VERSION ""

NS_ :

BS_:

BU_: FR_CMR FD_E CLU DATC RR_C_RDR CGW

BO_ 549 CLU_02_100ms: 16 CLU
 SG_ CLU_Crc2Val : 0|16@1+ (1,0) [0|0] ""  FR_CMR,CGW
 SG_ CLU_RefuelWrnSta : 100|2@1+ (1,0) [0|0] ""  CGW
 SG_ CLU_DrvngModSwSta : 104|4@1+ (1,0) [0|0] ""  DATC,FR_CMR,CGW
 SG_ CLU_FuelLvlSta : 108|7@1+ (1,0) [0|0] "%"  CGW
 SG_ CLU_OutTempFSta : 115|8@1+ (1,-40) [0|0] ""  CGW
 SG_ CLU_TerrainModSwSta : 123|3@1+ (1,0) [0|0] ""  CGW
 SG_ CLU_AlvCnt2Val : 16|8@1+ (1,0) [0|0] ""  FR_CMR,CGW
 SG_ CLU_OutTempCSta : 24|8@1+ (1,-40) [0|0] ""  FR_CMR,CGW
 SG_ CLU_DTEVal : 32|10@1+ (1,0) [0|0] ""  CGW
 SG_ CLU_TripUnitSta : 44|2@1+ (1,0) [0|0] ""  CGW
 SG_ CLU_AvgFuelCnsmptnVal : 46|10@1+ (0.1,0) [0|0] ""  CGW
 SG_ CLU_AvgFuelCnsmptnUnitSta : 56|2@1+ (1,0) [0|0] ""  CGW
 SG_ CLU_LoFuelWrngSta : 58|2@1+ (1,0) [0|0] ""  CGW
 SG_ CLU_RefuelDetSta : 60|2@1+ (1,0) [0|0] ""  CGW
 SG_ CLU_TerrainMainSwSta : 62|2@1+ (1,0) [0|0] ""  CGW
 SG_ CLU_LngSta : 64|5@1+ (1,0) [0|0] ""  CGW
 SG_ CLU_SRSWrngLmpSta : 69|3@1+ (1,0) [0|0] ""  CGW
 SG_ CLU_OdoVal : 72|24@1+ (0.1,0) [0|0] "km"  RR_C_RDR,CGW
 SG_ CLU_DawLastBrkTimeVal : 96|4@1+ (1,0) [0|0] ""  FR_CMR,CGW

BO_ 1099 WPC_01_200ms: 8 CGW
 SG_ USM_CmdWPCSta : 0|2@1+ (1,0) [0|0] ""  CLU
 SG_ WPC_PhnLftWrngSta : 2|3@1+ (1,0) [0|0] ""  CLU

BO_ 1092 SMK_02_200ms: 8 CGW
 SG_ SMK_AuthSta : 29|3@1+ (1,0) [0|0] ""  CLU
 SG_ SMK_CLUAccIndOnReq : 48|2@1+ (1,0) [0|0] ""  CLU

BO_ 282 FR_CMR_01_10ms: 16 FR_CMR
 SG_ HBA_SysOptSta : 24|2@1+ (1,0) [0|0] ""  CLU,CGW
 SG_ HBA_SysSta : 26|3@1+ (1,0) [0|0] ""  CLU,CGW
 SG_ HBA_IndLmpReq : 29|2@1+ (1,0) [0|0] ""  CLU,CGW
 SG_ DAW_LVDA_PUDis : 48|2@1+ (1,0) [0|0] ""  CLU,CGW
 SG_ DAW_LVDA_OptUsmSta : 50|2@1+ (1,0) [0|0] ""  CLU,CGW
 SG_ DAW_OptUsmSta : 52|3@1+ (1,0) [0|0] ""  CLU,CGW
 SG_ DAW_SysSta : 55|4@1+ (1,0) [0|0] ""  CLU,CGW
 SG_ DAW_WrnMsgSta : 59|3@1+ (1,0) [0|0] ""  CLU,CGW
 SG_ DAW_TimeRstReq : 62|2@1+ (1,0) [0|0] ""  CLU,CGW
 SG_ DAW_SnstvtyModRetVal : 64|3@1+ (1,0) [0|0] ""  CLU,CGW

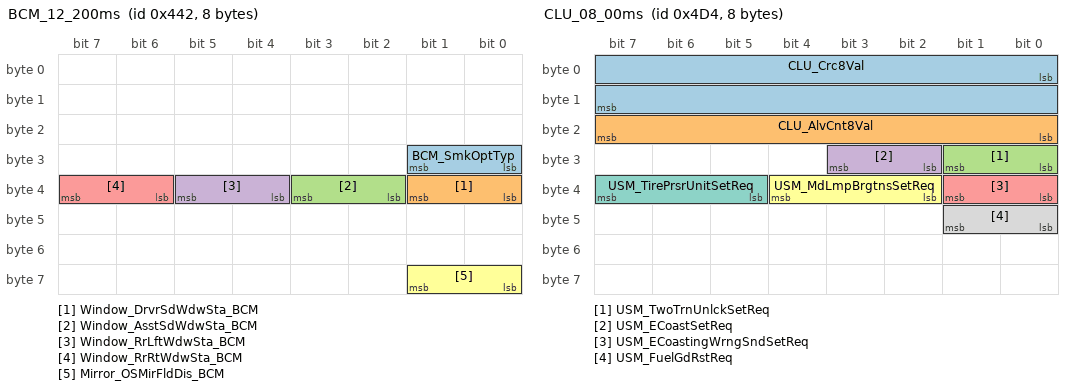
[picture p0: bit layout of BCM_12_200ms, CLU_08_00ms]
BO_ 1090 BCM_12_200ms: 8 CGW
 SG_ BCM_SmkOptTyp : 24|2@1+ (1,0) [0|0] ""  CLU
 SG_ Window_DrvrSdWdwSta_BCM : 32|2@1+ (1,0) [0|0] ""  CLU
 SG_ Window_AsstSdWdwSta_BCM : 34|2@1+ (1,0) [0|0] ""  CLU
 SG_ Window_RrLftWdwSta_BCM : 36|2@1+ (1,0) [0|0] ""  CLU
 SG_ Window_RrRtWdwSta_BCM : 38|2@1+ (1,0) [0|0] ""  CLU
 SG_ Mirror_OSMirFldDis_BCM : 56|2@1+ (1,0) [0|0] ""  CLU

BO_ 1236 CLU_08_00ms: 8 CLU
 SG_ CLU_Crc8Val : 0|16@1+ (1,0) [0|0] ""  CGW
 SG_ CLU_AlvCnt8Val : 16|8@1+ (1,0) [0|0] ""  CGW
 SG_ USM_TwoTrnUnlckSetReq : 24|2@1+ (1,0) [0|0] ""  CGW
 SG_ USM_ECoastSetReq : 26|2@1+ (1,0) [0|0] ""  CGW
 SG_ USM_ECoastingWrngSndSetReq : 32|2@1+ (1,0) [0|0] ""  CGW
 SG_ USM_MdLmpBrgtnsSetReq : 34|3@1+ (1,0) [0|0] ""  CGW
 SG_ USM_TirePrsrUnitSetReq : 37|3@1+ (1,0) [0|0] ""  CGW
 SG_ USM_FuelGdRstReq : 40|2@1+ (1,0) [0|0] ""  CGW

BO_ 256 EMS_02_10ms: 32 CGW
 SG_ ACC_CrsMainSwLmpSta : 104|2@1+ (1,0) [0|0] ""  CLU
 SG_ ACC_CrsSetSwLmpSta : 106|2@1+ (1,0) [0|0] ""  CLU
 SG_ ENG_DpfWrngSta : 232|2@1+ (1,0) [0|0] ""  CLU
 SG_ ENG_BattWrngLmpSta : 234|2@1+ (1,0) [0|0] ""  CLU
 SG_ ENG_OilPrsrWrngLmpSta : 236|2@1+ (1,0) [0|0] ""  CLU
 SG_ ENG_EngClntTempVal : 40|8@1+ (0.75,-48) [0|0] "℃"  CLU,DATC
 SG_ ENG_EngSta : 61|3@1+ (1,0) [0|0] ""  CLU,FR_CMR,RR_C_RDR

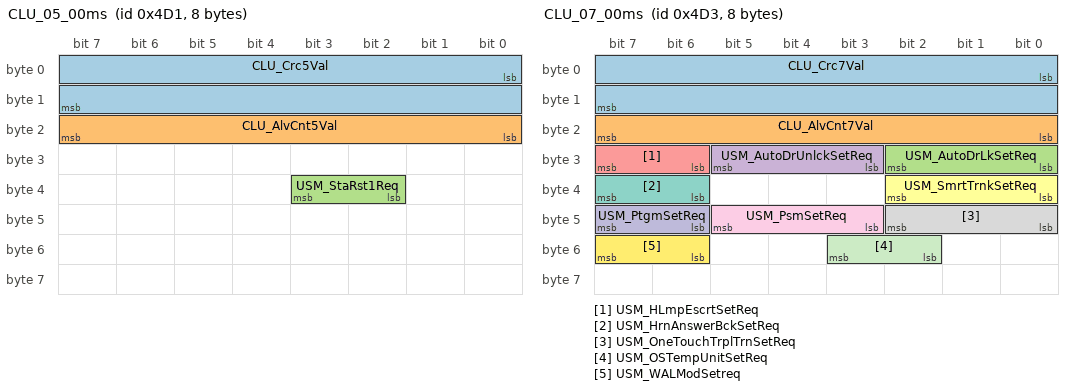
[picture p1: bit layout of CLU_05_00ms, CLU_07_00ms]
BO_ 1233 CLU_05_00ms: 8 CLU
 SG_ CLU_Crc5Val : 0|16@1+ (1,0) [0|0] ""  CGW
 SG_ CLU_AlvCnt5Val : 16|8@1+ (1,0) [0|0] ""  CGW
 SG_ USM_StaRst1Req : 34|2@1+ (1,0) [0|0] ""  DATC,FR_CMR,CGW

BO_ 1235 CLU_07_00ms: 8 CLU
 SG_ CLU_Crc7Val : 0|16@1+ (1,0) [0|0] ""  CGW
 SG_ CLU_AlvCnt7Val : 16|8@1+ (1,0) [0|0] ""  CGW
 SG_ USM_AutoDrLkSetReq : 24|3@1+ (1,0) [0|0] ""  CGW
 SG_ USM_AutoDrUnlckSetReq : 27|3@1+ (1,0) [0|0] ""  CGW
 SG_ USM_HLmpEscrtSetReq : 30|2@1+ (1,0) [0|0] ""  CGW
 SG_ USM_SmrtTrnkSetReq : 32|3@1+ (1,0) [0|0] ""  CGW
 SG_ USM_HrnAnswerBckSetReq : 38|2@1+ (1,0) [0|0] ""  CGW
 SG_ USM_OneTouchTrplTrnSetReq : 40|3@1+ (1,0) [0|0] ""  CGW
 SG_ USM_PsmSetReq : 43|3@1+ (1,0) [0|0] ""  CGW
 SG_ USM_PtgmSetReq : 46|2@1+ (1,0) [0|0] ""  CGW
 SG_ USM_OSTempUnitSetReq : 50|2@1+ (1,0) [0|0] ""  CGW
 SG_ USM_WALModSetreq : 54|2@1+ (1,0) [0|0] ""  CGW

BO_ 933 SCU_FF_02_100ms: 8 CGW
 SG_ SCU_FF_WrnMsgClu : 24|5@1+ (1,0) [0|0] ""  CLU
 SG_ SCU_FF_NPosWshModSta : 43|2@1+ (1,-40) [0|0] "℃"  CLU

BO_ 934 PTGM_01_200ms: 8 CGW
 SG_ PTGM_UsmSetSta : 28|2@1+ (1,0) [0|0] ""  CLU
 SG_ PTGM_HeightSetWarn : 47|1@1+ (1,0) [0|0] ""  CLU

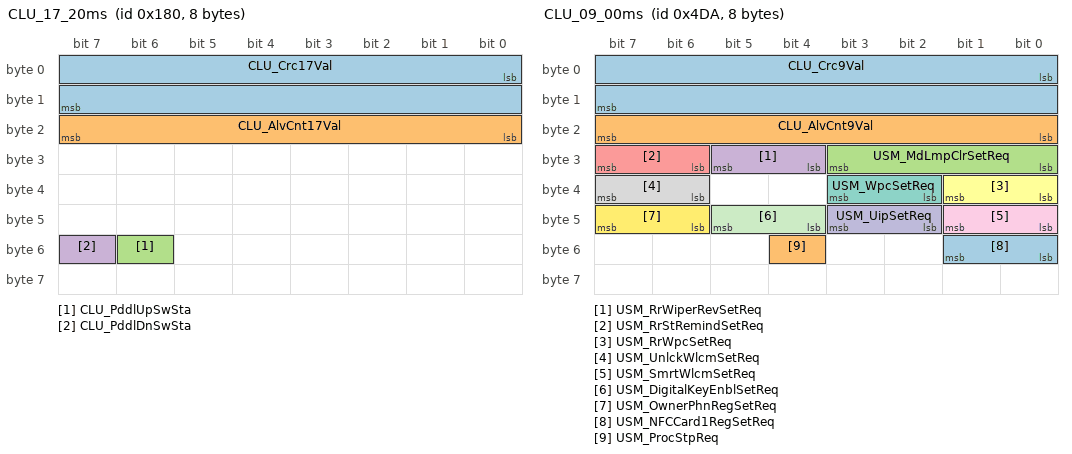
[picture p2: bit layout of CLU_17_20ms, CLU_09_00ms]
BO_ 384 CLU_17_20ms: 8 CLU
 SG_ CLU_Crc17Val : 0|16@1+ (1,0) [0|0] ""  Vector__XXX
 SG_ CLU_AlvCnt17Val : 16|8@1+ (1,0) [0|0] ""  Vector__XXX
 SG_ CLU_PddlUpSwSta : 54|1@1+ (1,0) [0|0] ""  CGW
 SG_ CLU_PddlDnSwSta : 55|1@1+ (1,0) [0|0] ""  CGW

BO_ 928 TPMS_01_200ms: 16 CGW
 SG_ TPMS_FLPosWrngLmpSta : 24|2@1+ (1,0) [0|0] ""  CLU
 SG_ TPMS_FRPosWrngLmpSta : 26|2@1+ (1,0) [0|0] ""  CLU
 SG_ TPMS_RLPosWrngLmpSta : 28|2@1+ (1,0) [0|0] ""  CLU
 SG_ TPMS_RRPosWrngLmpSta : 30|2@1+ (1,0) [0|0] ""  CLU
 SG_ TPMS_FLTirePrsrVal : 32|8@1+ (1,0) [0|0] "PSI"  CLU
 SG_ TPMS_FRTirePrsrVal : 40|8@1+ (1,0) [0|0] "PSI"  CLU
 SG_ TPMS_RLTirePrsrVal : 48|8@1+ (1,0) [0|0] "PSI"  CLU
 SG_ TPMS_RRTirePrsrVal : 56|8@1+ (1,0) [0|0] "PSI"  CLU
 SG_ TPMS_SnsrSta : 64|3@1+ (1,0) [0|0] ""  CLU
 SG_ TPMS_WrngLmpSta : 67|2@1+ (1,0) [0|0] ""  CLU
 SG_ TPMS_TreadWrngLmpSta : 69|2@1+ (1,0) [0|0] ""  CLU
 SG_ TPMS_PrsrUnitSta : 72|2@1+ (1,0) [0|0] ""  CLU

BO_ 1242 CLU_09_00ms: 8 CLU
 SG_ CLU_Crc9Val : 0|16@1+ (1,0) [0|0] ""  CGW
 SG_ CLU_AlvCnt9Val : 16|8@1+ (1,0) [0|0] ""  Vector__XXX
 SG_ USM_MdLmpClrSetReq : 24|4@1+ (1,0) [0|0] ""  CGW
 SG_ USM_RrWiperRevSetReq : 28|2@1+ (1,0) [0|0] ""  CGW
 SG_ USM_RrStRemindSetReq : 30|2@1+ (1,0) [0|0] ""  CGW
 SG_ USM_RrWpcSetReq : 32|2@1+ (1,0) [0|0] ""  CGW
 SG_ USM_WpcSetReq : 34|2@1+ (1,0) [0|0] ""  CGW
 SG_ USM_UnlckWlcmSetReq : 38|2@1+ (1,0) [0|0] ""  CGW
 SG_ USM_SmrtWlcmSetReq : 40|2@1+ (1,0) [0|0] ""  CGW
 SG_ USM_UipSetReq : 42|2@1+ (1,0) [0|0] ""  Vector__XXX
 SG_ USM_DigitalKeyEnblSetReq : 44|2@1+ (1,0) [0|0] ""  Vector__XXX
 SG_ USM_OwnerPhnRegSetReq : 46|2@1+ (1,0) [0|0] ""  Vector__XXX
 SG_ USM_NFCCard1RegSetReq : 48|2@1+ (1,0) [0|0] ""  Vector__XXX
 SG_ USM_ProcStpReq : 52|1@1+ (1,0) [0|0] ""  Vector__XXX

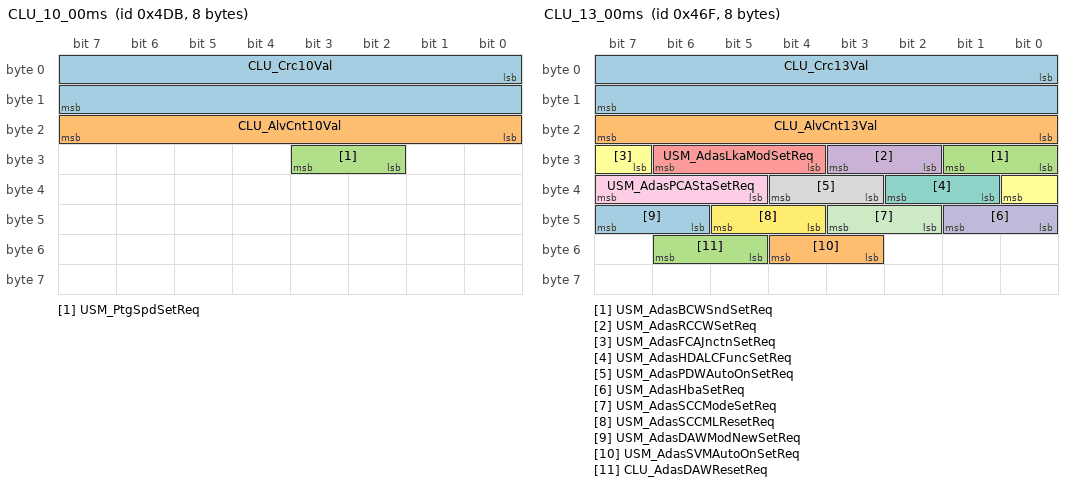
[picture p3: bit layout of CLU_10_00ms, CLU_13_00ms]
BO_ 1243 CLU_10_00ms: 8 CLU
 SG_ CLU_Crc10Val : 0|16@1+ (1,0) [0|0] ""  Vector__XXX
 SG_ CLU_AlvCnt10Val : 16|8@1+ (1,0) [0|0] ""  Vector__XXX
 SG_ USM_PtgSpdSetReq : 26|2@1+ (1,0) [0|0] ""  Vector__XXX

BO_ 304 SBW_SHFTR_FF_01_10ms: 16 CGW
 SG_ SBW_SHFTR_FF_LvrWrngMsg : 56|5@1+ (1,0) [0|0] ""  CLU

BO_ 1135 CLU_13_00ms: 8 CLU
 SG_ CLU_Crc13Val : 0|16@1+ (1,0) [0|0] ""  FR_CMR
 SG_ CLU_AlvCnt13Val : 16|8@1+ (1,0) [0|0] ""  FR_CMR
 SG_ USM_AdasBCWSndSetReq : 24|2@1+ (1,0) [0|0] ""  Vector__XXX
 SG_ USM_AdasRCCWSetReq : 26|2@1+ (1,0) [0|0] ""  RR_C_RDR
 SG_ USM_AdasLkaModSetReq : 28|3@1+ (1,0) [0|0] ""  FR_CMR
 SG_ USM_AdasFCAJnctnSetReq : 31|2@1+ (1,0) [0|0] ""  Vector__XXX
 SG_ USM_AdasHDALCFuncSetReq : 33|2@1+ (1,0) [0|0] ""  Vector__XXX
 SG_ USM_AdasPDWAutoOnSetReq : 35|2@1+ (1,0) [0|0] ""  CGW
 SG_ USM_AdasPCAStaSetReq : 37|3@1+ (1,0) [0|0] ""  Vector__XXX
 SG_ USM_AdasHbaSetReq : 40|2@1+ (1,0) [0|0] ""  FR_CMR
 SG_ USM_AdasSCCModeSetReq : 42|2@1+ (1,0) [0|0] ""  Vector__XXX
 SG_ USM_AdasSCCMLResetReq : 44|2@1+ (1,0) [0|0] ""  Vector__XXX
 SG_ USM_AdasDAWModNewSetReq : 46|2@1+ (1,0) [0|0] ""  FR_CMR
 SG_ USM_AdasSVMAutoOnSetReq : 51|2@1+ (1,0) [0|0] ""  Vector__XXX
 SG_ CLU_AdasDAWResetReq : 53|2@1+ (1,0) [0|0] ""  FR_CMR

BO_ 1253 SMK_01_00ms: 8 CGW
 SG_ DoorLock_PsvDrLkReq : 16|3@1+ (1,0) [0|0] ""  CLU
 SG_ DoorLock_PsvDrUnLkReq : 19|3@1+ (1,0) [0|0] ""  CLU

BO_ 442 RR_C_RDR_02_50ms: 24 RR_C_RDR
 SG_ BCW_Sta : 24|4@1+ (1,0) [0|0] ""  CLU,CGW
 SG_ BCW_LftIndSta : 30|2@1+ (1,0) [0|0] ""  CLU,CGW
 SG_ BCW_RtIndSta : 32|2@1+ (1,0) [0|0] ""  CLU,CGW
 SG_ BCW_LftSndWrngSta : 34|2@1+ (1,0) [0|0] ""  CLU,CGW
 SG_ BCW_RtSndWrngSta : 36|2@1+ (1,0) [0|0] ""  CLU,CGW
 SG_ BCW_LftIndBriLvlVal : 40|8@1+ (1,0) [0|0] ""  CLU,CGW
 SG_ BCW_RtIndBriLvlVal : 48|8@1+ (1,0) [0|0] ""  CLU,CGW
 SG_ BCW_SnstvtyModRetVal : 56|3@1+ (1,0) [0|0] ""  CLU,CGW
 SG_ BCW_IndSta : 59|2@1+ (1,0) [0|0] ""  CLU,CGW
 SG_ BCA_Sta : 64|4@1+ (1,0) [0|0] ""  CLU,CGW
 SG_ BCA_OnOffEquipSta : 68|3@1+ (1,0) [0|0] ""  CLU,CGW
 SG_ BCA_LftWrngSta : 72|2@1+ (1,0) [0|0] ""  CLU,CGW
 SG_ BCA_RtWrngSta : 74|2@1+ (1,0) [0|0] ""  CLU,CGW
 SG_ BCA_R_Brake_Warning : 76|3@1+ (1,0) [0|0] ""  CLU,CGW
 SG_ BCA_Plus_LftWrngSta : 86|2@1+ (1,0) [0|0] ""  CLU,CGW
 SG_ BCA_Plus_RtWrngSta : 88|2@1+ (1,0) [0|0] ""  CLU,CGW
 SG_ BCA_Plus_Sta : 96|4@1+ (1,0) [0|0] ""  CLU,CGW

BO_ 1252 RKE_01_00ms: 8 CGW
 SG_ RKE_BtnReq : 16|4@1+ (1,0) [0|0] ""  CLU

BO_ 160 WHL_01_10ms: 24 CGW
 SG_ WHL_SpdRRVal : 112|14@1+ (0.03125,0) [0|0] "km^h"  CLU,FR_CMR,RR_C_RDR
 SG_ WHL_SpdFLVal : 64|14@1+ (0.03125,0) [0|0] "km^h"  CLU,FR_CMR,RR_C_RDR
 SG_ WHL_SpdFRVal : 80|14@1+ (0.03125,0) [0|0] "km^h"  CLU,FR_CMR,RR_C_RDR
 SG_ WHL_SpdRLVal : 96|14@1+ (0.03125,0) [0|0] "km^h"  CLU,FR_CMR,RR_C_RDR

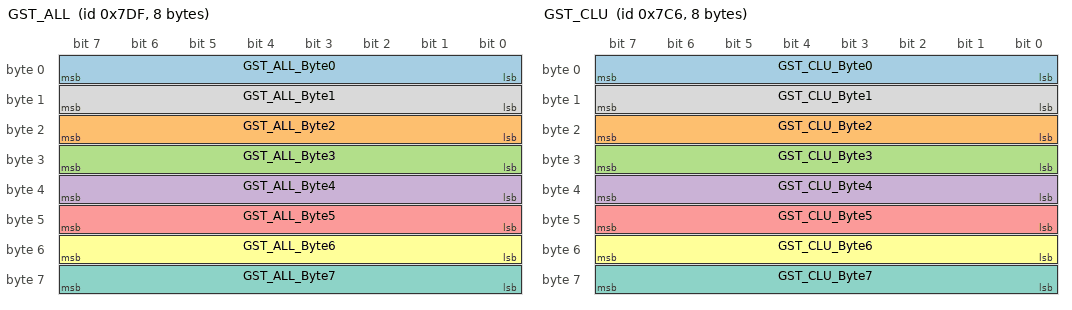
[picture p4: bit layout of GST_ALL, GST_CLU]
BO_ 2015 GST_ALL: 8 CGW
 SG_ GST_ALL_Byte0 : 0|8@1+ (1,0) [0|0] ""  CLU,RR_C_RDR,DATC,FD_E
 SG_ GST_ALL_Byte2 : 16|8@1+ (1,0) [0|0] ""  CLU,RR_C_RDR,DATC,FD_E
 SG_ GST_ALL_Byte3 : 24|8@1+ (1,0) [0|0] ""  CLU,RR_C_RDR,DATC,FD_E
 SG_ GST_ALL_Byte4 : 32|8@1+ (1,0) [0|0] ""  CLU,RR_C_RDR,DATC,FD_E
 SG_ GST_ALL_Byte5 : 40|8@1+ (1,0) [0|0] ""  CLU,RR_C_RDR,DATC,FD_E
 SG_ GST_ALL_Byte6 : 48|8@1+ (1,0) [0|0] ""  CLU,RR_C_RDR,DATC,FD_E
 SG_ GST_ALL_Byte7 : 56|8@1+ (1,0) [0|0] ""  CLU,RR_C_RDR,DATC,FD_E
 SG_ GST_ALL_Byte1 : 8|8@1+ (1,0) [0|0] ""  CLU,RR_C_RDR,DATC,FD_E

BO_ 522 ACU_01_100ms: 16 CGW
 SG_ ACU_SysWrngLmpDis : 24|3@1+ (1,0) [0|0] ""  CLU

BO_ 426 CLU_01_20ms: 16 CLU
 SG_ CLU_Crc1Val : 0|16@1+ (1,0) [0|0] ""  FR_CMR,CGW
 SG_ CLU_AlvCnt1Val : 16|8@1+ (1,0) [0|0] ""  FR_CMR,CGW
 SG_ CLU_PrtyBitSta : 24|2@1+ (1,0) [0|0] "pulse count"  CGW
 SG_ CLU_SpdUnitTyp : 30|2@1+ (1,0) [0|0] ""  FR_CMR,RR_C_RDR,CGW
 SG_ CLU_DisSpdDcmlVal : 32|2@1+ (0.125,0) [0|0] ""  CGW
 SG_ CLU_SWRCCrsMainSwSta : 34|2@1+ (1,0) [0|0] ""  FR_CMR,CGW
 SG_ CLU_SWRCCrsSwSta : 36|3@1+ (1,0) [0|0] ""  FR_CMR,CGW
 SG_ CLU_SWRCLFASwSta : 39|2@1+ (1,0) [0|0] ""  FR_CMR,CGW
 SG_ CLU_SWRCSldMainSwSta : 41|2@1+ (1,0) [0|0] ""  FR_CMR,CGW
 SG_ CLU_RhstaLvlSta : 43|5@1+ (1,0) [0|0] ""  CGW
 SG_ CLU_DisSpdVal : 48|10@1+ (0.5,0) [0|0] "km/h or MPH"  FR_CMR,RR_C_RDR,CGW
 SG_ CLU_OKSwSta : 62|2@1+ (1,0) [0|0] ""  CGW
 SG_ CLU_DisSpdVal_KPH : 64|9@1+ (1,0) [0|0] "km/h"  CGW

BO_ 1990 GST_CLU: 8 CGW
 SG_ GST_CLU_Byte0 : 0|8@1+ (1,0) [0|0] ""  CLU,FD_E
 SG_ GST_CLU_Byte2 : 16|8@1+ (1,0) [0|0] ""  CLU,FD_E
 SG_ GST_CLU_Byte3 : 24|8@1+ (1,0) [0|0] ""  CLU,FD_E
 SG_ GST_CLU_Byte4 : 32|8@1+ (1,0) [0|0] ""  CLU,FD_E
 SG_ GST_CLU_Byte5 : 40|8@1+ (1,0) [0|0] ""  CLU,FD_E
 SG_ GST_CLU_Byte6 : 48|8@1+ (1,0) [0|0] ""  CLU,FD_E
 SG_ GST_CLU_Byte7 : 56|8@1+ (1,0) [0|0] ""  CLU,FD_E
 SG_ GST_CLU_Byte1 : 8|8@1+ (1,0) [0|0] ""  CLU,FD_E

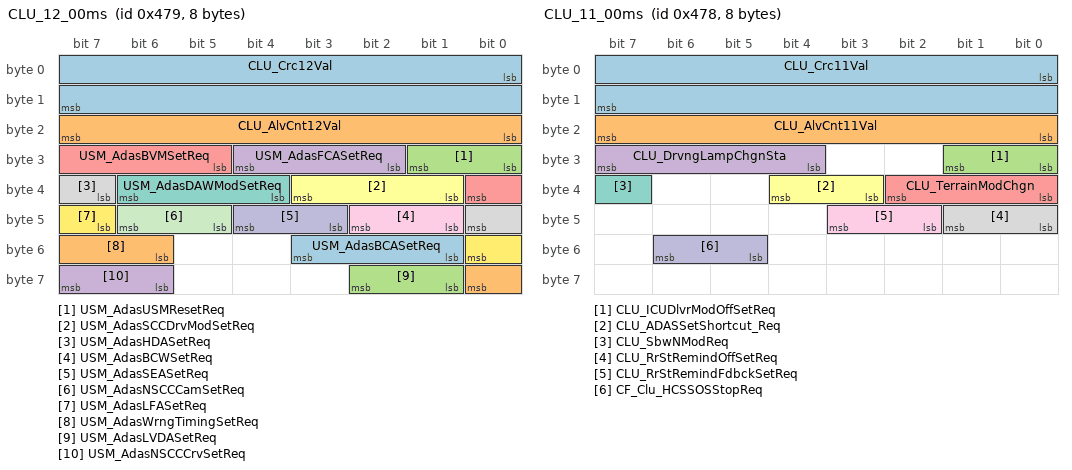
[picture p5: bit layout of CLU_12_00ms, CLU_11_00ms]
BO_ 1145 CLU_12_00ms: 8 CLU
 SG_ CLU_Crc12Val : 0|16@1+ (1,0) [0|0] ""  FR_CMR
 SG_ CLU_AlvCnt12Val : 16|8@1+ (1,0) [0|0] ""  FR_CMR
 SG_ USM_AdasUSMResetReq : 24|2@1+ (1,0) [0|0] ""  FR_CMR,RR_C_RDR
 SG_ USM_AdasFCASetReq : 26|3@1+ (1,0) [0|0] ""  FR_CMR
 SG_ USM_AdasBVMSetReq : 29|4@1+ (1,0) [0|0] ""  Vector__XXX
 SG_ USM_AdasSCCDrvModSetReq : 33|3@1+ (1,0) [0|0] ""  FR_CMR
 SG_ USM_AdasDAWModSetReq : 36|3@1+ (1,0) [0|0] ""  Vector__XXX
 SG_ USM_AdasHDASetReq : 39|2@1+ (1,0) [0|0] ""  FR_CMR
 SG_ USM_AdasBCWSetReq : 41|2@1+ (1,0) [0|0] ""  RR_C_RDR
 SG_ USM_AdasSEASetReq : 43|2@1+ (1,0) [0|0] ""  RR_C_RDR
 SG_ USM_AdasNSCCCamSetReq : 45|2@1+ (1,0) [0|0] ""  FR_CMR
 SG_ USM_AdasLFASetReq : 47|2@1+ (1,0) [0|0] ""  Vector__XXX
 SG_ USM_AdasBCASetReq : 49|3@1+ (1,0) [0|0] ""  RR_C_RDR
 SG_ USM_AdasWrngTimingSetReq : 54|3@1+ (1,0) [0|0] ""  FR_CMR,RR_C_RDR
 SG_ USM_AdasLVDASetReq : 57|2@1+ (1,0) [0|0] ""  FR_CMR
 SG_ USM_AdasNSCCCrvSetReq : 62|2@1+ (1,0) [0|0] ""  CGW

BO_ 1144 CLU_11_00ms: 8 CLU
 SG_ CLU_Crc11Val : 0|16@1+ (1,0) [0|0] ""  Vector__XXX
 SG_ CLU_AlvCnt11Val : 16|8@1+ (1,0) [0|0] ""  Vector__XXX
 SG_ CLU_ICUDlvrModOffSetReq : 24|2@1+ (1,0) [0|0] ""  CGW
 SG_ CLU_DrvngLampChgnSta : 28|4@1+ (1,0) [0|0] ""  CGW
 SG_ CLU_TerrainModChgn : 32|3@1+ (1,0) [0|0] ""  CGW
 SG_ CLU_ADASSetShortcut_Req : 35|2@1+ (1,0) [0|0] ""  Vector__XXX
 SG_ CLU_SbwNModReq : 39|1@1+ (1,0) [0|0] ""  CGW
 SG_ CLU_RrStRemindOffSetReq : 40|2@1+ (1,0) [0|0] ""  CGW
 SG_ CLU_RrStRemindFdbckSetReq : 42|2@1+ (1,0) [0|0] ""  CGW
 SG_ CF_Clu_HCSSOSStopReq : 53|2@1+ (1,0) [0|0] ""  Vector__XXX

BO_ 416 ADAS_CMD_20_20ms: 32 FR_CMR
 SG_ SCC_NSCCOpSta : 104|2@1+ (1,0) [0|0] ""  CLU,CGW
 SG_ SCC_NSCCOnOffSta : 106|2@1+ (1,0) [0|0] ""  CLU,CGW
 SG_ SCC_ObjSta : 108|3@1+ (1,0) [0|0] ""  CLU,CGW
 SG_ SCC_SnstvtyModRetVal : 112|3@1+ (1,0) [0|0] ""  CLU,CGW
 SG_ SCC_NSCCAutoSetSpdUpdtSta : 115|2@1+ (1,0) [0|0] ""  CLU,CGW
 SG_ SCC_NSCCInfoPUDis : 117|3@1+ (1,0) [0|0] ""  CLU,CGW
 SG_ SCC_TrgtDstVal : 192|11@1+ (0.1,0) [0|0] "m"  CLU,CGW
 SG_ SCC_ObjDstVal : 24|11@1+ (0.1,0) [0|0] "m"  CLU,CGW
 SG_ SCC_ObjLatPosVal : 47|9@1+ (0.1,-20) [0|0] "m"  CLU,CGW
 SG_ SCC_SysFlrSta : 64|2@1+ (1,0) [0|0] ""  CLU,CGW
 SG_ SCC_MainOnOffSta : 66|2@1+ (1,0) [0|0] ""  CLU,CGW
 SG_ SCC_OpSta : 68|3@1+ (1,0) [0|0] ""  CLU,CGW
 SG_ SCC_TakeoverReq : 72|2@1+ (1,0) [0|0] ""  CLU,CGW
 SG_ SCC_InfoDis : 74|3@1+ (1,0) [0|0] ""  CLU,CGW
 SG_ SCC_DrvAlrtDis : 77|2@1+ (1,0) [0|0] ""  CLU,CGW
 SG_ SCC_ObjDstLvlVal : 80|8@1+ (1,0) [0|0] ""  CLU,CGW
 SG_ SCC_HeadwayDstSetVal : 88|4@1+ (1,0) [0|0] ""  CLU,CGW
 SG_ SCC_NSCCAutoSetSpdSta : 94|2@1+ (1,0) [0|0] ""  CLU,CGW
 SG_ SCC_TrgtSpdSetVal : 96|8@1+ (1,0) [0|0] "km/h or MPH"  CLU,CGW

CM_ BO_ 522 "[P] Periodic";
CM_ SG_ 522 ACU_SysWrngLmpDis "ACU_SystemWarningLampDisplay ##2G##ACU - ACU14 - CF_SWL_Ind";
CM_ BO_ 416 "[P] Periodic";
CM_ SG_ 416 SCC_NSCCOpSta "SCC_NSCCOperatingStatus ##2G##SCC - SCC11 - NSCC_Camera_Act";
CM_ SG_ 416 SCC_NSCCOnOffSta "SCC_NSCCOnOffStatus ##2G##SCC - SCC13 - NSCC_Zone_USM";
CM_ SG_ 416 SCC_ObjSta "SCC_ObjectState";
CM_ SG_ 416 SCC_SnstvtyModRetVal "SCC_SensitivityModeReturnValue ##2G##SCC - SCC13 - SCCDrvModeRValue";
CM_ SG_ 416 SCC_NSCCAutoSetSpdUpdtSta "SCC_NSCCAutoSetSpeedUpdateStatus ##2G##LDW_LKA - HDA11 - CF_HDA_AutoSetSpdUpdate";
CM_ SG_ 416 SCC_NSCCInfoPUDis "SCC_NSCCInformationPopUpDisplay";
CM_ SG_ 416 SCC_TrgtDstVal "SCC_TargetDistanceValue";
CM_ SG_ 416 SCC_ObjDstVal "SCC_ObjectDistanceValue ##2G##SCC - SCC11 - SCC_ObjDist";
CM_ SG_ 416 SCC_ObjLatPosVal "SCC_ObjectLateralPositionValue ##2G##SCC - SCC11 - SCC_ObjLatPos";
CM_ SG_ 416 SCC_SysFlrSta "SCC_SystemFailureStatus ##2G##SCC - SCC12 - SCCFailInfo";
CM_ SG_ 416 SCC_MainOnOffSta "SCC_MainOnOffStatus ##2G##SCC - SCC11 - MainMode_SCC";
CM_ SG_ 416 SCC_OpSta "SCC_OperatingStatus ##2G##SCC - SCC14 - SCCMode2";
CM_ SG_ 416 SCC_TakeoverReq "SCC_TakeoverRequest ##2G##SCC - SCC12 - TakeOverReq";
CM_ SG_ 416 SCC_InfoDis "SCC_InformationDisplay ##2G##SCC - SCC11 - SCCInfoDisplay";
CM_ SG_ 416 SCC_DrvAlrtDis "SCC_DriverAlertDisplay ##2G##SCC - SCC11 - DriverAlertDisplay";
CM_ SG_ 416 SCC_ObjDstLvlVal "SCC_ObjectDistanceLevelValue ##2G##SCC - SCC14 - ObjGap";
CM_ SG_ 416 SCC_HeadwayDstSetVal "SCC_HeadwayDistanceSettingValue ##2G##SCC - SCC11 - TauGapSet";
CM_ SG_ 416 SCC_NSCCAutoSetSpdSta "SCC_NSCCAutoSetSpeedStatus ##2G##LDW_LKA - HDA11 - CF_HDA_AutoSetSpdEnable";
CM_ SG_ 416 SCC_TrgtSpdSetVal "SCC_TargetSpeedSettingValue ##2G##SCC - SCC11 - VSetDis";
CM_ BO_ 1090 "[PE] Periodic and On Event";
CM_ SG_ 1090 BCM_SmkOptTyp "BCM_SmkOptionType ##2G##BCM - BCMmsg17 - C_SMKOption";
CM_ SG_ 1090 Window_DrvrSdWdwSta_BCM "Window_DriverSideWindowStatus ##2G##BCM - BCMmsg22 - C_DrvWindowOpenState";
CM_ SG_ 1090 Window_AsstSdWdwSta_BCM "Window_AssistantSideWindowStatus ##2G##BCM - BCMmsg22 - C_AstWindowOpenState";
CM_ SG_ 1090 Window_RrLftWdwSta_BCM "Window_RearLeftWindowStatus ##2G##BCM - BCMmsg22 - C_RLWindowOpenState";
CM_ SG_ 1090 Window_RrRtWdwSta_BCM "Window_RearRightPowerWindowStatus ##2G##BCM - BCMmsg22 - C_RRWindowOpenState";
CM_ SG_ 1090 Mirror_OSMirFldDis_BCM "Mirror_OutSideMirrorFoldDisplay ##2G##BCM - BCMmsg17 - C_OSMirrorFoldState";
CM_ BO_ 426 "[P] Periodic";
CM_ SG_ 426 CLU_Crc1Val "CLU_CyclicRedundancyCheck1Value";
CM_ SG_ 426 CLU_AlvCnt1Val "CLU_AliveCounter1Value";
CM_ SG_ 426 CLU_PrtyBitSta "CLU_ParityBitValue(2nd general: CLU11/CF_Clu_ParityBit1)";
CM_ SG_ 426 CLU_SpdUnitTyp "CLU_SpeedUnitType";
CM_ SG_ 426 CLU_DisSpdDcmlVal "CLU_DisplaySpeedDecimalValue";
CM_ SG_ 426 CLU_SWRCCrsMainSwSta "CLU_SWRCCrsMainSwSta";
CM_ SG_ 426 CLU_SWRCCrsSwSta "CLU_SWRCCrsSwSta";
CM_ SG_ 426 CLU_SWRCLFASwSta "SWRC_LFASwitchStatus";
CM_ SG_ 426 CLU_SWRCSldMainSwSta "SWRC_SpeedLimiterMainSwitchStatus";
CM_ SG_ 426 CLU_RhstaLvlSta "CLU_RheostatLevelStatus";
CM_ SG_ 426 CLU_DisSpdVal "CLU_DisplaySpeedValue";
CM_ SG_ 426 CLU_OKSwSta "OK Switch On/Off State";
CM_ SG_ 426 CLU_DisSpdVal_KPH "CLU_DisplaySpeedValue_KPH";
CM_ BO_ 549 "[P] Periodic";
CM_ SG_ 549 CLU_Crc2Val "CLU_CyclicRedundancyCheck2Value";
CM_ SG_ 549 CLU_RefuelWrnSta "CLU_RefuelWarningStatus";
CM_ SG_ 549 CLU_DrvngModSwSta "CLU_DrivingModeSwitchStatus";
CM_ SG_ 549 CLU_FuelLvlSta "CLU_FuelLevelStatus";
CM_ SG_ 549 CLU_OutTempFSta "CLU_DisplayOutsideTemperatureFStatus";
CM_ SG_ 549 CLU_TerrainModSwSta "CLU_TerrainModeSwitchStatus";
CM_ SG_ 549 CLU_AlvCnt2Val "CLU_AliveCounter2Value";
CM_ SG_ 549 CLU_OutTempCSta "CLU_DisplayOutsideTemperatureCStatus";
CM_ SG_ 549 CLU_DTEVal "CLU_DTEValue";
CM_ SG_ 549 CLU_TripUnitSta "CLU_TripUnitStatus";
CM_ SG_ 549 CLU_AvgFuelCnsmptnVal "CLU_AverageFuelConsumptionValue";
CM_ SG_ 549 CLU_AvgFuelCnsmptnUnitSta "CLU_AverageFuelConsumptionUnitStatus";
CM_ SG_ 549 CLU_LoFuelWrngSta "CLU_LowFuelWarningStatus";
CM_ SG_ 549 CLU_RefuelDetSta "CLU_RefuelDetectedStatus";
CM_ SG_ 549 CLU_TerrainMainSwSta "CLU_TerrainMainSwitchStatus";
CM_ SG_ 549 CLU_LngSta "CLU_LanguageStatus";
CM_ SG_ 549 CLU_SRSWrngLmpSta "CLU_SRSWarningLampStatus";
CM_ SG_ 549 CLU_OdoVal "CLU_OdometerValue";
CM_ SG_ 549 CLU_DawLastBrkTimeVal "CLU_DawLastBreakTimeValue";
CM_ BO_ 1233 "[EC] On Event and On Change";
CM_ SG_ 1233 CLU_Crc5Val "CLU_CyclicRedundancyCheck5Value";
CM_ SG_ 1233 CLU_AlvCnt5Val "CLU_AliveCounter5Value";
CM_ SG_ 1233 USM_StaRst1Req "USM_StatusReset1Request";
CM_ BO_ 1235 "[EC] On Event and On Change";
CM_ SG_ 1235 CLU_Crc7Val "CLU_CyclicRedundancyCheck7Value";
CM_ SG_ 1235 CLU_AlvCnt7Val "CLU_AliveCounter7Value";
CM_ SG_ 1235 USM_AutoDrLkSetReq "USM_AutoDoorLockSetRequest";
CM_ SG_ 1235 USM_AutoDrUnlckSetReq "USM_AutoDoorUnlockSetRequest";
CM_ SG_ 1235 USM_HLmpEscrtSetReq "USM_HeadLampEscortSetRequest";
CM_ SG_ 1235 USM_SmrtTrnkSetReq "USM_SmartTrunkSetRequest";
CM_ SG_ 1235 USM_HrnAnswerBckSetReq "USM_HornAnswerBackSetRequest";
CM_ SG_ 1235 USM_OneTouchTrplTrnSetReq "USM_OneTouchTripleTurnSetRequest";
CM_ SG_ 1235 USM_PsmSetReq "USM_PsmSetRequest";
CM_ SG_ 1235 USM_PtgmSetReq "USM_PtgmSetRequest";
CM_ SG_ 1235 USM_OSTempUnitSetReq "USM_OutsideTemperatureUnitSetValue";
CM_ SG_ 1235 USM_WALModSetreq "USM_WalkAwayLockModeSetRequest(2nd General : CF_Clu_WALNValueset))";
CM_ BO_ 1236 "[EC] On Event and On Change";
CM_ SG_ 1236 CLU_Crc8Val "CLU_CyclicRedundancyCheck8Value";
CM_ SG_ 1236 CLU_AlvCnt8Val "CLU_AliveCounter8Value";
CM_ SG_ 1236 USM_TwoTrnUnlckSetReq "USM_TwoTurnUnlockSetRequest";
CM_ SG_ 1236 USM_ECoastSetReq "USM_ECoastingSetRequset";
CM_ SG_ 1236 USM_ECoastingWrngSndSetReq "USM_ECoastingWarningSoundSetRequset";
CM_ SG_ 1236 USM_MdLmpBrgtnsSetReq "USM_MoodLampBrightnessSetRequest";
CM_ SG_ 1236 USM_TirePrsrUnitSetReq "USM_TirePressureUnitSetRequest";
CM_ SG_ 1236 USM_FuelGdRstReq "USM_FuelGuideResetRequest";
CM_ BO_ 1242 "[EC] On Event and On Change";
CM_ SG_ 1242 CLU_Crc9Val "CLU_CyclicRedundancyCheck9Value";
CM_ SG_ 1242 CLU_AlvCnt9Val "CLU_AliveCounter9Value";
CM_ SG_ 1242 USM_MdLmpClrSetReq "USM_MoodLampColorSetRequest";
CM_ SG_ 1242 USM_RrWiperRevSetReq "USM_RearWiperReverseSetRequest";
CM_ SG_ 1242 USM_RrStRemindSetReq "USM_RrseatReminderSetRequest(2nd :General: CLU20/CF_Clu_RrSeatRemindNValueSet)";
CM_ SG_ 1242 USM_RrWpcSetReq "USM_RearWpcSetRequest";
CM_ SG_ 1242 USM_WpcSetReq "USM_WpcSetRequest";
CM_ SG_ 1242 USM_UnlckWlcmSetReq "USM_UnlockWelcomeSetRequest";
CM_ SG_ 1242 USM_SmrtWlcmSetReq "USM_SmartWelcomeSetRequest";
CM_ SG_ 1242 USM_UipSetReq "2nd General: CF_Clu_UIPNValueSet";
CM_ SG_ 1242 USM_DigitalKeyEnblSetReq "Request to set the Digital Key ON or OFF(2nd General DB: CF_Clu_DigitalKeyNValueSet)";
CM_ SG_ 1242 USM_OwnerPhnRegSetReq "2nd general DB: CF_Clu_OwnerPhoneNValueSet";
CM_ SG_ 1242 USM_NFCCard1RegSetReq "2nd General DB:CF_Clu_NFCCard1NValueSet";
CM_ SG_ 1242 USM_ProcStpReq "2nd General DB:CF_Clu_ProcessStopReq";
CM_ BO_ 1243 "[EC] On Event and On Change";
CM_ SG_ 1243 CLU_Crc10Val "CLU_CyclicRedundancyCheck10Value";
CM_ SG_ 1243 CLU_AlvCnt10Val "CLU_AliveCounter10Value";
CM_ SG_ 1243 USM_PtgSpdSetReq "USM_PtgSpeedSetRequest";
CM_ BO_ 1144 "[EC] On Event and On Change";
CM_ SG_ 1144 CLU_Crc11Val "CLU_CyclicRedundancyCheck11Value";
CM_ SG_ 1144 CLU_AlvCnt11Val "CLU_AliveCounter11Value";
CM_ SG_ 1144 CLU_ICUDlvrModOffSetReq "CLU_ICUDeliveryModeOffSetRequest";
CM_ SG_ 1144 CLU_DrvngLampChgnSta "CLU_DrivingModeLampChangingStatus";
CM_ SG_ 1144 CLU_TerrainModChgn "2nd generation signal : CF_Clu_TerrainModeChange";
CM_ SG_ 1144 CLU_ADASSetShortcut_Req "Shortcut signal for ADAS menu quick launch";
CM_ SG_ 1144 CLU_SbwNModReq "CLU_SbwNModeRequest(2nd general: CLU22/CF_Clu_SbwNModeReq)";
CM_ SG_ 1144 CLU_RrStRemindOffSetReq "CLU_RrseatReminderOffSetRequest(2nd general:CLU20/CF_Clu_RrSeatRemindOff)";
CM_ SG_ 1144 CLU_RrStRemindFdbckSetReq "CLU_RrseatReminderFeedbackRequest (2nd general : CLU20/CF_Clu_RrSeatRemindFeedback)";
CM_ SG_ 1144 CF_Clu_HCSSOSStopReq "Request to stop the SOS call";
CM_ BO_ 1145 "[EC] On Event and On Change";
CM_ SG_ 1145 CLU_Crc12Val "CLU_CyclicRedundancyCheck12Value";
CM_ SG_ 1145 CLU_AlvCnt12Val "CLU_AliveCounter12Value";
CM_ SG_ 1145 USM_AdasUSMResetReq "USM_AdasUSMResetRequest";
CM_ SG_ 1145 USM_AdasFCASetReq "USM_AdasFCASetRequest";
CM_ SG_ 1145 USM_AdasBVMSetReq "USM_AdasBVMSetRequest";
CM_ SG_ 1145 USM_AdasSCCDrvModSetReq "USM_AdasSCCDrivingModeSetRequest";
CM_ SG_ 1145 USM_AdasDAWModSetReq "USM_AdasDAWModeSetRequest";
CM_ SG_ 1145 USM_AdasHDASetReq "USM_AdasHDASetRequest";
CM_ SG_ 1145 USM_AdasBCWSetReq "USM_AdasBCWSetRequest";
CM_ SG_ 1145 USM_AdasSEASetReq "USM_AdasSEASetRequest";
CM_ SG_ 1145 USM_AdasNSCCCamSetReq "USM_AdasNSCCCamSetRequest";
CM_ SG_ 1145 USM_AdasLFASetReq "USM_AdasLFASetRequest";
CM_ SG_ 1145 USM_AdasBCASetReq "USM_AdasBCASetRequest";
CM_ SG_ 1145 USM_AdasWrngTimingSetReq "USM_AdasWarningTimingSetRequest";
CM_ SG_ 1145 USM_AdasLVDASetReq "USM_AdasLVDASetRequest";
CM_ SG_ 1145 USM_AdasNSCCCrvSetReq "USM_AdasNSCCCrvSetRequest";
CM_ BO_ 1135 "[EC] On Event and On Change";
CM_ SG_ 1135 CLU_Crc13Val "CLU_CyclicRedundancyCheck13Value";
CM_ SG_ 1135 CLU_AlvCnt13Val "CLU_AliveCounter13Value";
CM_ SG_ 1135 USM_AdasBCWSndSetReq "USM_AdasBCWSndSetRequest";
CM_ SG_ 1135 USM_AdasRCCWSetReq "USM_AdasRCCWSetRequest";
CM_ SG_ 1135 USM_AdasLkaModSetReq "USM_AdasLkaModSetRequest";
CM_ SG_ 1135 USM_AdasFCAJnctnSetReq "USM_AdasFCAJnctnSetReq";
CM_ SG_ 1135 USM_AdasHDALCFuncSetReq "USM_AdasHDALaneChangeFunctionSetRequest";
CM_ SG_ 1135 USM_AdasPDWAutoOnSetReq "USM_AdasPDWAutoOnSetReq";
CM_ SG_ 1135 USM_AdasPCAStaSetReq "USM_AdasPCAStaSetReq";
CM_ SG_ 1135 USM_AdasHbaSetReq "USM_AdasHbaSetReq";
CM_ SG_ 1135 USM_AdasSCCModeSetReq "USM_AdasSCCModeSetReq";
CM_ SG_ 1135 USM_AdasSCCMLResetReq "USM_AdasSCCMLResetReq";
CM_ SG_ 1135 USM_AdasDAWModNewSetReq "USM_AdasDAWModeNewSetRequest (2nd general : CLU19/CF_AVN_DAWModeNValueSet_New)";
CM_ SG_ 1135 USM_AdasSVMAutoOnSetReq "USM_AdasSVMAutoOnSetRequest(2nd General signal : CF_AVN_SVMAutoOnNvalueSet)";
CM_ SG_ 1135 CLU_AdasDAWResetReq "Request to DAWReset";
CM_ BO_ 384 "[P] Periodic";
CM_ SG_ 384 CLU_Crc17Val "CLU_CyclicRedundancyCheck17Value";
CM_ SG_ 384 CLU_AlvCnt17Val "CLU_AliveCounter17Value";
CM_ SG_ 384 CLU_PddlUpSwSta "CLU_PaddUpSwState(2nd Generation Signal : CF_Clu_PaddUpSwState)";
CM_ SG_ 384 CLU_PddlDnSwSta "CLU_PaddleDonwSwState(2nd Generation Signal : CF_Clu_PaddDownSwState)";
CM_ BO_ 256 "[P] Periodic";
CM_ SG_ 256 ACC_CrsMainSwLmpSta "ACC_CruiseMainSwLampStatus ##2G##EMS - EMS16 - CRUISE_LAMP_M";
CM_ SG_ 256 ACC_CrsSetSwLmpSta "ACC_CruiseSetSwLampStatus ##2G##EMS - EMS16 - CRUISE_LAMP_S";
CM_ SG_ 256 ENG_DpfWrngSta "ENG_DpfWarningStatus ##2G##EMS - EMS19 - DPF_LAMP_STAT";
CM_ SG_ 256 ENG_BattWrngLmpSta "ENG_BatteryWarningLampStatus ##2G##EMS - EMS19 - BAT_LAMP_STAT";
CM_ SG_ 256 ENG_OilPrsrWrngLmpSta "ENG_OilPressureWarningLampStatus ##2G##EMS - EMS19 - CF_Ems_OPSFail";
CM_ SG_ 256 ENG_EngClntTempVal "ENG_EngineCoolantTemperatureValue ##2G##EMS - EMS12 - TEMP_ENG";
CM_ SG_ 256 ENG_EngSta "ENG_EngineStatus ##2G##EMS - EMS16 - ENG_STAT";
CM_ BO_ 282 "[P] Periodic";
CM_ SG_ 282 HBA_SysOptSta "HBA_SystemOptionStatus ##2G##LDW_LKA - LKA11 - CF_HBA_Opt_USM";
CM_ SG_ 282 HBA_SysSta "HBA_SystemStatus ##2G##LDW_LKA - LKA11 - CF_HBA_SysState";
CM_ SG_ 282 HBA_IndLmpReq "HBA_IndicatorLampRequest ##2G##LDW_LKA - LKA11 - CF_HBA_Lamp";
CM_ SG_ 282 DAW_LVDA_PUDis "LVDA_PopUpDisplay ##2G##LDW_LKA - LKA12 - CF_LeadVehDptAlert_Display";
CM_ SG_ 282 DAW_LVDA_OptUsmSta "LVDA_OptionUsmStatus ##2G##LDW_LKA - LKA12 - CF_LeadVehDptAlert_USM";
CM_ SG_ 282 DAW_OptUsmSta "DAW_OptionUsmStatus ##2G##LDW_LKA - LKA12 - CF_DAW_Opt_USM_NEW";
CM_ SG_ 282 DAW_SysSta "DAW_SystemStatus ##2G##LDW_LKA - LKA12 - CF_DAW_Status";
CM_ SG_ 282 DAW_WrnMsgSta "DAW_WarningMessageStatus ##2G##LDW_LKA - LKA12 - CF_DAW_Warn";
CM_ SG_ 282 DAW_TimeRstReq "DAW_TimeResetRequest ##2G##LDW_LKA - LKA12 - CF_DAW_TimeReset";
CM_ SG_ 282 DAW_SnstvtyModRetVal "DAW_SensitivityModeReturnValue##2G##LDW_LKA - LKA12 - CF_DAW_Opt_USM";
CM_ BO_ 2015 "[EW] On Event and On Write";
CM_ BO_ 1990 "[EW] On Event and On Write";
CM_ BO_ 934 "[PE] Periodic and On Event";
CM_ SG_ 934 PTGM_UsmSetSta "PTGM_UsmSettingStatus";
CM_ BO_ 1252 "[EC] On Event and On Change";
CM_ SG_ 1252 RKE_BtnReq "RemoteKey_ButtonRequest ##2G##BCM - BCMmsg01 - C_RKECmd";
CM_ BO_ 442 "[P] Periodic";
CM_ SG_ 442 BCW_Sta "BCW_Status ##2G##BCW - BCW11 - CF_BCW_Stat";
CM_ SG_ 442 BCW_LftIndSta "BCW_LeftIndicatorStatus ##2G##BCW - BCW11 - CF_BCW_IndLeft";
CM_ SG_ 442 BCW_RtIndSta "BCW_RightIndicatorStatus ##2G##BCW - BCW11 - CF_BCW_IndRight";
CM_ SG_ 442 BCW_LftSndWrngSta "BCW_LeftSoundWarningStatus ##2G##BCW - BCW11 - CF_FL_SndWan";
CM_ SG_ 442 BCW_RtSndWrngSta "BCW_RightSoundWarningStatus ##2G##BCW - BCW11 - CF_FR_SndWan";
CM_ SG_ 442 BCW_LftIndBriLvlVal "BCW_LeftIndicatorBrightnessLevelValue ##2G##BCW - BCW11 - CF_BCW_IndBriLeft";
CM_ SG_ 442 BCW_RtIndBriLvlVal "BCW_RightIndicatorBrightnessLevelValue ##2G##BCW - BCW11 - CF_BCW_IndBriRight";
CM_ SG_ 442 BCW_SnstvtyModRetVal "BCW_SensitivityModeReturnValue ##2G##BCW - BCW12 - CF_BCW_DrvSetState";
CM_ SG_ 442 BCA_Sta "BCA_Status ##2G##BCW - BCA11 - CF_BCA_State";
CM_ SG_ 442 BCA_OnOffEquipSta "BCA_OnOffEquipmentStatus ##2G##BCW - BCW12 - CF_BCA_USM";
CM_ SG_ 442 BCA_LftWrngSta "BCA_LeftWarningStatus ##2G##BCW - BCA11 - CF_BCA_Warning";
CM_ SG_ 442 BCA_RtWrngSta "BCA_RightWarningStatus ##2G##BCW - BCA11 - CF_BCA_Warning";
CM_ SG_ 442 BCA_R_Brake_Warning "BCA-R Warning Off/Left/Right";
CM_ SG_ 442 BCA_Plus_LftWrngSta "BCA_Plus_LeftWarningStatus";
CM_ SG_ 442 BCA_Plus_RtWrngSta "BCA_Plus_RightWarningStatus";
CM_ SG_ 442 BCA_Plus_Sta "BCA_Plus_Status";
CM_ BO_ 304 "[P] Periodic";
CM_ SG_ 304 SBW_SHFTR_FF_LvrWrngMsg "SBW_SHFTR_FF_Warning Message
 ##2G##LVR_FF - LVR12 - CF_Lvr_Wrn";
CM_ BO_ 933 "[P] Periodic";
CM_ SG_ 933 SCU_FF_WrnMsgClu "SCU_FF_WarningMessageCluster";
CM_ SG_ 933 SCU_FF_NPosWshModSta "SCU_FF_NPositionWashModeState";
CM_ BO_ 1253 "[EC] On Event and On Change";
CM_ SG_ 1253 DoorLock_PsvDrLkReq "DoorLock_PassiveDoorLockRequest ##2G##SMK - SMKmsg01 - C_PassiveAccessLock";
CM_ SG_ 1253 DoorLock_PsvDrUnLkReq "DoorLock_PassiveDoorUnLockRequest ##2G##SMK - SMKmsg01 - C_PassiveAccessUnlock";
CM_ BO_ 1092 "[PE] Periodic and On Event";
CM_ SG_ 1092 SMK_AuthSta "SMK_AuthentificationStatus ##2G##SMK - SMKmsg18 - C_AuthState";
CM_ SG_ 1092 SMK_CLUAccIndOnReq "SMK_ClusterACCIndicatorOnRequest ##2G##SMK - SMKmsg19 - C_AccINDforCLU";
CM_ BO_ 928 "[P] Periodic";
CM_ SG_ 928 TPMS_FLPosWrngLmpSta "TPMS_FrontLeftPositionWarningLampStatus ##2G##IBU - TPMS11 - POS_FL_W_LAMP";
CM_ SG_ 928 TPMS_FRPosWrngLmpSta "TPMS_FrontRightPositionWarningLampStatus ##2G##IBU - TPMS11 - POS_FR_W_LAMP";
CM_ SG_ 928 TPMS_RLPosWrngLmpSta "TPMS_RearLeftPositionWarningLampStatus ##2G##IBU - TPMS11 - POS_RL_W_LAMP";
CM_ SG_ 928 TPMS_RRPosWrngLmpSta "TPMS_RearRightPositionWarningLampStatus ##2G##IBU - TPMS11 - POS_RR_W_LAMP";
CM_ SG_ 928 TPMS_FLTirePrsrVal "TPMS_FrontLeftTirePressureValue ##2G##IBU - TPMS11 - PRESSURE_FL";
CM_ SG_ 928 TPMS_FRTirePrsrVal "TPMS_FrontRightTirePressureValue ##2G##IBU - TPMS11 - PRESSURE_FR";
CM_ SG_ 928 TPMS_RLTirePrsrVal "TPMS_RearLeftTirePressureValue ##2G##IBU - TPMS11 - PRESSURE_RL";
CM_ SG_ 928 TPMS_RRTirePrsrVal "TPMS_RearRightTirePressureValue ##2G##IBU - TPMS11 - PRESSURE_RR";
CM_ SG_ 928 TPMS_SnsrSta "TPMS_SensorStatus ##2G##IBU - TPMS11 - STATUS_TPMS";
CM_ SG_ 928 TPMS_WrngLmpSta "TPMS_WarninglampStatus ##2G##IBU - TPMS11 - TPMS_W_LAMP";
CM_ SG_ 928 TPMS_TreadWrngLmpSta "TPMS_TreadWarningLampStatus ##2G##IBU - TPMS11 - TREAD_W_LAMP";
CM_ SG_ 928 TPMS_PrsrUnitSta "TPMS_PressureUnit ##2G##IBU - TPMS11 - UNIT";
CM_ BO_ 160 "[P] Periodic";
CM_ SG_ 160 WHL_SpdRRVal "WHL_SpeedRearRightValue ##2G##ESC - WHL_SPD11 - WHL_SPD_RR";
CM_ SG_ 160 WHL_SpdFLVal "WHL_SpeedFrontLeftValue ##2G##ESC - WHL_SPD11 - WHL_SPD_FL";
CM_ SG_ 160 WHL_SpdFRVal "WHL_SpeedFrontRightValue ##2G##ESC - WHL_SPD11 - WHL_SPD_FR";
CM_ SG_ 160 WHL_SpdRLVal "WHL_SpeedRearLeftValue ##2G##ESC - WHL_SPD11 - WHL_SPD_RL";
CM_ BO_ 1099 "[PE] Periodic and On Event";
CM_ SG_ 1099 USM_CmdWPCSta "USM_CommandWPCStatus";
CM_ SG_ 1099 WPC_PhnLftWrngSta "WPC_PhoneLeftWarningStatus";
BA_DEF_ BO_ "TpMessage" ENUM "No","Yes" ;
BA_DEF_ BO_ "UsrMsgIDSforwardDeviation" INT 0 100 ;
BA_DEF_ BO_ "UsrMsgIDSbackwardDeviation" INT 50 1000 ;
BA_DEF_ "BusType" STRING ;
BA_DEF_ "DBName" STRING ;
BA_DEF_ "Baudrate" INT 50000 1000000 ;
BA_DEF_ "BRS" INT 0 1 ;
BA_DEF_ "GenEnvVarEndingDsp" STRING ;
BA_DEF_ "GenEnvVarEndingSnd" STRING ;
BA_DEF_ "GenEnvVarPrefix" STRING ;
BA_DEF_ "GenNWMApBusSleep" STRING ;
BA_DEF_ "GenNWMApCanNormal" STRING ;
BA_DEF_ "GenNWMApCanOff" STRING ;
BA_DEF_ "GenNWMApCanOn" STRING ;
BA_DEF_ "GenNWMApCanSleep" STRING ;
BA_DEF_ "GenNWMApCanWakeUp" STRING ;
BA_DEF_ "GenNWMGotoMode_Awake" STRING ;
BA_DEF_ "GenNWMGotoMode_BusSleep" STRING ;
BA_DEF_ "GenNWMSleepTime" INT 1375 1650 ;
BA_DEF_ "GenNWMTalkNM" STRING ;
BA_DEF_ "Manufacturer" STRING ;
BA_DEF_ "NmBaseAddress" HEX 0 2047 ;
BA_DEF_ "NmMessageCount" INT 0 128 ;
BA_DEF_ "NmType" STRING ;
BA_DEF_ "SamplePointMax" INT 50 85 ;
BA_DEF_ "SamplePointMin" INT 55 85 ;
BA_DEF_ "SyncJumpWidthMax" INT 1 8 ;
BA_DEF_ "SyncJumpWidthMin" INT 1 4 ;
BA_DEF_ "VersionDay" INT 1 31 ;
BA_DEF_ "VersionMonth" INT 1 12 ;
BA_DEF_ "VersionWeek" INT 1 53 ;
BA_DEF_ "VersionYear" INT 0 9999 ;
BA_DEF_ BU_ "NmStationAddress" HEX 0 127 ;
BA_DEF_ BU_ "NmNode" ENUM "No","Yes" ;
BA_DEF_ BU_ "GenNodSleepTime" INT 1375 1650 ;
BA_DEF_ BU_ "ILUsed" ENUM "No","Yes" ;
BA_DEF_ BU_ "NmCAN" INT 1 2 ;
BA_DEF_ BU_ "NodeLayerModules" STRING ;
BA_DEF_ BU_ "NWM_Knoten" ENUM "No","Yes" ;
BA_DEF_ BO_ "GenMsgCycleTime" INT 0 2000 ;
BA_DEF_ BO_ "GenMsgStartDelayTime" INT 0 2000 ;
BA_DEF_ BO_ "GenMsgSendType" ENUM "Cyclic","NoMsgSendType" ;
BA_DEF_ BO_ "GenMsgCycleTimeFast" INT 0 500 ;
BA_DEF_ BO_ "GenMsgDelayTime" INT 0 20 ;
BA_DEF_ BO_ "GenMsgILSupport" ENUM "No","Yes" ;
BA_DEF_ BO_ "GenMsgNrOfRepetition" INT 0 3 ;
BA_DEF_ BO_ "VFrameFormat" ENUM "StandardCAN","ExtendedCAN","reserved","reserved","reserved","reserved","reserved","reserved","reserved","reserved","reserved","reserved","reserved","reserved","StandardCAN_FD","ExtendedCAN_FD" ;
BA_DEF_ SG_ "UserSigValidity" ENUM "B+","ACC","IG","IG1","IG2","IG3","IG1 or IG2","IG1 or IG3","Undef" ;
BA_DEF_ SG_ "GenSigTimeoutTime" INT 0 7000 ;
BA_DEF_ SG_ "UsrSigTimeoutValue" STRING ;
BA_DEF_ SG_ "UsrSigPurpose" ENUM "Undef","FN","DIAG","DEV","NM" ;
BA_DEF_ SG_ "GenSigStartValue" INT 0 0 ;
BA_DEF_ SG_ "NetworkRequest" ENUM "Yes","No" ;
BA_DEF_ SG_ "NetworkRequestHoldingTime" INT 0 65535 ;
BA_DEF_ SG_ "Description" STRING ;
BA_DEF_ SG_ "Version" STRING ;
BA_DEF_ SG_ "GenSigEnvVarType" ENUM "Int","Float","Undef" ;
BA_DEF_ SG_ "GenSigSendType" ENUM "Cyclic","OnWrite","OnWriteWithRepetition","OnChange","OnChangeWithRepetition","IfActive","IfActiveWithRepetition","NoSigSendType","OnChangeAndIfActive","OnChangeAndIfActiveWithRepetition" ;
BA_DEF_ SG_ "GwSigLatencyTime" INT 0 65536 ;
BA_DEF_ SG_ "GwSigMissingSourceType" ENUM "Undef","OldValue","DefaultValue","InitialValue" ;
BA_DEF_ SG_ "NWM-WakeupAllowed" ENUM "<n.a.>" ;
BA_DEF_ SG_ "RoutingFactor" INT 1 1215752192 ;
BA_DEF_ "Datarate" INT 2000000 8000000 ;
BA_DEF_DEF_ "TpMessage" "No" ;
BA_DEF_DEF_ "UsrMsgIDSforwardDeviation" 10 ;
BA_DEF_DEF_ "UsrMsgIDSbackwardDeviation" 100 ;
BA_DEF_DEF_ "BusType" "CAN FD" ;
BA_DEF_DEF_ "DBName" "" ;
BA_DEF_DEF_ "Baudrate" 500000 ;
BA_DEF_DEF_ "BRS" 1 ;
BA_DEF_DEF_ "GenEnvVarEndingDsp" "Dsp_" ;
BA_DEF_DEF_ "GenEnvVarEndingSnd" "_" ;
BA_DEF_DEF_ "GenEnvVarPrefix" "Env" ;
BA_DEF_DEF_ "GenNWMApBusSleep" "AppNmCanBusSleep()" ;
BA_DEF_DEF_ "GenNWMApCanNormal" "AppNmCanNormal()" ;
BA_DEF_DEF_ "GenNWMApCanOff" "ApplCanOffline()" ;
BA_DEF_DEF_ "GenNWMApCanOn" "ApplCanOnline()" ;
BA_DEF_DEF_ "GenNWMApCanSleep" "ApplNmCanSleep()" ;
BA_DEF_DEF_ "GenNWMApCanWakeUp" "ApplCanWakeUp()" ;
BA_DEF_DEF_ "GenNWMGotoMode_Awake" "GotoMode_Awake()" ;
BA_DEF_DEF_ "GenNWMGotoMode_BusSleep" "GotoMode_BusSleep()" ;
BA_DEF_DEF_ "GenNWMSleepTime" 1500 ;
BA_DEF_DEF_ "GenNWMTalkNM" "TalkNM()" ;
BA_DEF_DEF_ "Manufacturer" "HMC" ;
BA_DEF_DEF_ "NmBaseAddress" 1280 ;
BA_DEF_DEF_ "NmMessageCount" 128 ;
BA_DEF_DEF_ "NmType" "Vector" ;
BA_DEF_DEF_ "SamplePointMax" 80 ;
BA_DEF_DEF_ "SamplePointMin" 80 ;
BA_DEF_DEF_ "SyncJumpWidthMax" 3 ;
BA_DEF_DEF_ "SyncJumpWidthMin" 2 ;
BA_DEF_DEF_ "VersionDay" 1 ;
BA_DEF_DEF_ "VersionMonth" 1 ;
BA_DEF_DEF_ "VersionWeek" 1 ;
BA_DEF_DEF_ "VersionYear" 0 ;
BA_DEF_DEF_ "NmStationAddress" 0 ;
BA_DEF_DEF_ "NmNode" "Yes" ;
BA_DEF_DEF_ "GenNodSleepTime" 1500 ;
BA_DEF_DEF_ "ILUsed" "Yes" ;
BA_DEF_DEF_ "NmCAN" 1 ;
BA_DEF_DEF_ "NodeLayerModules" "oseknm01.dll,CANoeILNLVector.dll" ;
BA_DEF_DEF_ "NWM_Knoten" "Yes" ;
BA_DEF_DEF_ "GenMsgCycleTime" 200 ;
BA_DEF_DEF_ "GenMsgStartDelayTime" 0 ;
BA_DEF_DEF_ "GenMsgSendType" "NoMsgSendType" ;
BA_DEF_DEF_ "GenMsgCycleTimeFast" 40 ;
BA_DEF_DEF_ "GenMsgDelayTime" 20 ;
BA_DEF_DEF_ "GenMsgILSupport" "Yes" ;
BA_DEF_DEF_ "GenMsgNrOfRepetition" 3 ;
BA_DEF_DEF_ "VFrameFormat" "StandardCAN" ;
BA_DEF_DEF_ "UserSigValidity" "IG" ;
BA_DEF_DEF_ "GenSigTimeoutTime" 500 ;
BA_DEF_DEF_ "UsrSigTimeoutValue" "Undef" ;
BA_DEF_DEF_ "UsrSigPurpose" "FN" ;
BA_DEF_DEF_ "GenSigStartValue" 0 ;
BA_DEF_DEF_ "NetworkRequest" "No" ;
BA_DEF_DEF_ "NetworkRequestHoldingTime" 0 ;
BA_DEF_DEF_ "Description" "" ;
BA_DEF_DEF_ "Version" "" ;
BA_DEF_DEF_ "GenSigEnvVarType" "Undef" ;
BA_DEF_DEF_ "GenSigSendType" "NoSigSendType" ;
BA_DEF_DEF_ "GwSigLatencyTime" 40 ;
BA_DEF_DEF_ "GwSigMissingSourceType" "Undef" ;
BA_DEF_DEF_ "NWM-WakeupAllowed" "<n.a.>" ;
BA_DEF_DEF_ "RoutingFactor" 1 ;
BA_DEF_DEF_ "Datarate" 2000000 ;
BA_ "DBName" "CANFD";
BA_ "VersionDay" 17;
BA_ "VersionMonth" 6;
BA_ "VersionYear" 2019;
BA_ "VersionWeek" 24;
BA_ "NmStationAddress" BU_ CGW 22;
BA_ "NmNode" BU_ CLU 0;
BA_ "GenMsgSendType" BO_ 522 0;
BA_ "GenMsgCycleTime" BO_ 522 100;
BA_ "GenMsgCycleTimeFast" BO_ 522 0;
BA_ "GenMsgNrOfRepetition" BO_ 522 0;
BA_ "VFrameFormat" BO_ 522 14;
BA_ "Description" SG_ 522 ACU_SysWrngLmpDis "This signal means information regarding ACU diagnostic information result & discrimination.

1) Default value : 0x1
2) Default value Transmit condition
    - When the input condition is not determined.
    - When the input condition is not supported.";
BA_ "GenSigStartValue" SG_ 522 ACU_SysWrngLmpDis 1;
BA_ "UserSigValidity" SG_ 522 ACU_SysWrngLmpDis 3;
BA_ "GenSigTimeoutTime" SG_ 522 ACU_SysWrngLmpDis 1500;
BA_ "RoutingFactor" SG_ 522 ACU_SysWrngLmpDis 2;
BA_ "Version" SG_ 522 ACU_SysWrngLmpDis "18.11.05";
BA_ "NmNode" BU_ FR_CMR 0;
BA_ "GenMsgSendType" BO_ 416 0;
BA_ "GenMsgCycleTime" BO_ 416 20;
BA_ "GenMsgCycleTimeFast" BO_ 416 0;
BA_ "GenMsgNrOfRepetition" BO_ 416 0;
BA_ "GenMsgDelayTime" BO_ 416 0;
BA_ "VFrameFormat" BO_ 416 14;
BA_ "Description" SG_ 416 SCC_NSCCOpSta "This signal describes the operational status of NSCC-Z/C/R function. 

NSCC-Z/C/R  작동 상태 정보(off/ready/active)";
BA_ "UserSigValidity" SG_ 416 SCC_NSCCOpSta 3;
BA_ "RoutingFactor" SG_ 416 SCC_NSCCOpSta 5;
BA_ "Version" SG_ 416 SCC_NSCCOpSta "17.12.00";
BA_ "Description" SG_ 416 SCC_NSCCOnOffSta "This signal describes the on/off status of NSCC-Z/C/R and HDA Auto-set function. 

NSCC-Z/C/R  and HDA auto-set on/off 상태 정보";
BA_ "UserSigValidity" SG_ 416 SCC_NSCCOnOffSta 3;
BA_ "RoutingFactor" SG_ 416 SCC_NSCCOnOffSta 5;
BA_ "Version" SG_ 416 SCC_NSCCOnOffSta "17.12.00";
BA_ "Description" SG_ 416 SCC_ObjSta "This signal represents the state of in-path object and information of controllable state.
- 자차선상의 전방 차량 인식 여부 및 제어 가능 상태 정보";
BA_ "UserSigValidity" SG_ 416 SCC_ObjSta 3;
BA_ "RoutingFactor" SG_ 416 SCC_ObjSta 5;
BA_ "Version" SG_ 416 SCC_ObjSta "18.10.09";
BA_ "Description" SG_ 416 SCC_SnstvtyModRetVal "This signal is SCC sensitive set mode switch info return value to cluster
- SCC 민감도 설정 관련 USM 설정 스위치 정보의 리턴 값";
BA_ "GenSigStartValue" SG_ 416 SCC_SnstvtyModRetVal 2;
BA_ "UserSigValidity" SG_ 416 SCC_SnstvtyModRetVal 3;
BA_ "RoutingFactor" SG_ 416 SCC_SnstvtyModRetVal 5;
BA_ "Version" SG_ 416 SCC_SnstvtyModRetVal "17.12.00";
BA_ "Description" SG_ 416 SCC_NSCCAutoSetSpdUpdtSta "This is information if Auto Set Speed Control is updated or not.";
BA_ "UserSigValidity" SG_ 416 SCC_NSCCAutoSetSpdUpdtSta 3;
BA_ "RoutingFactor" SG_ 416 SCC_NSCCAutoSetSpdUpdtSta 5;
BA_ "Version" SG_ 416 SCC_NSCCAutoSetSpdUpdtSta "18.10.02";
BA_ "Description" SG_ 416 SCC_NSCCInfoPUDis "This signal shows the cluster pop-up for NSCC Information.";
BA_ "UserSigValidity" SG_ 416 SCC_NSCCInfoPUDis 3;
BA_ "RoutingFactor" SG_ 416 SCC_NSCCInfoPUDis 5;
BA_ "Version" SG_ 416 SCC_NSCCInfoPUDis "18.10.02";
BA_ "Description" SG_ 416 SCC_TrgtDstVal "This signal provides the target distance for SCC fallowing control.
- SCC 거리 제어를 위한 목표 차간 거리 정보";
BA_ "GenSigStartValue" SG_ 416 SCC_TrgtDstVal 2046;
BA_ "UserSigValidity" SG_ 416 SCC_TrgtDstVal 3;
BA_ "RoutingFactor" SG_ 416 SCC_TrgtDstVal 5;
BA_ "Version" SG_ 416 SCC_TrgtDstVal "18.10.09";
BA_ "Description" SG_ 416 SCC_ObjDstVal "This signal provides the distance to the in lane detected SCC object regarding to the own vehicle.
- 자차선상의 전방 인식된 물체와의 거리";
BA_ "GenSigStartValue" SG_ 416 SCC_ObjDstVal 2046;
BA_ "UserSigValidity" SG_ 416 SCC_ObjDstVal 3;
BA_ "RoutingFactor" SG_ 416 SCC_ObjDstVal 5;
BA_ "Version" SG_ 416 SCC_ObjDstVal "18.10.09";
BA_ "Description" SG_ 416 SCC_ObjLatPosVal "This signal provides the lateral position of the detected SCC object regarding to the own vehicle. 
The position of the SCC object on the left side in driving direction of the vehicle longitudinal axis correlates with a negative signal value. 
Thus an SCC object on the right side in driving direction of the vehicle longitudinal axis correlates with a positive signal value.
- 자차선상의 전방 인식된 ?레의 횡방향 위치 값
- 자차기준 왼편 물체는 '-' 값, 오른편 물체는 '+' 값";
BA_ "GenSigStartValue" SG_ 416 SCC_ObjLatPosVal 510;
BA_ "UserSigValidity" SG_ 416 SCC_ObjLatPosVal 3;
BA_ "RoutingFactor" SG_ 416 SCC_ObjLatPosVal 5;
BA_ "Version" SG_ 416 SCC_ObjLatPosVal "18.10.09";
BA_ "Description" SG_ 416 SCC_SysFlrSta "This signal is evaluated by the driver information device to release the failure information to the driver.
If this signal is set to anything other than 0, the TCS/ESC shall ignore any requests from SCC
- 시스템 고장 발생 정보용
- 해당 값이 0 이외의 모든 값 송출시 TCS/ESC 는 SCC 신호를 무시 할것.";
BA_ "UserSigValidity" SG_ 416 SCC_SysFlrSta 3;
BA_ "RoutingFactor" SG_ 416 SCC_SysFlrSta 5;
BA_ "Version" SG_ 416 SCC_SysFlrSta "17.12.00";
BA_ "Description" SG_ 416 SCC_MainOnOffSta "This signal specifies the status of a Main switch of SCC system
- Main swith 에 의한 SCC ON/OFF 상태 정보";
BA_ "UserSigValidity" SG_ 416 SCC_MainOnOffSta 3;
BA_ "RoutingFactor" SG_ 416 SCC_MainOnOffSta 5;
BA_ "Version" SG_ 416 SCC_MainOnOffSta "17.12.00";
BA_ "Description" SG_ 416 SCC_OpSta "The signal ACCmode specifies the operational mode of SCC
- ACC 작동 상태 정보(off&ready / active / override / shut off)";
BA_ "UserSigValidity" SG_ 416 SCC_OpSta 3;
BA_ "RoutingFactor" SG_ 416 SCC_OpSta 5;
BA_ "Version" SG_ 416 SCC_OpSta "18.10.09";
BA_ "Description" SG_ 416 SCC_TakeoverReq "The Take-over Request supports the driver to identify the limits of the SCC control. Reasons for such a request may be:
- Deceleration capability insufficient for the current situation.
Clutch actuation by the driver is necessary to avoid stopping of the engine. This signal shall activate an audible and visual alert
- 감속상황에서 SCC 시스템만으로 감속이 어려운 한계상황 발생시 운전자에게 개입(제동)을 요청하는 경고 신호
- 청각 / 시각적으로 경고 필요";
BA_ "UserSigValidity" SG_ 416 SCC_TakeoverReq 3;
BA_ "RoutingFactor" SG_ 416 SCC_TakeoverReq 5;
BA_ "Version" SG_ 416 SCC_TakeoverReq "17.12.00";
BA_ "Description" SG_ 416 SCC_InfoDis "This signal carries information that indicates below 4 signals.
(1) SCC Mode display
(2) CC Mode display
(3) Object disapearing display
(4) Go notifying display
- SCC 제어 상세 상태를 보여주는 정보 신호
(SCC 모드 / CC 모드 / 전방차량 주의 / 정차 출발 주의)";
BA_ "UserSigValidity" SG_ 416 SCC_InfoDis 3;
BA_ "RoutingFactor" SG_ 416 SCC_InfoDis 5;
BA_ "Version" SG_ 416 SCC_InfoDis "18.10.09";
BA_ "Description" SG_ 416 SCC_DrvAlrtDis "This signal carries the information which message shall be displayed to the driver 
when the SCC must be disengaged by the system or cann’t be engaged.
A signal value unequal 00H is repeated for 5 messages cycles in order to ensure it appears for at least 100ms on the bus 
(Output period of SCC1 is 20ms).
- SCC 제어 진입이 어려운 상황 또는 차량 정차 상태등 운전자 경보 필요시 송출 하는 신호";
BA_ "UserSigValidity" SG_ 416 SCC_DrvAlrtDis 3;
BA_ "RoutingFactor" SG_ 416 SCC_DrvAlrtDis 5;
BA_ "Version" SG_ 416 SCC_DrvAlrtDis "17.12.00";
BA_ "Description" SG_ 416 SCC_ObjDstLvlVal "If a in-path object is recognized by SCC, the driver should be informed.
- 자차선상의 전방 물체 인식 여부 정보";
BA_ "UserSigValidity" SG_ 416 SCC_ObjDstLvlVal 3;
BA_ "RoutingFactor" SG_ 416 SCC_ObjDstLvlVal 5;
BA_ "Version" SG_ 416 SCC_ObjDstLvlVal "18.11.02";
BA_ "Description" SG_ 416 SCC_HeadwayDstSetVal "The desired time gap from which a following distance is extracted has to be presented to the driver at least if the value changes. 
The representation of the information depends on the display concept.
- 전방 차량과의 거리 setting 정보
※ SCC-ML: SCC Machine Learning";
BA_ "UserSigValidity" SG_ 416 SCC_HeadwayDstSetVal 3;
BA_ "RoutingFactor" SG_ 416 SCC_HeadwayDstSetVal 5;
BA_ "Version" SG_ 416 SCC_HeadwayDstSetVal "17.12.00";
BA_ "Description" SG_ 416 SCC_NSCCAutoSetSpdSta "This is information if Auto Set Speed Control is enabled or not.";
BA_ "UserSigValidity" SG_ 416 SCC_NSCCAutoSetSpdSta 3;
BA_ "RoutingFactor" SG_ 416 SCC_NSCCAutoSetSpdSta 5;
BA_ "Version" SG_ 416 SCC_NSCCAutoSetSpdSta "18.10.02";
BA_ "Description" SG_ 416 SCC_TrgtSpdSetVal "The desired vehicle speed for free cruising has to be displayed all the time SCC is under active control.
※This signal can be sent in km/h or MPH according to the “SPEED_UNIT” signal (See CLU1 message).
SPEED_UNIT = 0 : [km/h], SPEED_UNIT = 1 : [MPH]
- 운전자가 설정한 차속 정보";
BA_ "UserSigValidity" SG_ 416 SCC_TrgtSpdSetVal 3;
BA_ "RoutingFactor" SG_ 416 SCC_TrgtSpdSetVal 5;
BA_ "Version" SG_ 416 SCC_TrgtSpdSetVal "17.12.00";
BA_ "NmNode" BU_ RR_C_RDR 0;
BA_ "NmNode" BU_ DATC 0;
BA_ "GenMsgSendType" BO_ 1090 0;
BA_ "VFrameFormat" BO_ 1090 14;
BA_ "Description" SG_ 1090 BCM_SmkOptTyp "-(Old)C_PICOption";
BA_ "GenSigSendType" SG_ 1090 BCM_SmkOptTyp 4;
BA_ "UserSigValidity" SG_ 1090 BCM_SmkOptTyp 0;
BA_ "GenSigTimeoutTime" SG_ 1090 BCM_SmkOptTyp 1500;
BA_ "NetworkRequest" SG_ 1090 BCM_SmkOptTyp 0;
BA_ "NetworkRequestHoldingTime" SG_ 1090 BCM_SmkOptTyp 5000;
BA_ "Version" SG_ 1090 BCM_SmkOptTyp "17.12.00";
BA_ "GenSigSendType" SG_ 1090 Window_DrvrSdWdwSta_BCM 4;
BA_ "UserSigValidity" SG_ 1090 Window_DrvrSdWdwSta_BCM 0;
BA_ "GenSigTimeoutTime" SG_ 1090 Window_DrvrSdWdwSta_BCM 1500;
BA_ "NetworkRequest" SG_ 1090 Window_DrvrSdWdwSta_BCM 0;
BA_ "NetworkRequestHoldingTime" SG_ 1090 Window_DrvrSdWdwSta_BCM 5000;
BA_ "Version" SG_ 1090 Window_DrvrSdWdwSta_BCM "17.12.00";
BA_ "Description" SG_ 1090 Window_AsstSdWdwSta_BCM "-(Old)C_AstWdwStat";
BA_ "GenSigSendType" SG_ 1090 Window_AsstSdWdwSta_BCM 4;
BA_ "UserSigValidity" SG_ 1090 Window_AsstSdWdwSta_BCM 0;
BA_ "GenSigTimeoutTime" SG_ 1090 Window_AsstSdWdwSta_BCM 1500;
BA_ "NetworkRequest" SG_ 1090 Window_AsstSdWdwSta_BCM 0;
BA_ "NetworkRequestHoldingTime" SG_ 1090 Window_AsstSdWdwSta_BCM 5000;
BA_ "Version" SG_ 1090 Window_AsstSdWdwSta_BCM "17.12.00";
BA_ "Description" SG_ 1090 Window_RrLftWdwSta_BCM "-(Old)C_RLWdwSta";
BA_ "GenSigSendType" SG_ 1090 Window_RrLftWdwSta_BCM 4;
BA_ "UserSigValidity" SG_ 1090 Window_RrLftWdwSta_BCM 0;
BA_ "GenSigTimeoutTime" SG_ 1090 Window_RrLftWdwSta_BCM 1500;
BA_ "NetworkRequest" SG_ 1090 Window_RrLftWdwSta_BCM 0;
BA_ "NetworkRequestHoldingTime" SG_ 1090 Window_RrLftWdwSta_BCM 5000;
BA_ "Version" SG_ 1090 Window_RrLftWdwSta_BCM "17.12.00";
BA_ "Description" SG_ 1090 Window_RrRtWdwSta_BCM "-(Old)C_RRWdwStat";
BA_ "GenSigSendType" SG_ 1090 Window_RrRtWdwSta_BCM 4;
BA_ "UserSigValidity" SG_ 1090 Window_RrRtWdwSta_BCM 0;
BA_ "GenSigTimeoutTime" SG_ 1090 Window_RrRtWdwSta_BCM 1500;
BA_ "NetworkRequest" SG_ 1090 Window_RrRtWdwSta_BCM 0;
BA_ "NetworkRequestHoldingTime" SG_ 1090 Window_RrRtWdwSta_BCM 5000;
BA_ "Version" SG_ 1090 Window_RrRtWdwSta_BCM "17.12.00";
BA_ "Description" SG_ 1090 Mirror_OSMirFldDis_BCM "- AVM Warning Indicator signal";
BA_ "GenSigSendType" SG_ 1090 Mirror_OSMirFldDis_BCM 4;
BA_ "UserSigValidity" SG_ 1090 Mirror_OSMirFldDis_BCM 0;
BA_ "GenSigTimeoutTime" SG_ 1090 Mirror_OSMirFldDis_BCM 1500;
BA_ "NetworkRequest" SG_ 1090 Mirror_OSMirFldDis_BCM 0;
BA_ "NetworkRequestHoldingTime" SG_ 1090 Mirror_OSMirFldDis_BCM 5000;
BA_ "Version" SG_ 1090 Mirror_OSMirFldDis_BCM "17.12.00";
BA_ "GenMsgSendType" BO_ 426 0;
BA_ "GenMsgCycleTime" BO_ 426 20;
BA_ "GenMsgCycleTimeFast" BO_ 426 0;
BA_ "GenMsgNrOfRepetition" BO_ 426 0;
BA_ "GenMsgDelayTime" BO_ 426 0;
BA_ "VFrameFormat" BO_ 426 14;
BA_ "Description" SG_ 426 CLU_Crc1Val "The data area for CRC calculation is based on the data length (DLC) of the message DB.
The CRC shall be calculated over the entire data block (excluding the CRC bytes) including the user data, alive counter and Data ID
 
- CRC Polynomial (0x1021) , Initial Value : 0xFFFF, XOR value : 0x0000, Data ID : Message ID + 0xF800 
- The initial value is for CRC calculation and the message should be sent with the calculated result value. 
- The mathematical expression to 16 bit CRC polynomial is given here. G(x) = x16 + x12 + x5 + 1";
BA_ "GenSigStartValue" SG_ 426 CLU_Crc1Val 65535;
BA_ "UserSigValidity" SG_ 426 CLU_Crc1Val 3;
BA_ "RoutingFactor" SG_ 426 CLU_Crc1Val 5;
BA_ "Version" SG_ 426 CLU_Crc1Val "18.11.08";
BA_ "Description" SG_ 426 CLU_AlvCnt1Val "For the first transmission request for a data element the counter shall be initialized with 0 and shall be incremented by 1 for every subsequent send request. 
When the counter reaches the maximum value(0xFF), then it shall restart with 0 for the next send request";
BA_ "UserSigValidity" SG_ 426 CLU_AlvCnt1Val 3;
BA_ "RoutingFactor" SG_ 426 CLU_AlvCnt1Val 5;
BA_ "Version" SG_ 426 CLU_AlvCnt1Val "18.11.08";
BA_ "Description" SG_ 426 CLU_PrtyBitSta "Conversion: 
(PH) = 1 if (BIT16 + BIT17 + BIT18 + BIT19 + BIT20 + BIT21 + BIT22 + BIT23 + BIT34 + BIT35 + BIT36 + BIT37 + BIT38 + BIT41 + BIT42) is odd (least significant bit is set)
(PH) = 0 if (BIT16 + BIT17 + BIT18 + BIT19 + BIT20 + BIT21 + BIT22 + BIT23 + BIT34 + BIT35 + BIT36 + BIT37 + BIT38 + BIT41 + BIT42) is even (least significant bit is not set)";
BA_ "UserSigValidity" SG_ 426 CLU_PrtyBitSta 3;
BA_ "RoutingFactor" SG_ 426 CLU_PrtyBitSta 5;
BA_ "Version" SG_ 426 CLU_PrtyBitSta "18.08.11";
BA_ "Description" SG_ 426 CLU_SpdUnitTyp "This signal indicates the unit of the speed displayed in the speedometer.";
BA_ "UserSigValidity" SG_ 426 CLU_SpdUnitTyp 3;
BA_ "RoutingFactor" SG_ 426 CLU_SpdUnitTyp 5;
BA_ "Version" SG_ 426 CLU_SpdUnitTyp "17.11.00";
BA_ "Description" SG_ 426 CLU_DisSpdDcmlVal "The signal 'CF_Clu_VanzDecimal' means the extra value of the signal 'CF_Clu_Vanz' (vehicle speed which is indicated in the speedometer)
Also, This signal should be sent in km/h or MPH according to the 'CF_Clu_SPEED_UNIT' signal.
CF_Clu_SPEED_UNIT = 0 : [km/h]
CF_Clu_SPEED_UNIT = 1 : [MPH]

Example)   CF_Clu_Vanz = 13,  CF_Clu_VanzDecimal  = 3
Displayed vehicle speed  = (CF_Clu_Vanz / 2) + (CF_Clu_VanzDecimal / 8)
= ( 13 / 2 ) + ( 3 / 8 ) = 6.875 [Km/h or MPH]";
BA_ "UserSigValidity" SG_ 426 CLU_DisSpdDcmlVal 3;
BA_ "RoutingFactor" SG_ 426 CLU_DisSpdDcmlVal 5;
BA_ "Version" SG_ 426 CLU_DisSpdDcmlVal "17.11.00";
BA_ "Description" SG_ 426 CLU_SWRCCrsMainSwSta "Cruise on/off switch";
BA_ "UserSigValidity" SG_ 426 CLU_SWRCCrsMainSwSta 3;
BA_ "RoutingFactor" SG_ 426 CLU_SWRCCrsMainSwSta 5;
BA_ "Version" SG_ 426 CLU_SWRCCrsMainSwSta "18.04.00";
BA_ "Description" SG_ 426 CLU_SWRCCrsSwSta "Depending on whether One-touch logic is applied, the meaning of each signal value is divided into two cases as shown below

Case1) Not applied
0x0:Idle Position
0x1:Resume/Plus
0x2:Set/Minus
0x3:Time gap (Distance, SCC only)
0x4:ACC/SCC cancel

Case2) Applied
0x0: Idle Position
0x1: Plus/Set
0x2: Minus/Set
0x3: Time gap (Distance, SCC only)
0x4: Pause/Resume";
BA_ "UserSigValidity" SG_ 426 CLU_SWRCCrsSwSta 3;
BA_ "RoutingFactor" SG_ 426 CLU_SWRCCrsSwSta 5;
BA_ "Version" SG_ 426 CLU_SWRCCrsSwSta "18.07.01";
BA_ "Description" SG_ 426 CLU_SWRCLFASwSta "LFA/HDA on/off switch";
BA_ "UserSigValidity" SG_ 426 CLU_SWRCLFASwSta 3;
BA_ "RoutingFactor" SG_ 426 CLU_SWRCLFASwSta 5;
BA_ "Version" SG_ 426 CLU_SWRCLFASwSta "18.04.00";
BA_ "Description" SG_ 426 CLU_SWRCSldMainSwSta "Speedlimiter on/off switch";
BA_ "UserSigValidity" SG_ 426 CLU_SWRCSldMainSwSta 3;
BA_ "RoutingFactor" SG_ 426 CLU_SWRCSldMainSwSta 5;
BA_ "Version" SG_ 426 CLU_SWRCSldMainSwSta "18.04.00";
BA_ "Description" SG_ 426 CLU_RhstaLvlSta "This signal is used for a rheostat level of CLUSTER from 1 to 21 level (21 level : Detent) for a Unified Illumination system.

※ Start Value : Current value";
BA_ "UserSigValidity" SG_ 426 CLU_RhstaLvlSta 0;
BA_ "RoutingFactor" SG_ 426 CLU_RhstaLvlSta 5;
BA_ "Version" SG_ 426 CLU_RhstaLvlSta "17.11.00";
BA_ "Description" SG_ 426 CLU_DisSpdVal "The vehicle speed which is indicated in the speedmeter has to be sent to SCC. This value is used for evalution of SCC command values instead of the vehicle velocity in order to avoid significant difference between the speedmeter indicator and the set speed indicator(especially in the case of free cruising with the set speed). In terms of debouning and presnce on CAN, the same time scales have to be used and described for time gap setting.
This signal should be sent in km/h or MPH according to the “SPEED_UNIT” signal.
SPEED_UNIT = 0 : [km/h]
SPEED_UNIT = 1 : [MPH]";
BA_ "UserSigValidity" SG_ 426 CLU_DisSpdVal 3;
BA_ "RoutingFactor" SG_ 426 CLU_DisSpdVal 5;
BA_ "Version" SG_ 426 CLU_DisSpdVal "17.12.03";
BA_ "Description" SG_ 426 CLU_OKSwSta "This signal represents operating status of Ok Switch in Steering Wheel. Default value of this signal is 0 and the value is set to 1 only while a driver is pressing the OK Switch.";
BA_ "UserSigValidity" SG_ 426 CLU_OKSwSta 3;
BA_ "RoutingFactor" SG_ 426 CLU_OKSwSta 5;
BA_ "Version" SG_ 426 CLU_OKSwSta "19.03.06";
BA_ "Description" SG_ 426 CLU_DisSpdVal_KPH "The vehicle speed which is indicated in the speedmeter.
This signal should be sent in km/h only.";
BA_ "UserSigValidity" SG_ 426 CLU_DisSpdVal_KPH 3;
BA_ "RoutingFactor" SG_ 426 CLU_DisSpdVal_KPH 5;
BA_ "Version" SG_ 426 CLU_DisSpdVal_KPH "17.12.09";
BA_ "GenMsgSendType" BO_ 549 0;
BA_ "GenMsgCycleTime" BO_ 549 100;
BA_ "GenMsgCycleTimeFast" BO_ 549 0;
BA_ "GenMsgNrOfRepetition" BO_ 549 0;
BA_ "VFrameFormat" BO_ 549 14;
BA_ "Description" SG_ 549 CLU_Crc2Val "The data area for CRC calculation is based on the data length (DLC) of the message DB.
The CRC shall be calculated over the entire data block (excluding the CRC bytes) including the user data, alive counter and Data ID
 
- CRC Polynomial (0x1021) , Initial Value : 0xFFFF, XOR value : 0x0000, Data ID : Message ID + 0xF800 
- The initial value is for CRC calculation and the message should be sent with the calculated result value. 
- The mathematical expression to 16 bit CRC polynomial is given here. G(x) = x16 + x12 + x5 + 1";
BA_ "GenSigStartValue" SG_ 549 CLU_Crc2Val 65535;
BA_ "UserSigValidity" SG_ 549 CLU_Crc2Val 3;
BA_ "GenSigTimeoutTime" SG_ 549 CLU_Crc2Val 1500;
BA_ "RoutingFactor" SG_ 549 CLU_Crc2Val 2;
BA_ "Version" SG_ 549 CLU_Crc2Val "18.11.08";
BA_ "Description" SG_ 549 CLU_RefuelWrnSta "This signal indicates that the Refuel popup is the cluster is On or Off.
When Refuel popup is on, its value is 0x1 otherwise its value is 0x0.";
BA_ "UserSigValidity" SG_ 549 CLU_RefuelWrnSta 3;
BA_ "GenSigTimeoutTime" SG_ 549 CLU_RefuelWrnSta 1500;
BA_ "RoutingFactor" SG_ 549 CLU_RefuelWrnSta 2;
BA_ "Version" SG_ 549 CLU_RefuelWrnSta "17.11.00";
BA_ "Description" SG_ 549 CLU_DrvngModSwSta "This signal occurs when drive mode switch is selected either 'Normal' or 'Eco' or 'Sport' or 'Sport+' or 'Smart' or 'Custom' or 'N-mode'.";
BA_ "UserSigValidity" SG_ 549 CLU_DrvngModSwSta 3;
BA_ "GenSigTimeoutTime" SG_ 549 CLU_DrvngModSwSta 1500;
BA_ "RoutingFactor" SG_ 549 CLU_DrvngModSwSta 2;
BA_ "Version" SG_ 549 CLU_DrvngModSwSta "18.02.03";
BA_ "Description" SG_ 549 CLU_FuelLvlSta "The signal is fuel level of the cluster that fuel gauge indicate (Unit: %)";
BA_ "UserSigValidity" SG_ 549 CLU_FuelLvlSta 3;
BA_ "GenSigTimeoutTime" SG_ 549 CLU_FuelLvlSta 1500;
BA_ "RoutingFactor" SG_ 549 CLU_FuelLvlSta 2;
BA_ "Version" SG_ 549 CLU_FuelLvlSta "17.12.03";
BA_ "Description" SG_ 549 CLU_OutTempFSta "The signal is outside temerature of the cluster (Unit: ℉)";
BA_ "UserSigValidity" SG_ 549 CLU_OutTempFSta 3;
BA_ "GenSigTimeoutTime" SG_ 549 CLU_OutTempFSta 1500;
BA_ "RoutingFactor" SG_ 549 CLU_OutTempFSta 2;
BA_ "Version" SG_ 549 CLU_OutTempFSta "17.12.03";
BA_ "Description" SG_ 549 CLU_TerrainModSwSta "This signal occurs when terrain mode switch is selected either 'Snow' or 'Sand' or 'Mud'.";
BA_ "UserSigValidity" SG_ 549 CLU_TerrainModSwSta 3;
BA_ "GenSigTimeoutTime" SG_ 549 CLU_TerrainModSwSta 1500;
BA_ "RoutingFactor" SG_ 549 CLU_TerrainModSwSta 2;
BA_ "Version" SG_ 549 CLU_TerrainModSwSta "18.02.03";
BA_ "Description" SG_ 549 CLU_AlvCnt2Val "For the first transmission request for a data element the counter shall be initialized with 0 and shall be incremented by 1 for every subsequent send request. 
When the counter reaches the maximum value(0xFF), then it shall restart with 0 for the next send request";
BA_ "UserSigValidity" SG_ 549 CLU_AlvCnt2Val 3;
BA_ "GenSigTimeoutTime" SG_ 549 CLU_AlvCnt2Val 1500;
BA_ "RoutingFactor" SG_ 549 CLU_AlvCnt2Val 2;
BA_ "Version" SG_ 549 CLU_AlvCnt2Val "18.11.08";
BA_ "Description" SG_ 549 CLU_OutTempCSta "The signal is outside temerature of the cluster (Unit: ℃)";
BA_ "UserSigValidity" SG_ 549 CLU_OutTempCSta 3;
BA_ "GenSigTimeoutTime" SG_ 549 CLU_OutTempCSta 1500;
BA_ "RoutingFactor" SG_ 549 CLU_OutTempCSta 2;
BA_ "Version" SG_ 549 CLU_OutTempCSta "17.12.03";
BA_ "Description" SG_ 549 CLU_DTEVal "This signal indicates DTE.
0x0: Invalid
0x1: Not account (DTE display not in available : less than 50km)
0x2~0x3FF : Valid DTE (50~1023km)";
BA_ "UserSigValidity" SG_ 549 CLU_DTEVal 3;
BA_ "GenSigTimeoutTime" SG_ 549 CLU_DTEVal 1500;
BA_ "RoutingFactor" SG_ 549 CLU_DTEVal 2;
BA_ "Version" SG_ 549 CLU_DTEVal "17.11.00";
BA_ "Description" SG_ 549 CLU_TripUnitSta "This signal indicates Distance to Empty UNIT";
BA_ "UserSigValidity" SG_ 549 CLU_TripUnitSta 3;
BA_ "GenSigTimeoutTime" SG_ 549 CLU_TripUnitSta 1500;
BA_ "RoutingFactor" SG_ 549 CLU_TripUnitSta 2;
BA_ "Version" SG_ 549 CLU_TripUnitSta "17.11.00";
BA_ "Description" SG_ 549 CLU_AvgFuelCnsmptnVal "This average fuel consumption which is displayed in the trip-computer has to be sent to Tele-matics control unit. 
This signal is applied to the case cluster displays in the trip-computer.";
BA_ "UserSigValidity" SG_ 549 CLU_AvgFuelCnsmptnVal 3;
BA_ "GenSigTimeoutTime" SG_ 549 CLU_AvgFuelCnsmptnVal 1500;
BA_ "RoutingFactor" SG_ 549 CLU_AvgFuelCnsmptnVal 2;
BA_ "Version" SG_ 549 CLU_AvgFuelCnsmptnVal "17.11.00";
BA_ "Description" SG_ 549 CLU_AvgFuelCnsmptnUnitSta "This signal indicates the unit of average fuel consumption displayed in the trip computer.
This signal is applied to the case cluster displays in the trip-computer.";
BA_ "UserSigValidity" SG_ 549 CLU_AvgFuelCnsmptnUnitSta 3;
BA_ "GenSigTimeoutTime" SG_ 549 CLU_AvgFuelCnsmptnUnitSta 1500;
BA_ "RoutingFactor" SG_ 549 CLU_AvgFuelCnsmptnUnitSta 2;
BA_ "Version" SG_ 549 CLU_AvgFuelCnsmptnUnitSta "17.11.00";
BA_ "Description" SG_ 549 CLU_LoFuelWrngSta "This signal indicates that the Low fuel warning in the cluster is On or Off. When Low Fuel Warning is On, its value is 01H otherwise its value is 00H.";
BA_ "UserSigValidity" SG_ 549 CLU_LoFuelWrngSta 3;
BA_ "GenSigTimeoutTime" SG_ 549 CLU_LoFuelWrngSta 1500;
BA_ "RoutingFactor" SG_ 549 CLU_LoFuelWrngSta 2;
BA_ "Version" SG_ 549 CLU_LoFuelWrngSta "17.11.00";
BA_ "Description" SG_ 549 CLU_RefuelDetSta "This signal sends the refuel detected status to the tele-matics control unit. 
It transfers 3 times during refuel detected event why if valid one is missing, valid signals are used for extra signal.";
BA_ "UserSigValidity" SG_ 549 CLU_RefuelDetSta 3;
BA_ "GenSigTimeoutTime" SG_ 549 CLU_RefuelDetSta 1500;
BA_ "RoutingFactor" SG_ 549 CLU_RefuelDetSta 2;
BA_ "Version" SG_ 549 CLU_RefuelDetSta "17.11.00";
BA_ "Description" SG_ 549 CLU_TerrainMainSwSta "This signal represents the terrain mode main switch's state.
0x1:On-Road /0x2:Off-Road";
BA_ "UserSigValidity" SG_ 549 CLU_TerrainMainSwSta 3;
BA_ "GenSigTimeoutTime" SG_ 549 CLU_TerrainMainSwSta 1500;
BA_ "RoutingFactor" SG_ 549 CLU_TerrainMainSwSta 2;
BA_ "Version" SG_ 549 CLU_TerrainMainSwSta "18.04.00";
BA_ "Description" SG_ 549 CLU_LngSta "Language Info. for Display Font";
BA_ "UserSigValidity" SG_ 549 CLU_LngSta 3;
BA_ "GenSigTimeoutTime" SG_ 549 CLU_LngSta 1500;
BA_ "RoutingFactor" SG_ 549 CLU_LngSta 2;
BA_ "Version" SG_ 549 CLU_LngSta "17.11.00";
BA_ "Description" SG_ 549 CLU_SRSWrngLmpSta "This signal is generated by one of the following 5 self-diagnostic result of micro-controller of Cluster.
1) “Lamp ON” status as a self-status diagnostic result of cluster
2) “Lamp OFF” status as a self-status diagnostic result of cluster
3) “Lamp flashing with 1hz frequency / 50% duty ratio” as a self-status result diagnostic result of cluster
4) “Lamp Circuit Failure” as a self-diagnostic result of cluster circuit 
5) “No Valid ACU message” as ACU4 message check result by cluster

Note to be taken that CLU2 message does not include judgment on “SRS W/Lamp failure in terms of airbag system”. CLU2 message only contains “status and diagnostic result of Cluster itself”.";
BA_ "UserSigValidity" SG_ 549 CLU_SRSWrngLmpSta 3;
BA_ "GenSigTimeoutTime" SG_ 549 CLU_SRSWrngLmpSta 1500;
BA_ "RoutingFactor" SG_ 549 CLU_SRSWrngLmpSta 2;
BA_ "Version" SG_ 549 CLU_SRSWrngLmpSta "17.12.03";
BA_ "Description" SG_ 549 CLU_OdoVal "This signal indicates mileage counter of a vehicle. Cluster calculates total mileage and sends it to SCC and CUBIS. This value shall be the same with the mileage that is displayed to a driver.";
BA_ "UserSigValidity" SG_ 549 CLU_OdoVal 3;
BA_ "GenSigTimeoutTime" SG_ 549 CLU_OdoVal 1500;
BA_ "RoutingFactor" SG_ 549 CLU_OdoVal 2;
BA_ "Version" SG_ 549 CLU_OdoVal "17.11.00";
BA_ "Description" SG_ 549 CLU_DawLastBrkTimeVal "This signal indicates that the elapsed time count after last driver's break. The elapsed time count increase 1 at an interval of 30 minutes.";
BA_ "UserSigValidity" SG_ 549 CLU_DawLastBrkTimeVal 3;
BA_ "GenSigTimeoutTime" SG_ 549 CLU_DawLastBrkTimeVal 1500;
BA_ "RoutingFactor" SG_ 549 CLU_DawLastBrkTimeVal 2;
BA_ "Version" SG_ 549 CLU_DawLastBrkTimeVal "17.11.00";
BA_ "GenMsgCycleTime" BO_ 1233 0;
BA_ "GenMsgDelayTime" BO_ 1233 0;
BA_ "VFrameFormat" BO_ 1233 14;
BA_ "Description" SG_ 1233 CLU_Crc5Val "The data area for CRC calculation is based on the data length (DLC) of the message DB.
The CRC shall be calculated over the entire data block (excluding the CRC bytes) including the user data, alive counter and Data ID
 
- CRC Polynomial (0x1021) , Initial Value : 0xFFFF, XOR value : 0x0000, Data ID : Message ID + 0xF800 
- The initial value is for CRC calculation and the message should be sent with the calculated result value. 
- The mathematical expression to 16 bit CRC polynomial is given here. G(x) = x16 + x12 + x5 + 1";
BA_ "GenSigSendType" SG_ 1233 CLU_Crc5Val 4;
BA_ "GenSigStartValue" SG_ 1233 CLU_Crc5Val 65535;
BA_ "UserSigValidity" SG_ 1233 CLU_Crc5Val 3;
BA_ "GenSigTimeoutTime" SG_ 1233 CLU_Crc5Val 0;
BA_ "Version" SG_ 1233 CLU_Crc5Val "18.11.08";
BA_ "Description" SG_ 1233 CLU_AlvCnt5Val "For the first transmission request for a data element the counter shall be initialized with 0 and shall be incremented by 1 for every subsequent send request. 
When the counter reaches the maximum value(0xFF), then it shall restart with 0 for the next send request";
BA_ "GenSigSendType" SG_ 1233 CLU_AlvCnt5Val 4;
BA_ "UserSigValidity" SG_ 1233 CLU_AlvCnt5Val 3;
BA_ "GenSigTimeoutTime" SG_ 1233 CLU_AlvCnt5Val 0;
BA_ "Version" SG_ 1233 CLU_AlvCnt5Val "18.11.08";
BA_ "Description" SG_ 1233 USM_StaRst1Req "This signal is used for a request to reset the value of USM menus.
When this signal change, the message (CLU16) is sent 3 times.";
BA_ "GenSigSendType" SG_ 1233 USM_StaRst1Req 4;
BA_ "UserSigValidity" SG_ 1233 USM_StaRst1Req 3;
BA_ "GenSigTimeoutTime" SG_ 1233 USM_StaRst1Req 0;
BA_ "Version" SG_ 1233 USM_StaRst1Req "17.11.00";
BA_ "GenMsgCycleTime" BO_ 1235 0;
BA_ "GenMsgDelayTime" BO_ 1235 0;
BA_ "VFrameFormat" BO_ 1235 14;
BA_ "Description" SG_ 1235 CLU_Crc7Val "The data area for CRC calculation is based on the data length (DLC) of the message DB.
The CRC shall be calculated over the entire data block (excluding the CRC bytes) including the user data, alive counter and Data ID
 
- CRC Polynomial (0x1021) , Initial Value : 0xFFFF, XOR value : 0x0000, Data ID : Message ID + 0xF800 
- The initial value is for CRC calculation and the message should be sent with the calculated result value. 
- The mathematical expression to 16 bit CRC polynomial is given here. G(x) = x16 + x12 + x5 + 1";
BA_ "GenSigSendType" SG_ 1235 CLU_Crc7Val 4;
BA_ "GenSigStartValue" SG_ 1235 CLU_Crc7Val 65535;
BA_ "UserSigValidity" SG_ 1235 CLU_Crc7Val 3;
BA_ "GenSigTimeoutTime" SG_ 1235 CLU_Crc7Val 0;
BA_ "Version" SG_ 1235 CLU_Crc7Val "18.11.08";
BA_ "Description" SG_ 1235 CLU_AlvCnt7Val "For the first transmission request for a data element the counter shall be initialized with 0 and shall be incremented by 1 for every subsequent send request. 
When the counter reaches the maximum value(0xFF), then it shall restart with 0 for the next send request";
BA_ "GenSigSendType" SG_ 1235 CLU_AlvCnt7Val 4;
BA_ "UserSigValidity" SG_ 1235 CLU_AlvCnt7Val 3;
BA_ "GenSigTimeoutTime" SG_ 1235 CLU_AlvCnt7Val 0;
BA_ "Version" SG_ 1235 CLU_AlvCnt7Val "18.11.08";
BA_ "Description" SG_ 1235 USM_AutoDrLkSetReq "Request set the new Auto Door Lock Mode";
BA_ "GenSigSendType" SG_ 1235 USM_AutoDrLkSetReq 4;
BA_ "UserSigValidity" SG_ 1235 USM_AutoDrLkSetReq 3;
BA_ "GenSigTimeoutTime" SG_ 1235 USM_AutoDrLkSetReq 0;
BA_ "Version" SG_ 1235 USM_AutoDrLkSetReq "17.11.00";
BA_ "Description" SG_ 1235 USM_AutoDrUnlckSetReq "Request to set Auto Door Unlock Mode";
BA_ "GenSigSendType" SG_ 1235 USM_AutoDrUnlckSetReq 4;
BA_ "UserSigValidity" SG_ 1235 USM_AutoDrUnlckSetReq 3;
BA_ "GenSigTimeoutTime" SG_ 1235 USM_AutoDrUnlckSetReq 0;
BA_ "Version" SG_ 1235 USM_AutoDrUnlckSetReq "17.11.00";
BA_ "Description" SG_ 1235 USM_HLmpEscrtSetReq "Request to set Head Lamp Escort Option";
BA_ "GenSigSendType" SG_ 1235 USM_HLmpEscrtSetReq 4;
BA_ "UserSigValidity" SG_ 1235 USM_HLmpEscrtSetReq 3;
BA_ "GenSigTimeoutTime" SG_ 1235 USM_HLmpEscrtSetReq 0;
BA_ "Version" SG_ 1235 USM_HLmpEscrtSetReq "17.11.00";
BA_ "Description" SG_ 1235 USM_SmrtTrnkSetReq "Request to set Smart Trunk/Tailgate Mode";
BA_ "GenSigSendType" SG_ 1235 USM_SmrtTrnkSetReq 4;
BA_ "UserSigValidity" SG_ 1235 USM_SmrtTrnkSetReq 3;
BA_ "GenSigTimeoutTime" SG_ 1235 USM_SmrtTrnkSetReq 0;
BA_ "Version" SG_ 1235 USM_SmrtTrnkSetReq "17.11.00";
BA_ "Description" SG_ 1235 USM_HrnAnswerBckSetReq "Request to set Horn Answer Back Mode";
BA_ "GenSigSendType" SG_ 1235 USM_HrnAnswerBckSetReq 4;
BA_ "UserSigValidity" SG_ 1235 USM_HrnAnswerBckSetReq 3;
BA_ "GenSigTimeoutTime" SG_ 1235 USM_HrnAnswerBckSetReq 0;
BA_ "Version" SG_ 1235 USM_HrnAnswerBckSetReq "17.11.00";
BA_ "Description" SG_ 1235 USM_OneTouchTrplTrnSetReq "This signal is used for a request current setting value of USM Menus. When this signal change, the message (CLU14) is sent 3 times.";
BA_ "GenSigSendType" SG_ 1235 USM_OneTouchTrplTrnSetReq 4;
BA_ "UserSigValidity" SG_ 1235 USM_OneTouchTrplTrnSetReq 3;
BA_ "GenSigTimeoutTime" SG_ 1235 USM_OneTouchTrplTrnSetReq 0;
BA_ "Version" SG_ 1235 USM_OneTouchTrplTrnSetReq "17.11.00";
BA_ "Description" SG_ 1235 USM_PsmSetReq "This signal is used for a request to set the value of UMS Menus.
This signal requests to set Seat Easy Access Mode.
When this signal change, the message (CLU14) is sent 3 times.";
BA_ "GenSigSendType" SG_ 1235 USM_PsmSetReq 4;
BA_ "UserSigValidity" SG_ 1235 USM_PsmSetReq 3;
BA_ "GenSigTimeoutTime" SG_ 1235 USM_PsmSetReq 0;
BA_ "Version" SG_ 1235 USM_PsmSetReq "17.11.00";
BA_ "Description" SG_ 1235 USM_PtgmSetReq "Request to set PTGM Mode";
BA_ "GenSigSendType" SG_ 1235 USM_PtgmSetReq 4;
BA_ "UserSigValidity" SG_ 1235 USM_PtgmSetReq 3;
BA_ "GenSigTimeoutTime" SG_ 1235 USM_PtgmSetReq 0;
BA_ "Version" SG_ 1235 USM_PtgmSetReq "17.11.00";
BA_ "Description" SG_ 1235 USM_OSTempUnitSetReq "This signal is used for a request to set the value of USM Menus. This signal requests to set Outside Temperature Unit.
When this signal change, the message (CLU14) is sent 3 times.";
BA_ "GenSigSendType" SG_ 1235 USM_OSTempUnitSetReq 4;
BA_ "UserSigValidity" SG_ 1235 USM_OSTempUnitSetReq 3;
BA_ "GenSigTimeoutTime" SG_ 1235 USM_OSTempUnitSetReq 0;
BA_ "Version" SG_ 1235 USM_OSTempUnitSetReq "17.11.00";
BA_ "Description" SG_ 1235 USM_WALModSetreq "This signal is used for a request to set the value USM Menus.
This signal requests to set WAL(WalkAwayLock) function";
BA_ "GenSigSendType" SG_ 1235 USM_WALModSetreq 4;
BA_ "UserSigValidity" SG_ 1235 USM_WALModSetreq 3;
BA_ "GenSigTimeoutTime" SG_ 1235 USM_WALModSetreq 0;
BA_ "Version" SG_ 1235 USM_WALModSetreq "18.10.02";
BA_ "GenMsgCycleTime" BO_ 1236 0;
BA_ "GenMsgDelayTime" BO_ 1236 0;
BA_ "VFrameFormat" BO_ 1236 14;
BA_ "Description" SG_ 1236 CLU_Crc8Val "The data area for CRC calculation is based on the data length (DLC) of the message DB.
The CRC shall be calculated over the entire data block (excluding the CRC bytes) including the user data, alive counter and Data ID
 
- CRC Polynomial (0x1021) , Initial Value : 0xFFFF, XOR value : 0x0000, Data ID : Message ID + 0xF800 
- The initial value is for CRC calculation and the message should be sent with the calculated result value. 
- The mathematical expression to 16 bit CRC polynomial is given here. G(x) = x16 + x12 + x5 + 1";
BA_ "GenSigSendType" SG_ 1236 CLU_Crc8Val 4;
BA_ "GenSigStartValue" SG_ 1236 CLU_Crc8Val 65535;
BA_ "UserSigValidity" SG_ 1236 CLU_Crc8Val 3;
BA_ "GenSigTimeoutTime" SG_ 1236 CLU_Crc8Val 0;
BA_ "Version" SG_ 1236 CLU_Crc8Val "18.11.08";
BA_ "Description" SG_ 1236 CLU_AlvCnt8Val "For the first transmission request for a data element the counter shall be initialized with 0 and shall be incremented by 1 for every subsequent send request. 
When the counter reaches the maximum value(0xFF), then it shall restart with 0 for the next send request";
BA_ "GenSigSendType" SG_ 1236 CLU_AlvCnt8Val 4;
BA_ "UserSigValidity" SG_ 1236 CLU_AlvCnt8Val 3;
BA_ "GenSigTimeoutTime" SG_ 1236 CLU_AlvCnt8Val 0;
BA_ "Version" SG_ 1236 CLU_AlvCnt8Val "18.11.08";
BA_ "Description" SG_ 1236 USM_TwoTrnUnlckSetReq "Request to set Two Turn Unlock Mode";
BA_ "GenSigSendType" SG_ 1236 USM_TwoTrnUnlckSetReq 4;
BA_ "UserSigValidity" SG_ 1236 USM_TwoTrnUnlckSetReq 3;
BA_ "GenSigTimeoutTime" SG_ 1236 USM_TwoTrnUnlckSetReq 0;
BA_ "Version" SG_ 1236 USM_TwoTrnUnlckSetReq "17.11.00";
BA_ "Description" SG_ 1236 USM_ECoastSetReq "This signal is used for a request to set the value of USM Menus. This signal requests to set E-Coasting system state.

When this signal change, the message (CLU16) is sent 3 times.";
BA_ "GenSigSendType" SG_ 1236 USM_ECoastSetReq 4;
BA_ "UserSigValidity" SG_ 1236 USM_ECoastSetReq 3;
BA_ "GenSigTimeoutTime" SG_ 1236 USM_ECoastSetReq 0;
BA_ "Version" SG_ 1236 USM_ECoastSetReq "17.11.00";
BA_ "Description" SG_ 1236 USM_ECoastingWrngSndSetReq "This signal is used for a request to set the value of USM Menus. This signal requests to set warning sound state for e-Coasting system.
When this signal change, the message (CLU16) is sent 3 times.";
BA_ "GenSigSendType" SG_ 1236 USM_ECoastingWrngSndSetReq 4;
BA_ "UserSigValidity" SG_ 1236 USM_ECoastingWrngSndSetReq 3;
BA_ "GenSigTimeoutTime" SG_ 1236 USM_ECoastingWrngSndSetReq 0;
BA_ "Version" SG_ 1236 USM_ECoastingWrngSndSetReq "17.11.00";
BA_ "Description" SG_ 1236 USM_MdLmpBrgtnsSetReq "Request set the Mood Lamp Brightness";
BA_ "GenSigSendType" SG_ 1236 USM_MdLmpBrgtnsSetReq 4;
BA_ "UserSigValidity" SG_ 1236 USM_MdLmpBrgtnsSetReq 3;
BA_ "GenSigTimeoutTime" SG_ 1236 USM_MdLmpBrgtnsSetReq 0;
BA_ "Version" SG_ 1236 USM_MdLmpBrgtnsSetReq "17.11.00";
BA_ "Description" SG_ 1236 USM_TirePrsrUnitSetReq "This signal is used for a request to set the value of USM Menus. This signal requests to set Tire Pressure Unit.

When this signal change, the message (CLU16) is sent 3 times.";
BA_ "GenSigSendType" SG_ 1236 USM_TirePrsrUnitSetReq 4;
BA_ "UserSigValidity" SG_ 1236 USM_TirePrsrUnitSetReq 3;
BA_ "GenSigTimeoutTime" SG_ 1236 USM_TirePrsrUnitSetReq 0;
BA_ "Version" SG_ 1236 USM_TirePrsrUnitSetReq "17.11.00";
BA_ "Description" SG_ 1236 USM_FuelGdRstReq "This signal is used for a request to reset the Fuel efficiency percent.
When this signal change, the message (CLU16) is sent 3 times.";
BA_ "GenSigSendType" SG_ 1236 USM_FuelGdRstReq 4;
BA_ "UserSigValidity" SG_ 1236 USM_FuelGdRstReq 3;
BA_ "GenSigTimeoutTime" SG_ 1236 USM_FuelGdRstReq 0;
BA_ "Version" SG_ 1236 USM_FuelGdRstReq "17.11.00";
BA_ "GenMsgCycleTime" BO_ 1242 0;
BA_ "GenMsgDelayTime" BO_ 1242 0;
BA_ "VFrameFormat" BO_ 1242 14;
BA_ "Description" SG_ 1242 CLU_Crc9Val "The data area for CRC calculation is based on the data length (DLC) of the message DB.
The CRC shall be calculated over the entire data block (excluding the CRC bytes) including the user data, alive counter and Data ID
 
- CRC Polynomial (0x1021) , Initial Value : 0xFFFF, XOR value : 0x0000, Data ID : Message ID + 0xF800 
- The initial value is for CRC calculation and the message should be sent with the calculated result value. 
- The mathematical expression to 16 bit CRC polynomial is given here. G(x) = x16 + x12 + x5 + 1";
BA_ "GenSigSendType" SG_ 1242 CLU_Crc9Val 4;
BA_ "GenSigStartValue" SG_ 1242 CLU_Crc9Val 65535;
BA_ "UserSigValidity" SG_ 1242 CLU_Crc9Val 3;
BA_ "GenSigTimeoutTime" SG_ 1242 CLU_Crc9Val 0;
BA_ "Version" SG_ 1242 CLU_Crc9Val "18.11.08";
BA_ "Description" SG_ 1242 CLU_AlvCnt9Val "For the first transmission request for a data element the counter shall be initialized with 0 and shall be incremented by 1 for every subsequent send request. 
When the counter reaches the maximum value(0xFF), then it shall restart with 0 for the next send request";
BA_ "GenSigSendType" SG_ 1242 CLU_AlvCnt9Val 4;
BA_ "UserSigValidity" SG_ 1242 CLU_AlvCnt9Val 3;
BA_ "GenSigTimeoutTime" SG_ 1242 CLU_AlvCnt9Val 0;
BA_ "Version" SG_ 1242 CLU_AlvCnt9Val "18.11.08";
BA_ "Description" SG_ 1242 USM_MdLmpClrSetReq "Request set the Mood Lamp Color";
BA_ "GenSigSendType" SG_ 1242 USM_MdLmpClrSetReq 4;
BA_ "UserSigValidity" SG_ 1242 USM_MdLmpClrSetReq 3;
BA_ "GenSigTimeoutTime" SG_ 1242 USM_MdLmpClrSetReq 0;
BA_ "Version" SG_ 1242 USM_MdLmpClrSetReq "17.11.00";
BA_ "Description" SG_ 1242 USM_RrWiperRevSetReq "Request to set RearWiper Reverse Mode";
BA_ "GenSigSendType" SG_ 1242 USM_RrWiperRevSetReq 4;
BA_ "UserSigValidity" SG_ 1242 USM_RrWiperRevSetReq 3;
BA_ "GenSigTimeoutTime" SG_ 1242 USM_RrWiperRevSetReq 0;
BA_ "Version" SG_ 1242 USM_RrWiperRevSetReq "17.11.00";
BA_ "Description" SG_ 1242 USM_RrStRemindSetReq "USM Function for RearSeatReminder on/off SW";
BA_ "GenSigSendType" SG_ 1242 USM_RrStRemindSetReq 4;
BA_ "UserSigValidity" SG_ 1242 USM_RrStRemindSetReq 3;
BA_ "GenSigTimeoutTime" SG_ 1242 USM_RrStRemindSetReq 0;
BA_ "Version" SG_ 1242 USM_RrStRemindSetReq "19.01.04";
BA_ "Description" SG_ 1242 USM_RrWpcSetReq "USM Function for REAR WPC(Wireless Phone Chager) on/off SW";
BA_ "GenSigSendType" SG_ 1242 USM_RrWpcSetReq 4;
BA_ "UserSigValidity" SG_ 1242 USM_RrWpcSetReq 3;
BA_ "GenSigTimeoutTime" SG_ 1242 USM_RrWpcSetReq 0;
BA_ "Version" SG_ 1242 USM_RrWpcSetReq "17.11.00";
BA_ "Description" SG_ 1242 USM_WpcSetReq "USM Function for WPC(Wireless Phone Chager) on/off SW";
BA_ "GenSigSendType" SG_ 1242 USM_WpcSetReq 4;
BA_ "UserSigValidity" SG_ 1242 USM_WpcSetReq 3;
BA_ "GenSigTimeoutTime" SG_ 1242 USM_WpcSetReq 0;
BA_ "Version" SG_ 1242 USM_WpcSetReq "17.11.00";
BA_ "Description" SG_ 1242 USM_UnlckWlcmSetReq "This signal is used for a request to set the value of USM Menus. This signal requests to change status of Welcome System setting.


When this signal change, the message (CLU18) is sent 3 times.";
BA_ "GenSigSendType" SG_ 1242 USM_UnlckWlcmSetReq 4;
BA_ "UserSigValidity" SG_ 1242 USM_UnlckWlcmSetReq 3;
BA_ "GenSigTimeoutTime" SG_ 1242 USM_UnlckWlcmSetReq 0;
BA_ "Version" SG_ 1242 USM_UnlckWlcmSetReq "17.11.00";
BA_ "Description" SG_ 1242 USM_SmrtWlcmSetReq "This signal is used for a request to set the value of USM Menus. This signal requests to change status of Welcome System setting.


When this signal change, the message (CLU18) is sent 3 times.";
BA_ "GenSigSendType" SG_ 1242 USM_SmrtWlcmSetReq 4;
BA_ "UserSigValidity" SG_ 1242 USM_SmrtWlcmSetReq 3;
BA_ "GenSigTimeoutTime" SG_ 1242 USM_SmrtWlcmSetReq 0;
BA_ "Version" SG_ 1242 USM_SmrtWlcmSetReq "17.11.00";
BA_ "Description" SG_ 1242 USM_UipSetReq "Request to set Uip(Ultrasonic Intrusion Protection)
This signal is used for a request to set the value of USM Menus. 
When this signal change, the message is sent 3 times.";
BA_ "GenSigSendType" SG_ 1242 USM_UipSetReq 4;
BA_ "UserSigValidity" SG_ 1242 USM_UipSetReq 3;
BA_ "GenSigTimeoutTime" SG_ 1242 USM_UipSetReq 0;
BA_ "Version" SG_ 1242 USM_UipSetReq "18.11.07";
BA_ "Description" SG_ 1242 USM_DigitalKeyEnblSetReq "This signal is used for a request to set the value of USM Menus. This signal requests to set Digital Key On/Off.";
BA_ "GenSigSendType" SG_ 1242 USM_DigitalKeyEnblSetReq 4;
BA_ "UserSigValidity" SG_ 1242 USM_DigitalKeyEnblSetReq 3;
BA_ "GenSigTimeoutTime" SG_ 1242 USM_DigitalKeyEnblSetReq 0;
BA_ "Version" SG_ 1242 USM_DigitalKeyEnblSetReq "18.11.00";
BA_ "Description" SG_ 1242 USM_OwnerPhnRegSetReq "This signal is used for a request to set the value of USM Menus.
This signal requests to set Digital Key On/Off";
BA_ "GenSigSendType" SG_ 1242 USM_OwnerPhnRegSetReq 4;
BA_ "UserSigValidity" SG_ 1242 USM_OwnerPhnRegSetReq 3;
BA_ "GenSigTimeoutTime" SG_ 1242 USM_OwnerPhnRegSetReq 0;
BA_ "Version" SG_ 1242 USM_OwnerPhnRegSetReq "18.11.00";
BA_ "Description" SG_ 1242 USM_NFCCard1RegSetReq "This signal is used for a request to set the value of USM Menus. This signal requests to go through the process for NFC Card 1 recoding.";
BA_ "GenSigSendType" SG_ 1242 USM_NFCCard1RegSetReq 4;
BA_ "UserSigValidity" SG_ 1242 USM_NFCCard1RegSetReq 3;
BA_ "GenSigTimeoutTime" SG_ 1242 USM_NFCCard1RegSetReq 0;
BA_ "Version" SG_ 1242 USM_NFCCard1RegSetReq "18.11.00";
BA_ "Description" SG_ 1242 USM_ProcStpReq "This signal is used for a request to escape the IAU Authorizaton processing";
BA_ "GenSigSendType" SG_ 1242 USM_ProcStpReq 4;
BA_ "UserSigValidity" SG_ 1242 USM_ProcStpReq 3;
BA_ "GenSigTimeoutTime" SG_ 1242 USM_ProcStpReq 0;
BA_ "Version" SG_ 1242 USM_ProcStpReq "18.11.00";
BA_ "GenMsgCycleTime" BO_ 1243 0;
BA_ "GenMsgDelayTime" BO_ 1243 0;
BA_ "VFrameFormat" BO_ 1243 14;
BA_ "Description" SG_ 1243 CLU_Crc10Val "The data area for CRC calculation is based on the data length (DLC) of the message DB.
The CRC shall be calculated over the entire data block (excluding the CRC bytes) including the user data, alive counter and Data ID
 
- CRC Polynomial (0x1021) , Initial Value : 0xFFFF, XOR value : 0x0000, Data ID : Message ID + 0xF800 
- The initial value is for CRC calculation and the message should be sent with the calculated result value. 
- The mathematical expression to 16 bit CRC polynomial is given here. G(x) = x16 + x12 + x5 + 1";
BA_ "GenSigSendType" SG_ 1243 CLU_Crc10Val 4;
BA_ "GenSigStartValue" SG_ 1243 CLU_Crc10Val 65535;
BA_ "UserSigValidity" SG_ 1243 CLU_Crc10Val 3;
BA_ "GenSigTimeoutTime" SG_ 1243 CLU_Crc10Val 0;
BA_ "Version" SG_ 1243 CLU_Crc10Val "18.11.08";
BA_ "Description" SG_ 1243 CLU_AlvCnt10Val "For the first transmission request for a data element the counter shall be initialized with 0 and shall be incremented by 1 for every subsequent send request. 
When the counter reaches the maximum value(0xFF), then it shall restart with 0 for the next send request";
BA_ "GenSigSendType" SG_ 1243 CLU_AlvCnt10Val 4;
BA_ "UserSigValidity" SG_ 1243 CLU_AlvCnt10Val 3;
BA_ "GenSigTimeoutTime" SG_ 1243 CLU_AlvCnt10Val 0;
BA_ "Version" SG_ 1243 CLU_AlvCnt10Val "18.11.08";
BA_ "Description" SG_ 1243 USM_PtgSpdSetReq "This signal is used for a request to set the value of USM Menus. This signal requests to set the operating speed of power tailgate.
When this signal cange, the message (CLU18) is sent 3 times.";
BA_ "GenSigSendType" SG_ 1243 USM_PtgSpdSetReq 4;
BA_ "UserSigValidity" SG_ 1243 USM_PtgSpdSetReq 3;
BA_ "GenSigTimeoutTime" SG_ 1243 USM_PtgSpdSetReq 0;
BA_ "Version" SG_ 1243 USM_PtgSpdSetReq "17.11.00";
BA_ "GenMsgCycleTime" BO_ 1144 0;
BA_ "GenMsgDelayTime" BO_ 1144 0;
BA_ "VFrameFormat" BO_ 1144 14;
BA_ "Description" SG_ 1144 CLU_Crc11Val "The data area for CRC calculation is based on the data length (DLC) of the message DB.
The CRC shall be calculated over the entire data block (excluding the CRC bytes) including the user data, alive counter and Data ID
 
- CRC Polynomial (0x1021) , Initial Value : 0xFFFF, XOR value : 0x0000, Data ID : Message ID + 0xF800 
- The initial value is for CRC calculation and the message should be sent with the calculated result value. 
- The mathematical expression to 16 bit CRC polynomial is given here. G(x) = x16 + x12 + x5 + 1";
BA_ "GenSigSendType" SG_ 1144 CLU_Crc11Val 4;
BA_ "GenSigStartValue" SG_ 1144 CLU_Crc11Val 65535;
BA_ "UserSigValidity" SG_ 1144 CLU_Crc11Val 3;
BA_ "GenSigTimeoutTime" SG_ 1144 CLU_Crc11Val 0;
BA_ "Version" SG_ 1144 CLU_Crc11Val "18.11.08";
BA_ "Description" SG_ 1144 CLU_AlvCnt11Val "For the first transmission request for a data element the counter shall be initialized with 0 and shall be incremented by 1 for every subsequent send request. 
When the counter reaches the maximum value(0xFF), then it shall restart with 0 for the next send request";
BA_ "GenSigSendType" SG_ 1144 CLU_AlvCnt11Val 4;
BA_ "UserSigValidity" SG_ 1144 CLU_AlvCnt11Val 3;
BA_ "GenSigTimeoutTime" SG_ 1144 CLU_AlvCnt11Val 0;
BA_ "Version" SG_ 1144 CLU_AlvCnt11Val "18.11.08";
BA_ "Description" SG_ 1144 CLU_ICUDlvrModOffSetReq "This signal is used for a request to set off the delivery mode for ICU";
BA_ "GenSigSendType" SG_ 1144 CLU_ICUDlvrModOffSetReq 4;
BA_ "UserSigValidity" SG_ 1144 CLU_ICUDlvrModOffSetReq 3;
BA_ "GenSigTimeoutTime" SG_ 1144 CLU_ICUDlvrModOffSetReq 0;
BA_ "Version" SG_ 1144 CLU_ICUDlvrModOffSetReq "17.12.03";
BA_ "Description" SG_ 1144 CLU_DrvngLampChgnSta "This signal sends driving mode lamp status when driving mode changes.";
BA_ "GenSigSendType" SG_ 1144 CLU_DrvngLampChgnSta 4;
BA_ "UserSigValidity" SG_ 1144 CLU_DrvngLampChgnSta 3;
BA_ "GenSigTimeoutTime" SG_ 1144 CLU_DrvngLampChgnSta 0;
BA_ "Version" SG_ 1144 CLU_DrvngLampChgnSta "17.12.03";
BA_ "Description" SG_ 1144 CLU_TerrainModChgn "This signal indicates Terrain(OffRoad) mode status when terrain mode changes in cluster.
(Snow, Sand, Mud, Ready)";
BA_ "GenSigSendType" SG_ 1144 CLU_TerrainModChgn 4;
BA_ "UserSigValidity" SG_ 1144 CLU_TerrainModChgn 3;
BA_ "GenSigTimeoutTime" SG_ 1144 CLU_TerrainModChgn 0;
BA_ "Version" SG_ 1144 CLU_TerrainModChgn "18.08.01";
BA_ "Description" SG_ 1144 CLU_ADASSetShortcut_Req "Shortcut signal for ADAS menu quick launch (CLU -> AVN)";
BA_ "GenSigSendType" SG_ 1144 CLU_ADASSetShortcut_Req 4;
BA_ "UserSigValidity" SG_ 1144 CLU_ADASSetShortcut_Req 3;
BA_ "GenSigTimeoutTime" SG_ 1144 CLU_ADASSetShortcut_Req 0;
BA_ "Version" SG_ 1144 CLU_ADASSetShortcut_Req "18.08.10";
BA_ "Description" SG_ 1144 CLU_SbwNModReq "This signal is for N Mode request in SBW variant";
BA_ "GenSigSendType" SG_ 1144 CLU_SbwNModReq 4;
BA_ "UserSigValidity" SG_ 1144 CLU_SbwNModReq 3;
BA_ "GenSigTimeoutTime" SG_ 1144 CLU_SbwNModReq 0;
BA_ "Version" SG_ 1144 CLU_SbwNModReq "18.08.10";
BA_ "Description" SG_ 1144 CLU_RrStRemindOffSetReq "Request to set off the Rear Seat Remind 2nd Alarm";
BA_ "GenSigSendType" SG_ 1144 CLU_RrStRemindOffSetReq 4;
BA_ "UserSigValidity" SG_ 1144 CLU_RrStRemindOffSetReq 0;
BA_ "GenSigTimeoutTime" SG_ 1144 CLU_RrStRemindOffSetReq 0;
BA_ "Version" SG_ 1144 CLU_RrStRemindOffSetReq "18.09.00";
BA_ "Description" SG_ 1144 CLU_RrStRemindFdbckSetReq "Signal is if or not 1st ROA alert message in cluster";
BA_ "GenSigSendType" SG_ 1144 CLU_RrStRemindFdbckSetReq 4;
BA_ "UserSigValidity" SG_ 1144 CLU_RrStRemindFdbckSetReq 0;
BA_ "GenSigTimeoutTime" SG_ 1144 CLU_RrStRemindFdbckSetReq 0;
BA_ "Version" SG_ 1144 CLU_RrStRemindFdbckSetReq "18.09.00";
BA_ "Description" SG_ 1144 CF_Clu_HCSSOSStopReq "This signal is used for a request to stop the SOS call.
When this signal change, the message is sent 3 times.";
BA_ "GenSigSendType" SG_ 1144 CF_Clu_HCSSOSStopReq 4;
BA_ "UserSigValidity" SG_ 1144 CF_Clu_HCSSOSStopReq 3;
BA_ "GenSigTimeoutTime" SG_ 1144 CF_Clu_HCSSOSStopReq 0;
BA_ "Version" SG_ 1144 CF_Clu_HCSSOSStopReq "19.01.10";
BA_ "GenMsgCycleTime" BO_ 1145 0;
BA_ "GenMsgDelayTime" BO_ 1145 0;
BA_ "VFrameFormat" BO_ 1145 14;
BA_ "Description" SG_ 1145 CLU_Crc12Val "The data area for CRC calculation is based on the data length (DLC) of the message DB.
The CRC shall be calculated over the entire data block (excluding the CRC bytes) including the user data, alive counter and Data ID
 
- CRC Polynomial (0x1021) , Initial Value : 0xFFFF, XOR value : 0x0000, Data ID : Message ID + 0xF800 
- The initial value is for CRC calculation and the message should be sent with the calculated result value. 
- The mathematical expression to 16 bit CRC polynomial is given here. G(x) = x16 + x12 + x5 + 1";
BA_ "GenSigSendType" SG_ 1145 CLU_Crc12Val 4;
BA_ "GenSigStartValue" SG_ 1145 CLU_Crc12Val 65535;
BA_ "UserSigValidity" SG_ 1145 CLU_Crc12Val 3;
BA_ "GenSigTimeoutTime" SG_ 1145 CLU_Crc12Val 0;
BA_ "Version" SG_ 1145 CLU_Crc12Val "18.11.08";
BA_ "Description" SG_ 1145 CLU_AlvCnt12Val "For the first transmission request for a data element the counter shall be initialized with 0 and shall be incremented by 1 for every subsequent send request. 
When the counter reaches the maximum value(0xFF), then it shall restart with 0 for the next send request";
BA_ "GenSigSendType" SG_ 1145 CLU_AlvCnt12Val 4;
BA_ "UserSigValidity" SG_ 1145 CLU_AlvCnt12Val 3;
BA_ "GenSigTimeoutTime" SG_ 1145 CLU_AlvCnt12Val 0;
BA_ "Version" SG_ 1145 CLU_AlvCnt12Val "18.11.08";
BA_ "Description" SG_ 1145 USM_AdasUSMResetReq "This signal is used for a request to reset of ADAS USM settings.";
BA_ "GenSigSendType" SG_ 1145 USM_AdasUSMResetReq 4;
BA_ "UserSigValidity" SG_ 1145 USM_AdasUSMResetReq 3;
BA_ "GenSigTimeoutTime" SG_ 1145 USM_AdasUSMResetReq 0;
BA_ "Version" SG_ 1145 USM_AdasUSMResetReq "17.12.03";
BA_ "Description" SG_ 1145 USM_AdasFCASetReq "This signal is used for a request to set the value of USM Menus. This signal requests to change status of FCA.";
BA_ "GenSigSendType" SG_ 1145 USM_AdasFCASetReq 4;
BA_ "UserSigValidity" SG_ 1145 USM_AdasFCASetReq 3;
BA_ "GenSigTimeoutTime" SG_ 1145 USM_AdasFCASetReq 0;
BA_ "Version" SG_ 1145 USM_AdasFCASetReq "17.12.03";
BA_ "Description" SG_ 1145 USM_AdasBVMSetReq "This signal is used for a request to set the value of USM Menus. This signal requests to change status of BVM.";
BA_ "GenSigSendType" SG_ 1145 USM_AdasBVMSetReq 4;
BA_ "UserSigValidity" SG_ 1145 USM_AdasBVMSetReq 3;
BA_ "GenSigTimeoutTime" SG_ 1145 USM_AdasBVMSetReq 0;
BA_ "Version" SG_ 1145 USM_AdasBVMSetReq "17.12.03";
BA_ "Description" SG_ 1145 USM_AdasSCCDrvModSetReq "This signal is used for a request to set the value of USM Menus. This signal requests to change status of SCC Driving mode.";
BA_ "GenSigSendType" SG_ 1145 USM_AdasSCCDrvModSetReq 4;
BA_ "UserSigValidity" SG_ 1145 USM_AdasSCCDrvModSetReq 3;
BA_ "GenSigTimeoutTime" SG_ 1145 USM_AdasSCCDrvModSetReq 0;
BA_ "Version" SG_ 1145 USM_AdasSCCDrvModSetReq "17.12.03";
BA_ "Description" SG_ 1145 USM_AdasDAWModSetReq "This signal is used for a request to set the value of USM Menus. This signal requests to change status of DAW.";
BA_ "GenSigSendType" SG_ 1145 USM_AdasDAWModSetReq 4;
BA_ "UserSigValidity" SG_ 1145 USM_AdasDAWModSetReq 3;
BA_ "GenSigTimeoutTime" SG_ 1145 USM_AdasDAWModSetReq 0;
BA_ "Version" SG_ 1145 USM_AdasDAWModSetReq "17.12.03";
BA_ "Description" SG_ 1145 USM_AdasHDASetReq "This signal is used for a request to set the value of USM Menus. This signal requests to change status of HDA.";
BA_ "GenSigSendType" SG_ 1145 USM_AdasHDASetReq 4;
BA_ "UserSigValidity" SG_ 1145 USM_AdasHDASetReq 3;
BA_ "GenSigTimeoutTime" SG_ 1145 USM_AdasHDASetReq 0;
BA_ "Version" SG_ 1145 USM_AdasHDASetReq "17.12.03";
BA_ "Description" SG_ 1145 USM_AdasBCWSetReq "This signal is used for a request to set the value of USM Menus. This signal requests to change status of BCW.";
BA_ "GenSigSendType" SG_ 1145 USM_AdasBCWSetReq 4;
BA_ "UserSigValidity" SG_ 1145 USM_AdasBCWSetReq 3;
BA_ "GenSigTimeoutTime" SG_ 1145 USM_AdasBCWSetReq 0;
BA_ "Version" SG_ 1145 USM_AdasBCWSetReq "17.12.03";
BA_ "Description" SG_ 1145 USM_AdasSEASetReq "This signal is used for a request to set the value of USM Menus. This signal requests to change status of SEA.";
BA_ "GenSigSendType" SG_ 1145 USM_AdasSEASetReq 4;
BA_ "UserSigValidity" SG_ 1145 USM_AdasSEASetReq 3;
BA_ "GenSigTimeoutTime" SG_ 1145 USM_AdasSEASetReq 0;
BA_ "Version" SG_ 1145 USM_AdasSEASetReq "17.12.03";
BA_ "Description" SG_ 1145 USM_AdasNSCCCamSetReq "This signal is used for a request to set the value of USM Menus. This signal requests to change status of NSCC Camera.";
BA_ "GenSigSendType" SG_ 1145 USM_AdasNSCCCamSetReq 4;
BA_ "UserSigValidity" SG_ 1145 USM_AdasNSCCCamSetReq 3;
BA_ "GenSigTimeoutTime" SG_ 1145 USM_AdasNSCCCamSetReq 0;
BA_ "Version" SG_ 1145 USM_AdasNSCCCamSetReq "17.12.03";
BA_ "Description" SG_ 1145 USM_AdasLFASetReq "This signal is used for a request to set the value of USM Menus. This signal requests to change status of LFA.";
BA_ "GenSigSendType" SG_ 1145 USM_AdasLFASetReq 4;
BA_ "UserSigValidity" SG_ 1145 USM_AdasLFASetReq 3;
BA_ "GenSigTimeoutTime" SG_ 1145 USM_AdasLFASetReq 0;
BA_ "Version" SG_ 1145 USM_AdasLFASetReq "17.12.03";
BA_ "Description" SG_ 1145 USM_AdasBCASetReq "This signal is used for a request to set the value of USM Menus. This signal requests to change status of BCA.";
BA_ "GenSigSendType" SG_ 1145 USM_AdasBCASetReq 4;
BA_ "UserSigValidity" SG_ 1145 USM_AdasBCASetReq 3;
BA_ "GenSigTimeoutTime" SG_ 1145 USM_AdasBCASetReq 0;
BA_ "Version" SG_ 1145 USM_AdasBCASetReq "17.12.03";
BA_ "Description" SG_ 1145 USM_AdasWrngTimingSetReq "This signal is used for a request to set the value of USM Menus. This signal requests to change status of ADASWarningTiming.";
BA_ "GenSigSendType" SG_ 1145 USM_AdasWrngTimingSetReq 4;
BA_ "UserSigValidity" SG_ 1145 USM_AdasWrngTimingSetReq 3;
BA_ "GenSigTimeoutTime" SG_ 1145 USM_AdasWrngTimingSetReq 0;
BA_ "Version" SG_ 1145 USM_AdasWrngTimingSetReq "17.12.03";
BA_ "Description" SG_ 1145 USM_AdasLVDASetReq "This signal is used for a request to set the value of USM Menus. This signal requests to change status of LVDA.";
BA_ "GenSigSendType" SG_ 1145 USM_AdasLVDASetReq 4;
BA_ "UserSigValidity" SG_ 1145 USM_AdasLVDASetReq 3;
BA_ "GenSigTimeoutTime" SG_ 1145 USM_AdasLVDASetReq 0;
BA_ "Version" SG_ 1145 USM_AdasLVDASetReq "17.12.03";
BA_ "Description" SG_ 1145 USM_AdasNSCCCrvSetReq "This signal is used for a request to set the value of USM Menus. This signal requests to change status of NSCCCurve.";
BA_ "GenSigSendType" SG_ 1145 USM_AdasNSCCCrvSetReq 4;
BA_ "UserSigValidity" SG_ 1145 USM_AdasNSCCCrvSetReq 3;
BA_ "GenSigTimeoutTime" SG_ 1145 USM_AdasNSCCCrvSetReq 0;
BA_ "Version" SG_ 1145 USM_AdasNSCCCrvSetReq "17.12.03";
BA_ "GenMsgCycleTime" BO_ 1135 0;
BA_ "GenMsgDelayTime" BO_ 1135 0;
BA_ "VFrameFormat" BO_ 1135 14;
BA_ "Description" SG_ 1135 CLU_Crc13Val "The data area for CRC calculation is based on the data length (DLC) of the message DB.
The CRC shall be calculated over the entire data block (excluding the CRC bytes) including the user data, alive counter and Data ID
 
- CRC Polynomial (0x1021) , Initial Value : 0xFFFF, XOR value : 0x0000, Data ID : Message ID + 0xF800 
- The initial value is for CRC calculation and the message should be sent with the calculated result value. 
- The mathematical expression to 16 bit CRC polynomial is given here. G(x) = x16 + x12 + x5 + 1";
BA_ "GenSigSendType" SG_ 1135 CLU_Crc13Val 4;
BA_ "GenSigStartValue" SG_ 1135 CLU_Crc13Val 65535;
BA_ "UserSigValidity" SG_ 1135 CLU_Crc13Val 3;
BA_ "GenSigTimeoutTime" SG_ 1135 CLU_Crc13Val 0;
BA_ "Version" SG_ 1135 CLU_Crc13Val "18.11.08";
BA_ "Description" SG_ 1135 CLU_AlvCnt13Val "For the first transmission request for a data element the counter shall be initialized with 0 and shall be incremented by 1 for every subsequent send request. 
When the counter reaches the maximum value(0xFF), then it shall restart with 0 for the next send request";
BA_ "GenSigSendType" SG_ 1135 CLU_AlvCnt13Val 4;
BA_ "UserSigValidity" SG_ 1135 CLU_AlvCnt13Val 3;
BA_ "GenSigTimeoutTime" SG_ 1135 CLU_AlvCnt13Val 0;
BA_ "Version" SG_ 1135 CLU_AlvCnt13Val "18.11.08";
BA_ "Description" SG_ 1135 USM_AdasBCWSndSetReq "This signal is used for a request to set the value of USM Menus. This signal requests to change status of BCW Sound.";
BA_ "GenSigSendType" SG_ 1135 USM_AdasBCWSndSetReq 4;
BA_ "UserSigValidity" SG_ 1135 USM_AdasBCWSndSetReq 3;
BA_ "GenSigTimeoutTime" SG_ 1135 USM_AdasBCWSndSetReq 0;
BA_ "Version" SG_ 1135 USM_AdasBCWSndSetReq "17.12.03";
BA_ "Description" SG_ 1135 USM_AdasRCCWSetReq "This signal is used for a request to set the value of USM Menus. This signal requests to change status of RCCW.";
BA_ "GenSigSendType" SG_ 1135 USM_AdasRCCWSetReq 4;
BA_ "UserSigValidity" SG_ 1135 USM_AdasRCCWSetReq 3;
BA_ "GenSigTimeoutTime" SG_ 1135 USM_AdasRCCWSetReq 0;
BA_ "Version" SG_ 1135 USM_AdasRCCWSetReq "17.12.03";
BA_ "Description" SG_ 1135 USM_AdasLkaModSetReq "This signal is used for a request to set the value of USM Menus. This signal requests to change status of LKA Mode.";
BA_ "GenSigSendType" SG_ 1135 USM_AdasLkaModSetReq 4;
BA_ "UserSigValidity" SG_ 1135 USM_AdasLkaModSetReq 3;
BA_ "GenSigTimeoutTime" SG_ 1135 USM_AdasLkaModSetReq 0;
BA_ "Version" SG_ 1135 USM_AdasLkaModSetReq "17.12.03";
BA_ "Description" SG_ 1135 USM_AdasFCAJnctnSetReq "This signal is used for a request to set the value of USM Menus. This signal requests to change status of FCA Junction.";
BA_ "GenSigSendType" SG_ 1135 USM_AdasFCAJnctnSetReq 4;
BA_ "UserSigValidity" SG_ 1135 USM_AdasFCAJnctnSetReq 3;
BA_ "GenSigTimeoutTime" SG_ 1135 USM_AdasFCAJnctnSetReq 0;
BA_ "Version" SG_ 1135 USM_AdasFCAJnctnSetReq "18.02.00";
BA_ "Description" SG_ 1135 USM_AdasHDALCFuncSetReq "This signal is used for a request to set the value of USM Menus. This signal requests to change status of HDA LaneChangeFunction";
BA_ "GenSigSendType" SG_ 1135 USM_AdasHDALCFuncSetReq 4;
BA_ "UserSigValidity" SG_ 1135 USM_AdasHDALCFuncSetReq 3;
BA_ "GenSigTimeoutTime" SG_ 1135 USM_AdasHDALCFuncSetReq 0;
BA_ "Version" SG_ 1135 USM_AdasHDALCFuncSetReq "18.04.00";
BA_ "Description" SG_ 1135 USM_AdasPDWAutoOnSetReq "This signal is used for a request to set the value of USM Menus. This signal requests to change status of PDWAutoOnSet";
BA_ "GenSigSendType" SG_ 1135 USM_AdasPDWAutoOnSetReq 4;
BA_ "UserSigValidity" SG_ 1135 USM_AdasPDWAutoOnSetReq 3;
BA_ "GenSigTimeoutTime" SG_ 1135 USM_AdasPDWAutoOnSetReq 0;
BA_ "Version" SG_ 1135 USM_AdasPDWAutoOnSetReq "18.04.00";
BA_ "Description" SG_ 1135 USM_AdasPCAStaSetReq "This signal is used for a request to set the value of USM Menus.";
BA_ "GenSigSendType" SG_ 1135 USM_AdasPCAStaSetReq 4;
BA_ "UserSigValidity" SG_ 1135 USM_AdasPCAStaSetReq 3;
BA_ "GenSigTimeoutTime" SG_ 1135 USM_AdasPCAStaSetReq 0;
BA_ "Version" SG_ 1135 USM_AdasPCAStaSetReq "18.04.00";
BA_ "Description" SG_ 1135 USM_AdasHbaSetReq "This signal is used for a request to set the value of USM Menus.";
BA_ "GenSigSendType" SG_ 1135 USM_AdasHbaSetReq 4;
BA_ "UserSigValidity" SG_ 1135 USM_AdasHbaSetReq 3;
BA_ "GenSigTimeoutTime" SG_ 1135 USM_AdasHbaSetReq 0;
BA_ "Version" SG_ 1135 USM_AdasHbaSetReq "18.04.00";
BA_ "Description" SG_ 1135 USM_AdasSCCModeSetReq "This signal is used for a request to set the value of USM Menus.";
BA_ "GenSigSendType" SG_ 1135 USM_AdasSCCModeSetReq 4;
BA_ "UserSigValidity" SG_ 1135 USM_AdasSCCModeSetReq 3;
BA_ "GenSigTimeoutTime" SG_ 1135 USM_AdasSCCModeSetReq 0;
BA_ "Version" SG_ 1135 USM_AdasSCCModeSetReq "18.12.01";
BA_ "Description" SG_ 1135 USM_AdasSCCMLResetReq "This signal is used for a request to reset of ADAS SCCML.";
BA_ "GenSigSendType" SG_ 1135 USM_AdasSCCMLResetReq 4;
BA_ "UserSigValidity" SG_ 1135 USM_AdasSCCMLResetReq 3;
BA_ "GenSigTimeoutTime" SG_ 1135 USM_AdasSCCMLResetReq 0;
BA_ "Version" SG_ 1135 USM_AdasSCCMLResetReq "18.05.02";
BA_ "Description" SG_ 1135 USM_AdasDAWModNewSetReq "This signal is used for a request to set the value of USM Menus.
If USM setting is changed, the message is sent 3 times.";
BA_ "GenSigSendType" SG_ 1135 USM_AdasDAWModNewSetReq 4;
BA_ "UserSigValidity" SG_ 1135 USM_AdasDAWModNewSetReq 3;
BA_ "GenSigTimeoutTime" SG_ 1135 USM_AdasDAWModNewSetReq 0;
BA_ "Version" SG_ 1135 USM_AdasDAWModNewSetReq "18.07.03";
BA_ "Description" SG_ 1135 USM_AdasSVMAutoOnSetReq "Request to set SVM Auto On";
BA_ "GenSigSendType" SG_ 1135 USM_AdasSVMAutoOnSetReq 4;
BA_ "UserSigValidity" SG_ 1135 USM_AdasSVMAutoOnSetReq 3;
BA_ "GenSigTimeoutTime" SG_ 1135 USM_AdasSVMAutoOnSetReq 0;
BA_ "Version" SG_ 1135 USM_AdasSVMAutoOnSetReq "18.08.10";
BA_ "Description" SG_ 1135 CLU_AdasDAWResetReq "This signal is used for a request to DAW reset request
When this signal change, the message is sent 3 times.";
BA_ "GenSigSendType" SG_ 1135 CLU_AdasDAWResetReq 4;
BA_ "UserSigValidity" SG_ 1135 CLU_AdasDAWResetReq 3;
BA_ "GenSigTimeoutTime" SG_ 1135 CLU_AdasDAWResetReq 0;
BA_ "Version" SG_ 1135 CLU_AdasDAWResetReq "18.12.01";
BA_ "GenMsgSendType" BO_ 384 0;
BA_ "GenMsgCycleTime" BO_ 384 20;
BA_ "GenMsgCycleTimeFast" BO_ 384 0;
BA_ "GenMsgNrOfRepetition" BO_ 384 0;
BA_ "GenMsgDelayTime" BO_ 384 0;
BA_ "VFrameFormat" BO_ 384 14;
BA_ "Description" SG_ 384 CLU_Crc17Val "The CRC checking process calculates the CRC over the entire data block, including the CRC result.
- CRC Polynomial (0x1021) , Initial Value : 0xFFFF, XOR value : 0x0000
- The mathematical expression to 16 bit CRC polynomial is given here. G(x) = x16 + x12 + x5 + 1";
BA_ "GenSigStartValue" SG_ 384 CLU_Crc17Val 65535;
BA_ "UserSigValidity" SG_ 384 CLU_Crc17Val 3;
BA_ "RoutingFactor" SG_ 384 CLU_Crc17Val 5;
BA_ "Version" SG_ 384 CLU_Crc17Val "18.05.01";
BA_ "Description" SG_ 384 CLU_AlvCnt17Val "For the first transmission request for a data element the counter shall be initialized with 0 and shall be incremented by 1
for every subsequent send request. When the counter reaches the maximum value(0xFF), then it shall restart with ? for the next send request";
BA_ "UserSigValidity" SG_ 384 CLU_AlvCnt17Val 3;
BA_ "RoutingFactor" SG_ 384 CLU_AlvCnt17Val 5;
BA_ "Version" SG_ 384 CLU_AlvCnt17Val "18.05.01";
BA_ "Description" SG_ 384 CLU_PddlUpSwSta "This signal represents operating status of Paddle Shifter(Up) Switch.";
BA_ "UserSigValidity" SG_ 384 CLU_PddlUpSwSta 3;
BA_ "RoutingFactor" SG_ 384 CLU_PddlUpSwSta 5;
BA_ "Version" SG_ 384 CLU_PddlUpSwSta "18.08.05";
BA_ "Description" SG_ 384 CLU_PddlDnSwSta "This signal represents operating status of Paddle Shifter(Down) Switch. 
Paddle Shifter(Down) Switch On/Off Information";
BA_ "UserSigValidity" SG_ 384 CLU_PddlDnSwSta 3;
BA_ "RoutingFactor" SG_ 384 CLU_PddlDnSwSta 5;
BA_ "Version" SG_ 384 CLU_PddlDnSwSta "18.08.05";
BA_ "GenMsgSendType" BO_ 256 0;
BA_ "GenMsgCycleTime" BO_ 256 10;
BA_ "GenMsgCycleTimeFast" BO_ 256 0;
BA_ "GenMsgNrOfRepetition" BO_ 256 0;
BA_ "GenMsgDelayTime" BO_ 256 0;
BA_ "VFrameFormat" BO_ 256 14;
BA_ "Description" SG_ 256 ACC_CrsMainSwLmpSta "This signal indicates that an ECU requests cluster to turn on/off auto-cruise control “MAIN” switch indication lamp.

This signal is for the CAN-type cluster installed vehicled only.";
BA_ "UserSigValidity" SG_ 256 ACC_CrsMainSwLmpSta 3;
BA_ "RoutingFactor" SG_ 256 ACC_CrsMainSwLmpSta 5;
BA_ "Version" SG_ 256 ACC_CrsMainSwLmpSta "17.12.00";
BA_ "Description" SG_ 256 ACC_CrsSetSwLmpSta "This signal indicates that an ECU requests cluster to turn on/off auto-cruise control “SET” switch indication lamp.

This signal is for the CAN-type cluster installed vehicled only.";
BA_ "UserSigValidity" SG_ 256 ACC_CrsSetSwLmpSta 3;
BA_ "RoutingFactor" SG_ 256 ACC_CrsSetSwLmpSta 5;
BA_ "Version" SG_ 256 ACC_CrsSetSwLmpSta "17.12.00";
BA_ "Description" SG_ 256 ENG_DpfWrngSta "The signal indicates the status of the 'DPF Warning Level'";
BA_ "UserSigValidity" SG_ 256 ENG_DpfWrngSta 3;
BA_ "RoutingFactor" SG_ 256 ENG_DpfWrngSta 5;
BA_ "Version" SG_ 256 ENG_DpfWrngSta "17.12.00";
BA_ "Description" SG_ 256 ENG_BattWrngLmpSta "The signal indicates the status of the 'Battery Warning Lamp'";
BA_ "UserSigValidity" SG_ 256 ENG_BattWrngLmpSta 3;
BA_ "RoutingFactor" SG_ 256 ENG_BattWrngLmpSta 5;
BA_ "Version" SG_ 256 ENG_BattWrngLmpSta "17.12.00";
BA_ "Description" SG_ 256 ENG_OilPrsrWrngLmpSta "The signal indicates the status of the 'Oil Pressure Warning Lamp'";
BA_ "UserSigValidity" SG_ 256 ENG_OilPrsrWrngLmpSta 3;
BA_ "RoutingFactor" SG_ 256 ENG_OilPrsrWrngLmpSta 5;
BA_ "Version" SG_ 256 ENG_OilPrsrWrngLmpSta "17.12.00";
BA_ "Description" SG_ 256 ENG_EngClntTempVal "Engine coolant temperature in EMS sensed via an A/D converter; converted into degrees centigrade (°C).";
BA_ "GenSigStartValue" SG_ 256 ENG_EngClntTempVal 255;
BA_ "UserSigValidity" SG_ 256 ENG_EngClntTempVal 3;
BA_ "RoutingFactor" SG_ 256 ENG_EngClntTempVal 5;
BA_ "Version" SG_ 256 ENG_EngClntTempVal "17.12.00";
BA_ "Description" SG_ 256 ENG_EngSta "This signal indicates that a status of engine.";
BA_ "UserSigValidity" SG_ 256 ENG_EngSta 3;
BA_ "RoutingFactor" SG_ 256 ENG_EngSta 5;
BA_ "Version" SG_ 256 ENG_EngSta "17.12.00";
BA_ "GenMsgSendType" BO_ 282 0;
BA_ "GenMsgCycleTime" BO_ 282 10;
BA_ "GenMsgCycleTimeFast" BO_ 282 0;
BA_ "GenMsgNrOfRepetition" BO_ 282 0;
BA_ "GenMsgDelayTime" BO_ 282 0;
BA_ "VFrameFormat" BO_ 282 14;
BA_ "Description" SG_ 282 HBA_SysOptSta "HBA System Option Information to Lamp Controller";
BA_ "UserSigValidity" SG_ 282 HBA_SysOptSta 3;
BA_ "RoutingFactor" SG_ 282 HBA_SysOptSta 5;
BA_ "Version" SG_ 282 HBA_SysOptSta "17.12.02";
BA_ "Description" SG_ 282 HBA_SysSta "This signal indicates the status of High Beam Assist system.";
BA_ "UserSigValidity" SG_ 282 HBA_SysSta 3;
BA_ "RoutingFactor" SG_ 282 HBA_SysSta 5;
BA_ "Version" SG_ 282 HBA_SysSta "17.12.02";
BA_ "Description" SG_ 282 HBA_IndLmpReq "HBA System Indicator Lamp Status";
BA_ "UserSigValidity" SG_ 282 HBA_IndLmpReq 3;
BA_ "RoutingFactor" SG_ 282 HBA_IndLmpReq 5;
BA_ "Version" SG_ 282 HBA_IndLmpReq "17.12.02";
BA_ "Description" SG_ 282 DAW_LVDA_PUDis "Message for displaying LVDA(Leading Vehicle Departure Alert) Warning";
BA_ "UserSigValidity" SG_ 282 DAW_LVDA_PUDis 3;
BA_ "RoutingFactor" SG_ 282 DAW_LVDA_PUDis 5;
BA_ "Version" SG_ 282 DAW_LVDA_PUDis "18.07.01";
BA_ "Description" SG_ 282 DAW_LVDA_OptUsmSta "LVDA USM state";
BA_ "UserSigValidity" SG_ 282 DAW_LVDA_OptUsmSta 3;
BA_ "RoutingFactor" SG_ 282 DAW_LVDA_OptUsmSta 5;
BA_ "Version" SG_ 282 DAW_LVDA_OptUsmSta "18.07.01";
BA_ "Description" SG_ 282 DAW_OptUsmSta "This signal represents the lastest DAW ON/OFF value of USM.";
BA_ "UserSigValidity" SG_ 282 DAW_OptUsmSta 3;
BA_ "RoutingFactor" SG_ 282 DAW_OptUsmSta 5;
BA_ "Version" SG_ 282 DAW_OptUsmSta "18.07.01";
BA_ "Description" SG_ 282 DAW_SysSta "This signal represents Attention Assist System Status or Attention Level.";
BA_ "UserSigValidity" SG_ 282 DAW_SysSta 3;
BA_ "RoutingFactor" SG_ 282 DAW_SysSta 5;
BA_ "Version" SG_ 282 DAW_SysSta "18.07.01";
BA_ "Description" SG_ 282 DAW_WrnMsgSta "This signal represents Rest recommend warning message popup state.";
BA_ "UserSigValidity" SG_ 282 DAW_WrnMsgSta 3;
BA_ "RoutingFactor" SG_ 282 DAW_WrnMsgSta 5;
BA_ "Version" SG_ 282 DAW_WrnMsgSta "18.07.01";
BA_ "Description" SG_ 282 DAW_TimeRstReq "This signal requests CLU 'Last Break Time' Reset.
DAW send '0x1' when detecting driver's rest.";
BA_ "UserSigValidity" SG_ 282 DAW_TimeRstReq 3;
BA_ "RoutingFactor" SG_ 282 DAW_TimeRstReq 5;
BA_ "Version" SG_ 282 DAW_TimeRstReq "18.07.01";
BA_ "Description" SG_ 282 DAW_SnstvtyModRetVal "This signal represents the feedback value of the current ADAS warning timing.";
BA_ "UserSigValidity" SG_ 282 DAW_SnstvtyModRetVal 3;
BA_ "RoutingFactor" SG_ 282 DAW_SnstvtyModRetVal 5;
BA_ "Version" SG_ 282 DAW_SnstvtyModRetVal "18.07.01";
BA_ "GenMsgCycleTime" BO_ 2015 0;
BA_ "GenMsgILSupport" BO_ 2015 0;
BA_ "TpMessage" BO_ 2015 1;
BA_ "GenMsgDelayTime" BO_ 2015 0;
BA_ "VFrameFormat" BO_ 2015 14;
BA_ "NmNode" BU_ FD_E 0;
BA_ "UsrSigPurpose" SG_ 2015 GST_ALL_Byte0 2;
BA_ "GenSigSendType" SG_ 2015 GST_ALL_Byte0 2;
BA_ "UserSigValidity" SG_ 2015 GST_ALL_Byte0 0;
BA_ "GenSigTimeoutTime" SG_ 2015 GST_ALL_Byte0 0;
BA_ "NetworkRequest" SG_ 2015 GST_ALL_Byte0 0;
BA_ "NetworkRequestHoldingTime" SG_ 2015 GST_ALL_Byte0 5000;
BA_ "Version" SG_ 2015 GST_ALL_Byte0 "19.02.08";
BA_ "UsrSigPurpose" SG_ 2015 GST_ALL_Byte2 2;
BA_ "GenSigSendType" SG_ 2015 GST_ALL_Byte2 2;
BA_ "UserSigValidity" SG_ 2015 GST_ALL_Byte2 0;
BA_ "GenSigTimeoutTime" SG_ 2015 GST_ALL_Byte2 0;
BA_ "NetworkRequest" SG_ 2015 GST_ALL_Byte2 0;
BA_ "NetworkRequestHoldingTime" SG_ 2015 GST_ALL_Byte2 5000;
BA_ "Version" SG_ 2015 GST_ALL_Byte2 "19.02.08";
BA_ "UsrSigPurpose" SG_ 2015 GST_ALL_Byte3 2;
BA_ "GenSigSendType" SG_ 2015 GST_ALL_Byte3 2;
BA_ "UserSigValidity" SG_ 2015 GST_ALL_Byte3 0;
BA_ "GenSigTimeoutTime" SG_ 2015 GST_ALL_Byte3 0;
BA_ "NetworkRequest" SG_ 2015 GST_ALL_Byte3 0;
BA_ "NetworkRequestHoldingTime" SG_ 2015 GST_ALL_Byte3 5000;
BA_ "Version" SG_ 2015 GST_ALL_Byte3 "19.02.08";
BA_ "UsrSigPurpose" SG_ 2015 GST_ALL_Byte4 2;
BA_ "GenSigSendType" SG_ 2015 GST_ALL_Byte4 2;
BA_ "UserSigValidity" SG_ 2015 GST_ALL_Byte4 0;
BA_ "GenSigTimeoutTime" SG_ 2015 GST_ALL_Byte4 0;
BA_ "NetworkRequest" SG_ 2015 GST_ALL_Byte4 0;
BA_ "NetworkRequestHoldingTime" SG_ 2015 GST_ALL_Byte4 5000;
BA_ "Version" SG_ 2015 GST_ALL_Byte4 "19.02.08";
BA_ "UsrSigPurpose" SG_ 2015 GST_ALL_Byte5 2;
BA_ "GenSigSendType" SG_ 2015 GST_ALL_Byte5 2;
BA_ "UserSigValidity" SG_ 2015 GST_ALL_Byte5 0;
BA_ "GenSigTimeoutTime" SG_ 2015 GST_ALL_Byte5 0;
BA_ "NetworkRequest" SG_ 2015 GST_ALL_Byte5 0;
BA_ "NetworkRequestHoldingTime" SG_ 2015 GST_ALL_Byte5 5000;
BA_ "Version" SG_ 2015 GST_ALL_Byte5 "19.02.08";
BA_ "UsrSigPurpose" SG_ 2015 GST_ALL_Byte6 2;
BA_ "GenSigSendType" SG_ 2015 GST_ALL_Byte6 2;
BA_ "UserSigValidity" SG_ 2015 GST_ALL_Byte6 0;
BA_ "GenSigTimeoutTime" SG_ 2015 GST_ALL_Byte6 0;
BA_ "NetworkRequest" SG_ 2015 GST_ALL_Byte6 0;
BA_ "NetworkRequestHoldingTime" SG_ 2015 GST_ALL_Byte6 5000;
BA_ "Version" SG_ 2015 GST_ALL_Byte6 "19.02.08";
BA_ "UsrSigPurpose" SG_ 2015 GST_ALL_Byte7 2;
BA_ "GenSigSendType" SG_ 2015 GST_ALL_Byte7 2;
BA_ "UserSigValidity" SG_ 2015 GST_ALL_Byte7 0;
BA_ "GenSigTimeoutTime" SG_ 2015 GST_ALL_Byte7 0;
BA_ "NetworkRequest" SG_ 2015 GST_ALL_Byte7 0;
BA_ "NetworkRequestHoldingTime" SG_ 2015 GST_ALL_Byte7 5000;
BA_ "Version" SG_ 2015 GST_ALL_Byte7 "19.02.08";
BA_ "UsrSigPurpose" SG_ 2015 GST_ALL_Byte1 2;
BA_ "GenSigSendType" SG_ 2015 GST_ALL_Byte1 2;
BA_ "UserSigValidity" SG_ 2015 GST_ALL_Byte1 0;
BA_ "GenSigTimeoutTime" SG_ 2015 GST_ALL_Byte1 0;
BA_ "NetworkRequest" SG_ 2015 GST_ALL_Byte1 0;
BA_ "NetworkRequestHoldingTime" SG_ 2015 GST_ALL_Byte1 5000;
BA_ "Version" SG_ 2015 GST_ALL_Byte1 "19.02.08";
BA_ "GenMsgCycleTime" BO_ 1990 0;
BA_ "GenMsgILSupport" BO_ 1990 0;
BA_ "TpMessage" BO_ 1990 1;
BA_ "GenMsgDelayTime" BO_ 1990 0;
BA_ "VFrameFormat" BO_ 1990 14;
BA_ "UsrSigPurpose" SG_ 1990 GST_CLU_Byte0 2;
BA_ "GenSigSendType" SG_ 1990 GST_CLU_Byte0 2;
BA_ "UserSigValidity" SG_ 1990 GST_CLU_Byte0 0;
BA_ "GenSigTimeoutTime" SG_ 1990 GST_CLU_Byte0 0;
BA_ "NetworkRequest" SG_ 1990 GST_CLU_Byte0 0;
BA_ "NetworkRequestHoldingTime" SG_ 1990 GST_CLU_Byte0 5000;
BA_ "Version" SG_ 1990 GST_CLU_Byte0 "18.01.08";
BA_ "UsrSigPurpose" SG_ 1990 GST_CLU_Byte2 2;
BA_ "GenSigSendType" SG_ 1990 GST_CLU_Byte2 2;
BA_ "UserSigValidity" SG_ 1990 GST_CLU_Byte2 0;
BA_ "GenSigTimeoutTime" SG_ 1990 GST_CLU_Byte2 0;
BA_ "NetworkRequest" SG_ 1990 GST_CLU_Byte2 0;
BA_ "NetworkRequestHoldingTime" SG_ 1990 GST_CLU_Byte2 5000;
BA_ "Version" SG_ 1990 GST_CLU_Byte2 "18.01.08";
BA_ "UsrSigPurpose" SG_ 1990 GST_CLU_Byte3 2;
BA_ "GenSigSendType" SG_ 1990 GST_CLU_Byte3 2;
BA_ "UserSigValidity" SG_ 1990 GST_CLU_Byte3 0;
BA_ "GenSigTimeoutTime" SG_ 1990 GST_CLU_Byte3 0;
BA_ "NetworkRequest" SG_ 1990 GST_CLU_Byte3 0;
BA_ "NetworkRequestHoldingTime" SG_ 1990 GST_CLU_Byte3 5000;
BA_ "Version" SG_ 1990 GST_CLU_Byte3 "18.01.08";
BA_ "UsrSigPurpose" SG_ 1990 GST_CLU_Byte4 2;
BA_ "GenSigSendType" SG_ 1990 GST_CLU_Byte4 2;
BA_ "UserSigValidity" SG_ 1990 GST_CLU_Byte4 0;
BA_ "GenSigTimeoutTime" SG_ 1990 GST_CLU_Byte4 0;
BA_ "NetworkRequest" SG_ 1990 GST_CLU_Byte4 0;
BA_ "NetworkRequestHoldingTime" SG_ 1990 GST_CLU_Byte4 5000;
BA_ "Version" SG_ 1990 GST_CLU_Byte4 "18.01.08";
BA_ "UsrSigPurpose" SG_ 1990 GST_CLU_Byte5 2;
BA_ "GenSigSendType" SG_ 1990 GST_CLU_Byte5 2;
BA_ "UserSigValidity" SG_ 1990 GST_CLU_Byte5 0;
BA_ "GenSigTimeoutTime" SG_ 1990 GST_CLU_Byte5 0;
BA_ "NetworkRequest" SG_ 1990 GST_CLU_Byte5 0;
BA_ "NetworkRequestHoldingTime" SG_ 1990 GST_CLU_Byte5 5000;
BA_ "Version" SG_ 1990 GST_CLU_Byte5 "18.01.08";
BA_ "UsrSigPurpose" SG_ 1990 GST_CLU_Byte6 2;
BA_ "GenSigSendType" SG_ 1990 GST_CLU_Byte6 2;
BA_ "UserSigValidity" SG_ 1990 GST_CLU_Byte6 0;
BA_ "GenSigTimeoutTime" SG_ 1990 GST_CLU_Byte6 0;
BA_ "NetworkRequest" SG_ 1990 GST_CLU_Byte6 0;
BA_ "NetworkRequestHoldingTime" SG_ 1990 GST_CLU_Byte6 5000;
BA_ "Version" SG_ 1990 GST_CLU_Byte6 "18.01.08";
BA_ "UsrSigPurpose" SG_ 1990 GST_CLU_Byte7 2;
BA_ "GenSigSendType" SG_ 1990 GST_CLU_Byte7 2;
BA_ "UserSigValidity" SG_ 1990 GST_CLU_Byte7 0;
BA_ "GenSigTimeoutTime" SG_ 1990 GST_CLU_Byte7 0;
BA_ "NetworkRequest" SG_ 1990 GST_CLU_Byte7 0;
BA_ "NetworkRequestHoldingTime" SG_ 1990 GST_CLU_Byte7 5000;
BA_ "Version" SG_ 1990 GST_CLU_Byte7 "18.01.08";
BA_ "UsrSigPurpose" SG_ 1990 GST_CLU_Byte1 2;
BA_ "GenSigSendType" SG_ 1990 GST_CLU_Byte1 2;
BA_ "UserSigValidity" SG_ 1990 GST_CLU_Byte1 0;
BA_ "GenSigTimeoutTime" SG_ 1990 GST_CLU_Byte1 0;
BA_ "NetworkRequest" SG_ 1990 GST_CLU_Byte1 0;
BA_ "NetworkRequestHoldingTime" SG_ 1990 GST_CLU_Byte1 5000;
BA_ "Version" SG_ 1990 GST_CLU_Byte1 "18.01.08";
BA_ "GenMsgSendType" BO_ 934 0;
BA_ "VFrameFormat" BO_ 934 14;
BA_ "Description" SG_ 934 PTGM_UsmSetSta "PTGM USM Setting Signal";
BA_ "GenSigSendType" SG_ 934 PTGM_UsmSetSta 4;
BA_ "UserSigValidity" SG_ 934 PTGM_UsmSetSta 3;
BA_ "GenSigTimeoutTime" SG_ 934 PTGM_UsmSetSta 1500;
BA_ "NetworkRequest" SG_ 934 PTGM_UsmSetSta 0;
BA_ "NetworkRequestHoldingTime" SG_ 934 PTGM_UsmSetSta 5000;
BA_ "Version" SG_ 934 PTGM_UsmSetSta "17.11.00";
BA_ "Description" SG_ 934 PTGM_HeightSetWarn "PTG Height USM Setting Warning Pop-up message";
BA_ "GenSigSendType" SG_ 934 PTGM_HeightSetWarn 4;
BA_ "UserSigValidity" SG_ 934 PTGM_HeightSetWarn 0;
BA_ "GenSigTimeoutTime" SG_ 934 PTGM_HeightSetWarn 1500;
BA_ "Version" SG_ 934 PTGM_HeightSetWarn "18.12.02";
BA_ "GenMsgCycleTime" BO_ 1252 0;
BA_ "GenMsgDelayTime" BO_ 1252 0;
BA_ "VFrameFormat" BO_ 1252 14;
BA_ "Description" SG_ 1252 RKE_BtnReq "Remote Key Button Request from Folding Key or Smart Key";
BA_ "GenSigSendType" SG_ 1252 RKE_BtnReq 4;
BA_ "UserSigValidity" SG_ 1252 RKE_BtnReq 0;
BA_ "GenSigTimeoutTime" SG_ 1252 RKE_BtnReq 0;
BA_ "NetworkRequest" SG_ 1252 RKE_BtnReq 0;
BA_ "NetworkRequestHoldingTime" SG_ 1252 RKE_BtnReq 5000;
BA_ "Version" SG_ 1252 RKE_BtnReq "18.06.01";
BA_ "GenMsgSendType" BO_ 442 0;
BA_ "GenMsgCycleTime" BO_ 442 50;
BA_ "GenMsgCycleTimeFast" BO_ 442 0;
BA_ "GenMsgNrOfRepetition" BO_ 442 0;
BA_ "VFrameFormat" BO_ 442 14;
BA_ "Description" SG_ 442 BCW_Sta "This signal indicates the status of BCW";
BA_ "UserSigValidity" SG_ 442 BCW_Sta 3;
BA_ "RoutingFactor" SG_ 442 BCW_Sta 3;
BA_ "Version" SG_ 442 BCW_Sta "18.12.01";
BA_ "Description" SG_ 442 BCW_LftIndSta "This signal Indicates BCW Warning Indicator mode for Left side";
BA_ "UserSigValidity" SG_ 442 BCW_LftIndSta 3;
BA_ "RoutingFactor" SG_ 442 BCW_LftIndSta 3;
BA_ "Version" SG_ 442 BCW_LftIndSta "18.12.01";
BA_ "Description" SG_ 442 BCW_RtIndSta "This signal Indicates BCW Warning Indicator mode for Right side";
BA_ "UserSigValidity" SG_ 442 BCW_RtIndSta 3;
BA_ "RoutingFactor" SG_ 442 BCW_RtIndSta 3;
BA_ "Version" SG_ 442 BCW_RtIndSta "18.12.01";
BA_ "Description" SG_ 442 BCW_LftSndWrngSta "This signal indicates BCW Sound Warning for Front Left Speaker";
BA_ "UserSigValidity" SG_ 442 BCW_LftSndWrngSta 3;
BA_ "RoutingFactor" SG_ 442 BCW_LftSndWrngSta 3;
BA_ "Version" SG_ 442 BCW_LftSndWrngSta "18.12.01";
BA_ "Description" SG_ 442 BCW_RtSndWrngSta "This signal indicates BCW Sound Warning for Front Right Speaker";
BA_ "UserSigValidity" SG_ 442 BCW_RtSndWrngSta 3;
BA_ "RoutingFactor" SG_ 442 BCW_RtSndWrngSta 3;
BA_ "Version" SG_ 442 BCW_RtSndWrngSta "18.12.01";
BA_ "Description" SG_ 442 BCW_LftIndBriLvlVal "0x00~FF : Indicator Brightness level of BCW";
BA_ "UserSigValidity" SG_ 442 BCW_LftIndBriLvlVal 3;
BA_ "RoutingFactor" SG_ 442 BCW_LftIndBriLvlVal 3;
BA_ "Version" SG_ 442 BCW_LftIndBriLvlVal "18.12.01";
BA_ "Description" SG_ 442 BCW_RtIndBriLvlVal "0x00~FF : Indicator Brightness level of BCW";
BA_ "UserSigValidity" SG_ 442 BCW_RtIndBriLvlVal 3;
BA_ "RoutingFactor" SG_ 442 BCW_RtIndBriLvlVal 3;
BA_ "Version" SG_ 442 BCW_RtIndBriLvlVal "18.12.01";
BA_ "Description" SG_ 442 BCW_SnstvtyModRetVal "This signal indicates the selected sensitive mode of BCW warning";
BA_ "UserSigValidity" SG_ 442 BCW_SnstvtyModRetVal 3;
BA_ "RoutingFactor" SG_ 442 BCW_SnstvtyModRetVal 3;
BA_ "Version" SG_ 442 BCW_SnstvtyModRetVal "18.12.01";
BA_ "Description" SG_ 442 BCW_IndSta "OS Mirror Indicator Failure";
BA_ "UserSigValidity" SG_ 442 BCW_IndSta 3;
BA_ "RoutingFactor" SG_ 442 BCW_IndSta 3;
BA_ "Version" SG_ 442 BCW_IndSta "18.12.01";
BA_ "Description" SG_ 442 BCA_Sta "This signal indicates the status of BCA";
BA_ "UserSigValidity" SG_ 442 BCA_Sta 3;
BA_ "RoutingFactor" SG_ 442 BCA_Sta 3;
BA_ "Version" SG_ 442 BCA_Sta "18.12.01";
BA_ "Description" SG_ 442 BCA_OnOffEquipSta "This signal indicates the on/off status of BCA";
BA_ "UserSigValidity" SG_ 442 BCA_OnOffEquipSta 3;
BA_ "RoutingFactor" SG_ 442 BCA_OnOffEquipSta 3;
BA_ "Version" SG_ 442 BCA_OnOffEquipSta "18.12.01";
BA_ "Description" SG_ 442 BCA_LftWrngSta "This signal indicates the left warning of BCA";
BA_ "UserSigValidity" SG_ 442 BCA_LftWrngSta 3;
BA_ "RoutingFactor" SG_ 442 BCA_LftWrngSta 3;
BA_ "Version" SG_ 442 BCA_LftWrngSta "18.12.01";
BA_ "Description" SG_ 442 BCA_RtWrngSta "This signal indicates the Right warning of BCA";
BA_ "UserSigValidity" SG_ 442 BCA_RtWrngSta 3;
BA_ "RoutingFactor" SG_ 442 BCA_RtWrngSta 3;
BA_ "Version" SG_ 442 BCA_RtWrngSta "18.12.01";
BA_ "Description" SG_ 442 BCA_R_Brake_Warning "This signal indicate the warning status for BCA-R with Differential Brake";
BA_ "UserSigValidity" SG_ 442 BCA_R_Brake_Warning 3;
BA_ "RoutingFactor" SG_ 442 BCA_R_Brake_Warning 3;
BA_ "Version" SG_ 442 BCA_R_Brake_Warning "18.12.01";
BA_ "Description" SG_ 442 BCA_Plus_LftWrngSta "This signal Indicates BCA_Plus Warning state for HMI(Cluster)";
BA_ "UserSigValidity" SG_ 442 BCA_Plus_LftWrngSta 3;
BA_ "RoutingFactor" SG_ 442 BCA_Plus_LftWrngSta 3;
BA_ "Version" SG_ 442 BCA_Plus_LftWrngSta "18.12.06";
BA_ "Description" SG_ 442 BCA_Plus_RtWrngSta "This signal Indicates BCA_Plus Warning state for HMI";
BA_ "UserSigValidity" SG_ 442 BCA_Plus_RtWrngSta 3;
BA_ "RoutingFactor" SG_ 442 BCA_Plus_RtWrngSta 3;
BA_ "Version" SG_ 442 BCA_Plus_RtWrngSta "18.12.06";
BA_ "Description" SG_ 442 BCA_Plus_Sta "This signal indicates the status of BCA Plus";
BA_ "UserSigValidity" SG_ 442 BCA_Plus_Sta 3;
BA_ "RoutingFactor" SG_ 442 BCA_Plus_Sta 3;
BA_ "Version" SG_ 442 BCA_Plus_Sta "18.12.01";
BA_ "GenMsgSendType" BO_ 304 0;
BA_ "GenMsgCycleTime" BO_ 304 10;
BA_ "GenMsgCycleTimeFast" BO_ 304 0;
BA_ "GenMsgNrOfRepetition" BO_ 304 0;
BA_ "GenMsgDelayTime" BO_ 304 0;
BA_ "VFrameFormat" BO_ 304 14;
BA_ "Description" SG_ 304 SBW_SHFTR_FF_LvrWrngMsg "This signal displays in the cluster.

This signal is classified by the lever type of Shift By Wire.

0x00~0x07 : Button Type
0x0D~0x15 : Lever Type(or Dial Type)";
BA_ "UserSigValidity" SG_ 304 SBW_SHFTR_FF_LvrWrngMsg 0;
BA_ "RoutingFactor" SG_ 304 SBW_SHFTR_FF_LvrWrngMsg 5;
BA_ "Version" SG_ 304 SBW_SHFTR_FF_LvrWrngMsg "18.08.04";
BA_ "GenMsgSendType" BO_ 933 0;
BA_ "GenMsgCycleTime" BO_ 933 100;
BA_ "GenMsgCycleTimeFast" BO_ 933 0;
BA_ "GenMsgNrOfRepetition" BO_ 933 0;
BA_ "VFrameFormat" BO_ 933 14;
BA_ "Description" SG_ 933 SCU_FF_WrnMsgClu "This signal indicates the status of “SCU Warning message”";
BA_ "UserSigValidity" SG_ 933 SCU_FF_WrnMsgClu 3;
BA_ "GenSigTimeoutTime" SG_ 933 SCU_FF_WrnMsgClu 1500;
BA_ "RoutingFactor" SG_ 933 SCU_FF_WrnMsgClu 2;
BA_ "Version" SG_ 933 SCU_FF_WrnMsgClu "18.08.07";
BA_ "Description" SG_ 933 SCU_FF_NPosWshModSta "This signal indicates N wash Mode status.";
BA_ "UserSigValidity" SG_ 933 SCU_FF_NPosWshModSta 3;
BA_ "GenSigTimeoutTime" SG_ 933 SCU_FF_NPosWshModSta 1500;
BA_ "RoutingFactor" SG_ 933 SCU_FF_NPosWshModSta 2;
BA_ "Version" SG_ 933 SCU_FF_NPosWshModSta "18.08.07";
BA_ "GenMsgCycleTime" BO_ 1253 0;
BA_ "GenMsgDelayTime" BO_ 1253 0;
BA_ "VFrameFormat" BO_ 1253 14;
BA_ "GenSigSendType" SG_ 1253 DoorLock_PsvDrLkReq 4;
BA_ "UserSigValidity" SG_ 1253 DoorLock_PsvDrLkReq 0;
BA_ "GenSigTimeoutTime" SG_ 1253 DoorLock_PsvDrLkReq 0;
BA_ "Version" SG_ 1253 DoorLock_PsvDrLkReq "17.12.00";
BA_ "GenSigSendType" SG_ 1253 DoorLock_PsvDrUnLkReq 4;
BA_ "UserSigValidity" SG_ 1253 DoorLock_PsvDrUnLkReq 0;
BA_ "GenSigTimeoutTime" SG_ 1253 DoorLock_PsvDrUnLkReq 0;
BA_ "Version" SG_ 1253 DoorLock_PsvDrUnLkReq "17.12.00";
BA_ "GenMsgSendType" BO_ 1092 0;
BA_ "VFrameFormat" BO_ 1092 14;
BA_ "GenSigSendType" SG_ 1092 SMK_AuthSta 4;
BA_ "UserSigValidity" SG_ 1092 SMK_AuthSta 0;
BA_ "GenSigTimeoutTime" SG_ 1092 SMK_AuthSta 1500;
BA_ "Version" SG_ 1092 SMK_AuthSta "17.12.00";
BA_ "Description" SG_ 1092 SMK_CLUAccIndOnReq "Request to Cluster ACC Indicator On
(This is only used for CLU)";
BA_ "GenSigSendType" SG_ 1092 SMK_CLUAccIndOnReq 4;
BA_ "UserSigValidity" SG_ 1092 SMK_CLUAccIndOnReq 0;
BA_ "GenSigTimeoutTime" SG_ 1092 SMK_CLUAccIndOnReq 1500;
BA_ "Version" SG_ 1092 SMK_CLUAccIndOnReq "17.12.00";
BA_ "GenMsgSendType" BO_ 928 0;
BA_ "GenMsgCycleTimeFast" BO_ 928 0;
BA_ "GenMsgNrOfRepetition" BO_ 928 0;
BA_ "VFrameFormat" BO_ 928 14;
BA_ "Description" SG_ 928 TPMS_FLPosWrngLmpSta "The signal indicates the status of the “FL POSITION Warning lamp”";
BA_ "UserSigValidity" SG_ 928 TPMS_FLPosWrngLmpSta 3;
BA_ "GenSigTimeoutTime" SG_ 928 TPMS_FLPosWrngLmpSta 1500;
BA_ "Version" SG_ 928 TPMS_FLPosWrngLmpSta "17.12.00";
BA_ "Description" SG_ 928 TPMS_FRPosWrngLmpSta "The signal indicates the status of the “FR POSITION Warning lamp”";
BA_ "UserSigValidity" SG_ 928 TPMS_FRPosWrngLmpSta 3;
BA_ "GenSigTimeoutTime" SG_ 928 TPMS_FRPosWrngLmpSta 1500;
BA_ "Version" SG_ 928 TPMS_FRPosWrngLmpSta "17.12.00";
BA_ "Description" SG_ 928 TPMS_RLPosWrngLmpSta "The signal indicates the status of the “RL POSITION Warning lamp”";
BA_ "UserSigValidity" SG_ 928 TPMS_RLPosWrngLmpSta 3;
BA_ "GenSigTimeoutTime" SG_ 928 TPMS_RLPosWrngLmpSta 1500;
BA_ "Version" SG_ 928 TPMS_RLPosWrngLmpSta "17.12.00";
BA_ "Description" SG_ 928 TPMS_RRPosWrngLmpSta "The signal indicates the status of the “RR POSITION Warning lamp”";
BA_ "UserSigValidity" SG_ 928 TPMS_RRPosWrngLmpSta 3;
BA_ "GenSigTimeoutTime" SG_ 928 TPMS_RRPosWrngLmpSta 1500;
BA_ "Version" SG_ 928 TPMS_RRPosWrngLmpSta "17.12.00";
BA_ "Description" SG_ 928 TPMS_FLTirePrsrVal "The signal indicates the “FL tire pressure”.";
BA_ "UserSigValidity" SG_ 928 TPMS_FLTirePrsrVal 3;
BA_ "GenSigTimeoutTime" SG_ 928 TPMS_FLTirePrsrVal 1500;
BA_ "Version" SG_ 928 TPMS_FLTirePrsrVal "17.12.00";
BA_ "Description" SG_ 928 TPMS_FRTirePrsrVal "The signal indicates the “FR tire pressure”.";
BA_ "UserSigValidity" SG_ 928 TPMS_FRTirePrsrVal 3;
BA_ "GenSigTimeoutTime" SG_ 928 TPMS_FRTirePrsrVal 1500;
BA_ "Version" SG_ 928 TPMS_FRTirePrsrVal "17.12.00";
BA_ "Description" SG_ 928 TPMS_RLTirePrsrVal "The signal indicates the “RL tire pressure”.";
BA_ "UserSigValidity" SG_ 928 TPMS_RLTirePrsrVal 3;
BA_ "GenSigTimeoutTime" SG_ 928 TPMS_RLTirePrsrVal 1500;
BA_ "Version" SG_ 928 TPMS_RLTirePrsrVal "17.12.00";
BA_ "Description" SG_ 928 TPMS_RRTirePrsrVal "The signal indicates the “RR tire pressure”.";
BA_ "UserSigValidity" SG_ 928 TPMS_RRTirePrsrVal 3;
BA_ "GenSigTimeoutTime" SG_ 928 TPMS_RRTirePrsrVal 1500;
BA_ "Version" SG_ 928 TPMS_RRTirePrsrVal "17.12.00";
BA_ "Description" SG_ 928 TPMS_SnsrSta "The signal indicates the status of the TPMS";
BA_ "UserSigValidity" SG_ 928 TPMS_SnsrSta 3;
BA_ "GenSigTimeoutTime" SG_ 928 TPMS_SnsrSta 1500;
BA_ "Version" SG_ 928 TPMS_SnsrSta "17.12.00";
BA_ "Description" SG_ 928 TPMS_WrngLmpSta "The signal indicates the status of the “TPMS Malfunction Warning lamp”";
BA_ "UserSigValidity" SG_ 928 TPMS_WrngLmpSta 3;
BA_ "GenSigTimeoutTime" SG_ 928 TPMS_WrngLmpSta 1500;
BA_ "Version" SG_ 928 TPMS_WrngLmpSta "17.12.00";
BA_ "Description" SG_ 928 TPMS_TreadWrngLmpSta "The signal indicates the status of the “TREAD Warning lamp”";
BA_ "UserSigValidity" SG_ 928 TPMS_TreadWrngLmpSta 3;
BA_ "GenSigTimeoutTime" SG_ 928 TPMS_TreadWrngLmpSta 1500;
BA_ "Version" SG_ 928 TPMS_TreadWrngLmpSta "17.12.00";
BA_ "Description" SG_ 928 TPMS_PrsrUnitSta "The signal indicates the unit of pressure for display on cluster.";
BA_ "UserSigValidity" SG_ 928 TPMS_PrsrUnitSta 3;
BA_ "GenSigTimeoutTime" SG_ 928 TPMS_PrsrUnitSta 1500;
BA_ "Version" SG_ 928 TPMS_PrsrUnitSta "17.12.00";
BA_ "GenMsgSendType" BO_ 160 0;
BA_ "GenMsgCycleTime" BO_ 160 10;
BA_ "GenMsgCycleTimeFast" BO_ 160 0;
BA_ "GenMsgNrOfRepetition" BO_ 160 0;
BA_ "GenMsgDelayTime" BO_ 160 0;
BA_ "VFrameFormat" BO_ 160 14;
BA_ "Description" SG_ 160 WHL_SpdRRVal "This signal provides the wheel velocity of each wheel and have 14 bits length and a resolution of 0.03125 km^h.(This resolution is higher than that of signal in TCS5).
In case of failure of one wheel speed sensor, the value 3FFFH is used as error identifier.";
BA_ "UserSigValidity" SG_ 160 WHL_SpdRRVal 3;
BA_ "RoutingFactor" SG_ 160 WHL_SpdRRVal 5;
BA_ "Version" SG_ 160 WHL_SpdRRVal "17.12.00";
BA_ "Description" SG_ 160 WHL_SpdFLVal "This signal provides the wheel velocity of each wheel and have 14 bits length and a resolution of 0.03125 km^h.(This resolution is higher than that of signal in TCS5).
In case of failure of one wheel speed sensor, the value 3FFFH is used as error identifier.";
BA_ "UserSigValidity" SG_ 160 WHL_SpdFLVal 3;
BA_ "RoutingFactor" SG_ 160 WHL_SpdFLVal 5;
BA_ "Version" SG_ 160 WHL_SpdFLVal "17.12.00";
BA_ "Description" SG_ 160 WHL_SpdFRVal "This signal provides the wheel velocity of each wheel and have 14 bits length and a resolution of 0.03125 km^h.(This resolution is higher than that of signal in TCS5).
In case of failure of one wheel speed sensor, the value 3FFFH is used as error identifier.";
BA_ "UserSigValidity" SG_ 160 WHL_SpdFRVal 3;
BA_ "RoutingFactor" SG_ 160 WHL_SpdFRVal 5;
BA_ "Version" SG_ 160 WHL_SpdFRVal "17.12.00";
BA_ "Description" SG_ 160 WHL_SpdRLVal "This signal provides the wheel velocity of each wheel and have 14 bits length and a resolution of 0.03125 km^h.(This resolution is higher than that of signal in TCS5).
In case of failure of one wheel speed sensor, the value 3FFFH is used as error identifier.";
BA_ "UserSigValidity" SG_ 160 WHL_SpdRLVal 3;
BA_ "RoutingFactor" SG_ 160 WHL_SpdRLVal 5;
BA_ "Version" SG_ 160 WHL_SpdRLVal "17.12.00";
BA_ "GenMsgSendType" BO_ 1099 0;
BA_ "VFrameFormat" BO_ 1099 14;
BA_ "Description" SG_ 1099 USM_CmdWPCSta "USM request value of WPC";
BA_ "GenSigSendType" SG_ 1099 USM_CmdWPCSta 4;
BA_ "UserSigValidity" SG_ 1099 USM_CmdWPCSta 0;
BA_ "GenSigTimeoutTime" SG_ 1099 USM_CmdWPCSta 1500;
BA_ "NetworkRequest" SG_ 1099 USM_CmdWPCSta 0;
BA_ "NetworkRequestHoldingTime" SG_ 1099 USM_CmdWPCSta 5000;
BA_ "Version" SG_ 1099 USM_CmdWPCSta "17.11.00";
BA_ "Description" SG_ 1099 WPC_PhnLftWrngSta "Warning by WPC for User (Phone left in vehicle)";
BA_ "GenSigSendType" SG_ 1099 WPC_PhnLftWrngSta 4;
BA_ "UserSigValidity" SG_ 1099 WPC_PhnLftWrngSta 0;
BA_ "GenSigTimeoutTime" SG_ 1099 WPC_PhnLftWrngSta 1500;
BA_ "NetworkRequest" SG_ 1099 WPC_PhnLftWrngSta 0;
BA_ "NetworkRequestHoldingTime" SG_ 1099 WPC_PhnLftWrngSta 5000;
BA_ "Version" SG_ 1099 WPC_PhnLftWrngSta "18.02.03";
VAL_ 522 ACU_SysWrngLmpDis 0 "Warning Lamp off" 1 "Warning Lamp on" 2 "Warning Lamp flash" 3 "Reserved" 4 "Reserved" 5 "Reserved" 6 "Not used" 7 "Error Indicator" ;
VAL_ 416 SCC_NSCCOpSta 0 "Off" 1 "Ready" 2 "Act" 3 "Error Indicator" ;
VAL_ 416 SCC_NSCCOnOffSta 0 "Default" 1 "Off" 2 "On" 3 "Invalid" ;
VAL_ 416 SCC_ObjSta 0 "No in-path object detected" 1 "In-path object detected (uncontrollable)" 2 "In-path object detected (controllable" 3 "Reserved" 4 "Reserved" 5 "Reserved" 6 "Reserved" 7 "Reserved" ;
VAL_ 416 SCC_SnstvtyModRetVal 0 "Default" 1 "Comford Mode" 2 "Normal Mode" 3 "Dynamic Mode" 4 "Reserved" 5 "Reserved" 6 "Reserved" 7 "Invalid" ;
VAL_ 416 SCC_NSCCAutoSetSpdUpdtSta 0 "Auto Set Speed Update Off" 1 "Auto Set Speed Update On" 2 "Reserved" 3 "Error Indicator" ;
VAL_ 416 SCC_NSCCInfoPUDis 0 "None" 1 "NSCC Warning" 2 "Reserved" 3 "Reserved" 4 "Reserved" 5 "Reserved" 6 "Reserved" 7 "Reserved" ;
VAL_ 416 SCC_TrgtDstVal 1501 "0x0x5DD~0x7FF:Reserved" 2047 "0x0x5DD~0x7FF:Reserved" 2046 "Default" 2047 "Error" ;
VAL_ 416 SCC_ObjDstVal 1501 "0x0x5DD~0x7FF:Reserved" 2047 "0x0x5DD~0x7FF:Reserved" 2046 "Default" 2047 "Error" ;
VAL_ 416 SCC_ObjLatPosVal 510 "Default" 511 "Error" ;
VAL_ 416 SCC_SysFlrSta 0 "System without error" 1 "Performance degredation" 2 "System temporairy unavailable" 3 "SCC Service Required" ;
VAL_ 416 SCC_MainOnOffSta 0 "OFF" 1 "ON" 2 "Not used" 3 "Error Indicator" ;
VAL_ 416 SCC_OpSta 0 "Off" 1 "Engaged" 2 "Override" 3 "Shutoff" 4 "Canceled or Paused" 5 "Reserved" 6 "Reserved" 7 "Reserved" ;
VAL_ 416 SCC_TakeoverReq 0 "No takeover request" 1 "Takeover request" 2 "Not used" 3 "Error Indicator" ;
VAL_ 416 SCC_InfoDis 0 "-" 1 "Display “SCC Mode”" 2 "Display “Conventional Cruise Mode”" 3 "Display “Object disappeared at low speed”" 4 "Display “Available to resume acceleration control”" 5 "Reserved" 6 "Reserved" 7 "Invalid" ;
VAL_ 416 SCC_DrvAlrtDis 0 "-" 1 "Display 'SCC Disengaged'" 2 "Display 'No SCC Engage Condition!'" 3 "Display 'SCC Disengaged When The Vehicle Stops'" ;
VAL_ 416 SCC_ObjDstLvlVal 0 "No in-path object detected" 1 "Distance Warning" 2 "1st Object Distance Level" 3 "2nd Object Distance Level" 4 "3rd Object Distance Level" 5 "4th Object Distance Level" 6 "0x6~0xFE:Reserved" 254 "0x6~0xFE:Reserved" 255 "Error Indicator" ;
VAL_ 416 SCC_HeadwayDstSetVal 0 "No time gap set" 1 "1st level distance" 2 "2nd level distance" 3 "3rd level distance" 4 "4th level distance" 5 "Reserved" 6 "Reserved" 7 "Reserved" 8 "Reserved" 9 "Reserved" 10 "Reserved" 11 "Reserved" 12 "Reserved" 13 "Reserved" 14 "SCC-ML Active" 15 "Error Indicator" ;
VAL_ 416 SCC_NSCCAutoSetSpdSta 0 "Auto Set Speed Off" 1 "Auto Set Speed On" 2 "Reserved" 3 "Error Indicator" ;
VAL_ 416 SCC_TrgtSpdSetVal 255 "Error" ;
VAL_ 1090 BCM_SmkOptTyp 0 "Non SMK Option" 1 "SMK Option" 2 "Not Used" 3 "Error Indicator" ;
VAL_ 1090 Window_DrvrSdWdwSta_BCM 0 "Window Close" 1 "Window Open" 2 "Not Used" 3 "Error Indicator" ;
VAL_ 1090 Window_AsstSdWdwSta_BCM 0 "Window Close" 1 "Window Open" 2 "Not Used" 3 "Error Indicator" ;
VAL_ 1090 Window_RrLftWdwSta_BCM 0 "Window Close" 1 "Window Open" 2 "Not Used" 3 "Error Indicator" ;
VAL_ 1090 Window_RrRtWdwSta_BCM 0 "Window Close" 1 "Window Open" 2 "Not Used" 3 "Error Indicator" ;
VAL_ 1090 Mirror_OSMirFldDis_BCM 0 "Off(Unfold)" 1 "On(Fold)" 2 "Not Used" 3 "Error Indicator" ;
VAL_ 426 CLU_SpdUnitTyp 0 "km/h" 1 "MPH" 2 "Not used" 3 "Error Indicator" ;
VAL_ 426 CLU_DisSpdDcmlVal 0 "0" 1 "0.125" 2 "0.250" 3 "0.375" ;
VAL_ 426 CLU_SWRCCrsMainSwSta 0 "Off" 1 "Key On" 2 "Reserved" 3 "Invalid" ;
VAL_ 426 CLU_SWRCCrsSwSta 0 "Idle Position" 1 "Plus" 2 "Minus" 3 "Headway" 4 "Cancel/Pause" 5 "Reserved" 6 "Reserved" 7 "Reserved" ;
VAL_ 426 CLU_SWRCLFASwSta 0 "Off" 1 "Key On" 2 "Reserved" 3 "Invalid" ;
VAL_ 426 CLU_SWRCSldMainSwSta 0 "Off" 1 "Key On" 2 "Reserved" 3 "Invalid" ;
VAL_ 426 CLU_RhstaLvlSta 0 "Reserved" 1 "Step 1" 2 "Step 2" 3 "Step 3" 4 "Step 4" 5 "Step 5" 6 "Step 6" 7 "Step 7" 8 "Step 8" 9 "Step 9" 10 "Step 10" 11 "Step 11" 12 "Step 12" 13 "Step 13" 14 "Step 14" 15 "Step 15" 16 "Step 16" 17 "Step 17" 18 "Step 18" 19 "Step 19" 20 "Step 20 (Reset Value)" 21 "Step 21 (Detent)" ;
VAL_ 426 CLU_DisSpdVal 1023 "Error" ;
VAL_ 426 CLU_OKSwSta 0 "Off" 1 "Key On" 2 "Reserved" 3 "Invalid" ;
VAL_ 426 CLU_DisSpdVal_KPH 511 "Error" ;
VAL_ 549 CLU_RefuelWrnSta 0 "Refuel Popup is off" 1 "Refuel Popup is on" 2 "Reserved" 3 "Invalid" ;
VAL_ 549 CLU_DrvngModSwSta 0 "Off" 1 "Normal" 2 "Eco" 3 "Sport" 4 "Sport+" 5 "Smart" 6 "Custom" 7 "N-mode" 8 "Reserved" 9 "Reserved" 10 "Reserved" 11 "Reserved" 12 "Reserved" 13 "Reserved" 14 "Reserved" 15 "Reserved" ;
VAL_ 549 CLU_FuelLvlSta 0 "0x0x0~0x64:0%~100%" 100 "0x0x0~0x64:0%~100%" 101 "Reserved" 102 "Reserved" 103 "Reserved" 104 "Reserved" 105 "Reserved" 106 "Reserved" 107 "Reserved" 108 "Reserved" 109 "Reserved" 110 "Reserved" 111 "Reserved" 112 "Reserved" 113 "Reserved" 114 "Reserved" 115 "Reserved" 116 "Reserved" 117 "Reserved" 118 "Reserved" 119 "Reserved" 120 "Reserved" 121 "Reserved" 122 "Reserved" 123 "Reserved" 124 "Reserved" 125 "Reserved" 126 "Reserved" 127 "Invalid(Error)" ;
VAL_ 549 CLU_OutTempFSta 0 "0x0x0~0xB4:-40~140℉" 180 "0x0x0~0xB4:-40~140℉" 181 "Reserved" 182 "Reserved" 183 "Reserved" 184 "Reserved" 185 "Reserved" 186 "Reserved" 187 "Reserved" 188 "Reserved" 189 "Reserved" 190 "Reserved" 191 "Reserved" 192 "Reserved" 193 "Reserved" 194 "Reserved" 195 "Reserved" 196 "Reserved" 197 "Reserved" 198 "Reserved" 199 "Reserved" 200 "Reserved" 201 "Reserved" 202 "Reserved" 203 "Reserved" 204 "Reserved" 205 "Reserved" 206 "Reserved" 207 "Reserved" 208 "Reserved" 209 "Reserved" 210 "Reserved" 211 "Reserved" 212 "Reserved" 213 "Reserved" 214 "Reserved" 215 "Reserved" 216 "Reserved" 217 "Reserved" 218 "Reserved" 219 "Reserved" 220 "Reserved" 221 "Reserved" 222 "Reserved" 223 "Reserved" 224 "Reserved" 225 "Reserved" 226 "Reserved" 227 "Reserved" 228 "Reserved" 229 "Reserved" 230 "Reserved" 231 "Reserved" 232 "Reserved" 233 "Reserved" 234 "Reserved" 235 "Reserved" 236 "Reserved" 237 "Reserved" 238 "Reserved" 239 "Reserved" 240 "Reserved" 241 "Reserved" 242 "Reserved" 243 "Reserved" 244 "Reserved" 245 "Reserved" 246 "Reserved" 247 "Reserved" 248 "Reserved" 249 "Reserved" 250 "Reserved" 251 "Reserved" 252 "Reserved" 253 "Reserved" 254 "Reserved" 255 "Invalid" ;
VAL_ 549 CLU_TerrainModSwSta 0 "Default" 1 "Snow" 2 "Sand" 3 "Mud" 4 "Reserved" 5 "Reserved" 6 "Reserved" 7 "Reserved" ;
VAL_ 549 CLU_OutTempCSta 0 "0x0x0~0x64:-40~60℃" 100 "0x0x0~0x64:-40~60℃" 101 "0x65~0xFE:Reserved" 254 "0x65~0xFE:Reserved" 255 "Invalid" ;
VAL_ 549 CLU_TripUnitSta 0 "Not Used" 1 "km" 2 "mile" 3 "Invailid" ;
VAL_ 549 CLU_AvgFuelCnsmptnVal 1023 "Error" ;
VAL_ 549 CLU_AvgFuelCnsmptnUnitSta 0 "km/L" 1 "L/100km" 2 "MPG(US)" 3 "MPG(UK)" ;
VAL_ 549 CLU_LoFuelWrngSta 0 "Low fuel Warning is off" 1 "Low fuel Warning is on" 2 "Not used" 3 "Invalid" ;
VAL_ 549 CLU_RefuelDetSta 0 "Non refuel detected" 1 "Refuel detected" 2 "Not used" 3 "Error Indicator" ;
VAL_ 549 CLU_TerrainMainSwSta 0 "Default" 1 "On-Road" 2 "Off-Road" 3 "Reserved" ;
VAL_ 549 CLU_LngSta 0 "Off" 1 "Korean" 2 "English(US)" 3 "English(UK)" 4 "Chinese(Mandarin)" 5 "Chinese(Cantonese)" 6 "French(EU)" 7 "Spanish(EU)" 8 "Arabic" 9 "Czech" 10 "Danish" 11 "German" 12 "Italian" 13 "Dutch" 14 "Polish" 15 "Portuguese" 16 "Russian" 17 "Slovak" 18 "Swedish" 19 "Turkish" 20 "French(US)" 21 "Spanish(US)" 22 "Reserved" 23 "Reserved" 24 "Reserved" 25 "Reserved" 26 "Reserved" 27 "Reserved" 28 "Reserved" 29 "Reserved" 30 "Reserved" 31 "Invalid" ;
VAL_ 549 CLU_SRSWrngLmpSta 0 "Lamp OFF" 1 "Lamp On" 2 "Lamp Flashing" 3 "ACU message error" 7 "Lamp Circuit Failure" ;
VAL_ 549 CLU_OdoVal 16777215 "Error" ;
VAL_ 549 CLU_DawLastBrkTimeVal 0 "Value x 30min (0~6.5hr)" 1 "Value x 30min (0~6.5hr)" 2 "Value x 30min (0~6.5hr)" 3 "Value x 30min (0~6.5hr)" 4 "Value x 30min (0~6.5hr)" 5 "Value x 30min (0~6.5hr)" 6 "Value x 30min (0~6.5hr)" 7 "Value x 30min (0~6.5hr)" 8 "Value x 30min (0~6.5hr)" 9 "Value x 30min (0~6.5hr)" 10 "Value x 30min (0~6.5hr)" 11 "Value x 30min (0~6.5hr)" 12 "Value x 30min (0~6.5hr)" 13 "Value x 30min (0~6.5hr)" 14 "7hr or more" 15 "Invalid" ;
VAL_ 1233 USM_StaRst1Req 0 "Defualt" 1 "Reset" 2 "Not used" 3 "Error Indicator" ;
VAL_ 1235 USM_AutoDrLkSetReq 0 "Default" 1 "Off" 2 "Vehicle Speed On (15Km)" 3 "Shift Lever On" 4 "Invalid" ;
VAL_ 1235 USM_AutoDrUnlckSetReq 0 "Default" 1 "Off" 2 "Key Out On (AllDoors)" 3 "Shift Lever On (AllDoors)" 4 "Override" 5 "Invalid" 6 "Key Out On (Driver Door)" 7 "Shift Lever On (Driver Door)" ;
VAL_ 1235 USM_HLmpEscrtSetReq 0 "Default Value" 1 "Escort Off" 2 "Escort On" 3 "Invalid" ;
VAL_ 1235 USM_SmrtTrnkSetReq 0 "Default" 1 "HandsFree Off" 2 "HandsFree On" 3 "Reserved" 4 "Invalid" ;
VAL_ 1235 USM_HrnAnswerBckSetReq 0 "Default" 1 "Arm Disarm Buzzer Off" 2 "Arm Disarm Buzzer On" 3 "Invalid" ;
VAL_ 1235 USM_OneTouchTrplTrnSetReq 0 "Default" 1 "One Touch Turn Off" 2 "3 Flashing" 3 "5 Flashing" 4 "7 Flashing" 5 "Invalid" 6 "Reserved" 7 "Reserved" ;
VAL_ 1235 USM_PsmSetReq 0 "Default" 1 "Off (Disable)" 2 "50mmOn (Enable)" 3 "75mmOn (Enable)" 4 "Reserved" 5 "Reserved" 6 "Reserved" 7 "Invalid" ;
VAL_ 1235 USM_PtgmSetReq 0 "Default" 1 "Power Mode" 2 "Manual Mode" 3 "Invalid" ;
VAL_ 1235 USM_OSTempUnitSetReq 0 "Default" 1 "Centigrade(℃)" 2 "Fahrenheit(℉)" 3 "Invalid" ;
VAL_ 1235 USM_WALModSetreq 0 "Default" 1 "Disable" 2 "Enable" 3 "Invalid" ;
VAL_ 1236 USM_TwoTrnUnlckSetReq 0 "Default" 1 "Disable" 2 "Enable" 3 "Invalid" ;
VAL_ 1236 USM_ECoastSetReq 0 "Default" 1 "Disable" 2 "Enable" 3 "Invalid" ;
VAL_ 1236 USM_ECoastingWrngSndSetReq 0 "Default" 1 "Disable" 2 "Enable" 3 "Invalid" ;
VAL_ 1236 USM_MdLmpBrgtnsSetReq 0 "Default" 1 "Off" 2 "step 1" 3 "step 2" 4 "step 3" 5 "step 4" 6 "reserved" 7 "Invalid" ;
VAL_ 1236 USM_TirePrsrUnitSetReq 0 "Default Value" 1 "psi" 2 "kpa" 3 "bar" 4 "Reserved" 5 "Reserved" 6 "Reserved" 7 "Invalid" ;
VAL_ 1236 USM_FuelGdRstReq 0 "Default" 1 "Reset Request" 2 "Not used" 3 "Error Indicator" ;
VAL_ 1242 USM_MdLmpClrSetReq 0 "Default" 1 "color 1" 2 "color 2" 3 "color 3" 4 "color 4" 5 "color 5" 6 "color 6" 7 "color 7" 8 "reserved" 9 "reserved" 10 "reserved" 11 "reserved" 12 "reserved" 13 "reserved" 14 "reserved" 15 "Invalid" ;
VAL_ 1242 USM_RrWiperRevSetReq 0 "Default" 1 "Rear Wiper(reverse) Off" 2 "Rear Wiper(reverse) On" 3 "Invalid" ;
VAL_ 1242 USM_RrStRemindSetReq 0 "Default" 1 "Off(Disable)" 2 "On(Enable)" 3 "Invalid" ;
VAL_ 1242 USM_RrWpcSetReq 0 "Default" 1 "Off(Disable)" 2 "On(Enable)" 3 "Invalid" ;
VAL_ 1242 USM_WpcSetReq 0 "Default" 1 "Off(Disable)" 2 "On(Enable)" 3 "Invalid" ;
VAL_ 1242 USM_UnlckWlcmSetReq 0 "Default Value" 1 "Off" 2 "On" 3 "Invalid" ;
VAL_ 1242 USM_SmrtWlcmSetReq 0 "Default Value" 1 "Off" 2 "On" 3 "Invalid" ;
VAL_ 1242 USM_UipSetReq 0 "Default(USM미구성)" 1 "Off(Disable)" 2 "On(Enable)" 3 "Invalid" ;
VAL_ 1242 USM_DigitalKeyEnblSetReq 0 "Default(미구성)" 1 "Disable" 2 "Enable" 3 "Invalid" ;
VAL_ 1242 USM_OwnerPhnRegSetReq 0 "Default(미구성)" 1 "Deleter" 2 "Register" 3 "Invalid" ;
VAL_ 1242 USM_NFCCard1RegSetReq 0 "Default(미구성)" 1 "Disable" 2 "Enable" 3 "Invalid" ;
VAL_ 1242 USM_ProcStpReq 0 "Default" 1 "StopReq" ;
VAL_ 1243 USM_PtgSpdSetReq 0 "Default" 1 "Fast" 2 "Slow" 3 "Invalid" ;
VAL_ 1144 CLU_ICUDlvrModOffSetReq 0 "Default" 1 "OFF Request" 2 "Reserved" 3 "Invalid" ;
VAL_ 1144 CLU_DrvngLampChgnSta 0 "Reserved" 1 "Normal" 2 "Eco" 3 "Sport" 4 "Sport+" 5 "Smart" 6 "Custom" 7 "N-mode" 8 "Reserved" 9 "Reserved" 10 "Reserved" 11 "Reserved" 12 "Reserved" 13 "Reserved" 14 "Reserved" 15 "Reserved" ;
VAL_ 1144 CLU_TerrainModChgn 0 "Default" 1 "Snow" 2 "Sand" 3 "Mud" 4 "Reserved" 5 "Reserved" 6 "Reserved" 7 "Ready" ;
VAL_ 1144 CLU_ADASSetShortcut_Req 0 "Default" 1 "Menu On" 2 "Reserved" 3 "Invalid" ;
VAL_ 1144 CLU_SbwNModReq 0 "Off" 1 "N mode request" ;
VAL_ 1144 CLU_RrStRemindOffSetReq 0 "Default" 1 "Off Request" 2 "Reserved" 3 "Invalid" ;
VAL_ 1144 CLU_RrStRemindFdbckSetReq 0 "Off(Default)" 1 "On(1st ROA Alert On)" 2 "Reserved" 3 "Invalid" ;
VAL_ 1144 CF_Clu_HCSSOSStopReq 0 "Default" 1 "SOS Call Stop Req" 2 "Reserved" 3 "Invalid" ;
VAL_ 1145 USM_AdasUSMResetReq 0 "Default" 1 "Reset" 2 "Reserved" 3 "Invalid" ;
VAL_ 1145 USM_AdasFCASetReq 0 "Default(NoneFCA)" 1 "Off" 2 "Warning" 3 "Assist" 4 "Reserved" 5 "Reserved" 6 "Reserved" 7 "Invalid" ;
VAL_ 1145 USM_AdasBVMSetReq 0 "Default" 1 "BVM OFF" 2 "Turn Signal-BVM" 3 "BSD second signal-BVM" 4 "Reserved" 5 "Reserved" 6 "Reserved" 7 "Reserved" 8 "Reserved" 9 "Reserved" 10 "Reserved" 11 "Reserved" 12 "Reserved" 13 "Reserved" 14 "Reserved" 15 "Invalid" ;
VAL_ 1145 USM_AdasSCCDrvModSetReq 0 "Default" 1 "Comfort" 2 "Normal" 3 "Dynamic" 4 "Reserved" 5 "Reserved" 6 "Reserved" 7 "Invalid" ;
VAL_ 1145 USM_AdasDAWModSetReq 0 "Default" 1 "Off" 2 "Reserved" 3 "Normal" 4 "Early" 5 "Reserved" 6 "Reserved" 7 "Invalid" ;
VAL_ 1145 USM_AdasHDASetReq 0 "Default" 1 "Function Off" 2 "Function On" 3 "Invalid(Fail)" ;
VAL_ 1145 USM_AdasBCWSetReq 0 "Default" 1 "Off" 2 "Warning" 3 "Invalid" ;
VAL_ 1145 USM_AdasSEASetReq 0 "Default" 1 "Disable" 2 "Enable" 3 "Invalid" ;
VAL_ 1145 USM_AdasNSCCCamSetReq 0 "Default" 1 "Disable" 2 "Enable" 3 "Invalid" ;
VAL_ 1145 USM_AdasLFASetReq 0 "Default" 1 "Function Off" 2 "Function On" 3 "Invalid" ;
VAL_ 1145 USM_AdasBCASetReq 0 "Default" 1 "Off" 2 "Warning" 3 "Assist" 4 "Reserved" 5 "Reserved" 6 "Reserved" 7 "Invalid" ;
VAL_ 1145 USM_AdasWrngTimingSetReq 0 "Default" 1 "Late" 2 "Normal" 3 "Reserved" 4 "Reserved" 5 "Reserved" 6 "Reserved" 7 "Invliad" ;
VAL_ 1145 USM_AdasLVDASetReq 0 "Default" 1 "Off" 2 "On" 3 "Invalid" ;
VAL_ 1145 USM_AdasNSCCCrvSetReq 0 "Default" 1 "Disable" 2 "Enable" 3 "Invalid" ;
VAL_ 1135 USM_AdasBCWSndSetReq 0 "Default" 1 "Off" 2 "On" 3 "Invalid" ;
VAL_ 1135 USM_AdasRCCWSetReq 0 "Default" 1 "Off" 2 "Warning" 3 "Invalid" ;
VAL_ 1135 USM_AdasLkaModSetReq 0 "Default" 1 "LDW mode" 2 "LKA" 3 "Reserved" 4 "LDW only ON (None LKA)" 5 "LDW only OFF (None LKA)" 6 "LDW/LKA OFF" 7 "Invalid" ;
VAL_ 1135 USM_AdasFCAJnctnSetReq 0 "Default" 1 "Off" 2 "On" 3 "Invalid" ;
VAL_ 1135 USM_AdasHDALCFuncSetReq 0 "Default" 1 "Off" 2 "On" 3 "Invalid" ;
VAL_ 1135 USM_AdasPDWAutoOnSetReq 0 "Default" 1 "Off" 2 "On" 3 "Invalid" ;
VAL_ 1135 USM_AdasPCAStaSetReq 0 "Default" 1 "Off" 2 "Warning" 3 "Assist" 4 "Reserved" 5 "Reserved" 6 "Reserved" 7 "Invalid" ;
VAL_ 1135 USM_AdasHbaSetReq 0 "Default" 1 "Off" 2 "On" 3 "Invalid" ;
VAL_ 1135 USM_AdasSCCModeSetReq 0 "Default" 1 "Drive mode" 2 "SCC-ML" 3 "Invalid" ;
VAL_ 1135 USM_AdasSCCMLResetReq 0 "Default" 1 "Reset" 2 "Reserved" 3 "Invalid" ;
VAL_ 1135 USM_AdasDAWModNewSetReq 0 "Default" 1 "Off" 2 "On" 3 "Invalid" ;
VAL_ 1135 USM_AdasSVMAutoOnSetReq 0 "Default(미구성)" 1 "Disable(Off)" 2 "Enable(On)" 3 "Invalid" ;
VAL_ 1135 CLU_AdasDAWResetReq 0 "Default" 1 "ResetReq" 2 "Reserved" 3 "Invalid" ;
VAL_ 384 CLU_PddlUpSwSta 0 "Idle position" 1 "On" ;
VAL_ 384 CLU_PddlDnSwSta 0 "Idle position/" 1 "On" ;
VAL_ 256 ACC_CrsMainSwLmpSta 0 "Cruise MAIN switch indication lamp turn OFF" 1 "Cruise MAIN switch indication lamp turn ON" 2 "Not used" 3 "Error indicator" ;
VAL_ 256 ACC_CrsSetSwLmpSta 0 "Cruise SET switch indication lamp turn OFF" 1 "Cruise SET switch indication lamp turn ON" 2 "Not used" 3 "Error indicator" ;
VAL_ 256 ENG_DpfWrngSta 0 "DPF Normal State" 1 "DPF Warning State Level 1" 2 "DPF Warning State Level 2" 3 "Reserved" ;
VAL_ 256 ENG_BattWrngLmpSta 0 "Battery Warning Lamp OFF" 1 "Battery Warning Lamp ON" 2 "Not used" 3 "Error indicator" ;
VAL_ 256 ENG_OilPrsrWrngLmpSta 0 "Oil Pressure Warning Lamp OFF" 1 "Oil Pressure Warning Lamp ON" 2 "Not used" 3 "Error indicator" ;
VAL_ 256 ENG_EngClntTempVal 255 "Error indicator" ;
VAL_ 256 ENG_EngSta 0 "Engine Stop" 1 "Cranking" 2 "Stalled" 3 "Running" 4 "Reserved" 5 "Reserved" 6 "Reserved" 7 "Fault" ;
VAL_ 282 HBA_SysOptSta 0 "None HBA Option (Default)" 1 "HBA Option" 2 "Reserved" 3 "Error indicator" ;
VAL_ 282 HBA_SysSta 0 "HBA Disable" 1 "HBA Enable & High Beam Off" 2 "HBA Enable & High Beam On" 3 "Reserved" 4 "Reserved" 5 "Reserved" 6 "Reserved" 7 "System Fail" ;
VAL_ 282 HBA_IndLmpReq 0 "HBA Indicator Lamp Off" 1 "HBA Indicator Lamp On" 2 "Reserved" 3 "Error indicator" ;
VAL_ 282 DAW_LVDA_PUDis 0 "Default" 1 "Display “Leading vehicle departure alert”" 2 "Reserved" 3 "Error indicator" ;
VAL_ 282 DAW_LVDA_OptUsmSta 0 "No Option (default)" 1 "Off" 2 "On" 3 "Error Indicator" ;
VAL_ 282 DAW_OptUsmSta 0 "None DAW Option (Default)" 1 "System Off" 2 "System On" 3 "Reserved" 4 "Reserved" 5 "Reserved" 6 "Reserved" 7 "Invalid (Gray)" ;
VAL_ 282 DAW_SysSta 0 "System Off" 1 "Attention Level  1" 2 "Attention Level  2" 3 "Attention Level  3" 4 "Attention Level  4" 5 "Attention Level  5" 6 "Reserved" 7 "Reserved" 8 "Reserved" 9 "Reserved" 10 "Reserved" 11 "Reserved" 12 "Reserved" 13 "Reserved" 14 "System Standby" 15 "System Fail" ;
VAL_ 282 DAW_WrnMsgSta 0 "No Warning" 1 "Rest Recommend Warning" 2 "Reserved" 3 "Reserved" 4 "Reserved" 5 "Reserved" 6 "Reserved" 7 "Error indicator" ;
VAL_ 282 DAW_TimeRstReq 0 "No signal" 1 "Time reset" 2 "Reserved" 3 "Error indicator" ;
VAL_ 282 DAW_SnstvtyModRetVal 0 "Default" 1 "Late" 2 "Normal" 3 "Reserved" 4 "Reserved" 5 "Reserved" 6 "Reserved" 7 "Invalid" ;
VAL_ 934 PTGM_UsmSetSta 0 "Default" 1 "Power Mode" 2 "Manual Mode" 3 "Invalid" ;
VAL_ 934 PTGM_HeightSetWarn 0 "Display Off" 1 "Display On" ;
VAL_ 1252 RKE_BtnReq 0 "None" 1 "Lock" 2 "Unlock" 3 "Trunk(Or Tail Gate)" 4 "Panic" 5 "Panic Stop" 6 "0x6" 7 "Remote Cranking Stop" 8 "Remote Cranking Start" 9 "Forward(RSPA)" 10 "Backward/Parking(RSPA)" 11 "Pause(RSPA)" 12 "Trunk Hold(or Tailgate Hold)" 13 "Trunk Stop(or Tailgate Stop)" 14 "Not Used" 15 "Error Indicator" ;
VAL_ 442 BCW_Sta 0 "Default" 1 "System is Off" 2 "System Passive" 3 "System Active" 4 "System Failure" 5 "System Blockage" 6 "System minor failure" 7 "Reserved" 8 "Reserved" 9 "Reserved" 10 "Reserved" 11 "Reserved" 12 "Reserved" 13 "Reserved" 14 "Reserved" ;
VAL_ 442 BCW_LftIndSta 0 "Indicator output off" 1 "Indicator on (information)" 2 "Indicator blinking(warning)" 3 "Indicator output check" ;
VAL_ 442 BCW_RtIndSta 0 "Indicator output off" 1 "Indicator on (information)" 2 "Indicator blinking(warning)" 3 "Indicator output check" ;
VAL_ 442 BCW_LftSndWrngSta 0 "Speaker is Off" 1 "Speaker On" 2 "Not used" 3 "Error Indicator" ;
VAL_ 442 BCW_RtSndWrngSta 0 "Speaker is Off" 1 "Speaker On" 2 "Not used" 3 "Error Indicator" ;
VAL_ 442 BCW_SnstvtyModRetVal 0 "Default" 1 "Late" 2 "Normal" 3 "Early" 4 "Reserved" 5 "Reserved" 6 "Reserved" 7 "Invalid" ;
VAL_ 442 BCW_IndSta 0 "Default" 1 "Normal" 2 "Inidicator Failure" 3 "Reserved" ;
VAL_ 442 BCA_Sta 0 "Default" 1 "BCA Function is off" 2 "BCA Function is passive" 3 "BCA Function active" 4 "BCA Function failure" 5 "BCA Function Blockage" 6 ":BCA Function minor failure" 7 "Failure low priority" 8 "Reserved" 9 "Reserved" 10 "Reserved" 11 "Reserved" 12 "Reserved" 13 "Reserved" 14 "Reserved" ;
VAL_ 442 BCA_OnOffEquipSta 0 "Default" 1 "Off" 2 "Warning" 3 "Assist" 4 "Reserved" 5 "Reserved" 6 "Reserved" 7 "Invalid" ;
VAL_ 442 BCA_LftWrngSta 0 "BCA Left Warning is Off" 1 "BCA Left Warning is On" 2 "Not used" 3 "Error Indicator" ;
VAL_ 442 BCA_RtWrngSta 0 "BCA Right Warning is Off" 1 "BCA Right Warning is On" 2 "Not used" 3 "Error Indicator" ;
VAL_ 442 BCA_R_Brake_Warning 0 "No Warning" 1 "BCA Left Warning is On" 2 "BCA Right Warning is On" 3 "Left Control" 4 "Right Control" 5 "Reserved" 6 "Reserved" 7 "Error Indicator" ;
VAL_ 442 BCA_Plus_LftWrngSta 0 "BCA_Plus Left Warning is Off" 1 "BCA_Plus Left Warning is On" 2 "BCA_Plus Left Control is On" 3 "BCA_Plus Left Control is Ended" ;
VAL_ 442 BCA_Plus_RtWrngSta 0 "BCA_Plus Right Warning is Off" 1 "BCA_Plus Right Warning is On" 2 "BCA_Plus Right Control is On" 3 "BCA_Plus Right Control is Ended" ;
VAL_ 442 BCA_Plus_Sta 0 "Default" 1 "BCA Plus Function is off" 2 "BCA Plus Function is passive" 3 "BCA Plus Function active" 4 "BCA Plus Function failure" 5 "BCA Plus Function Blockage" 6 "BCA Plus Function minor failure" 7 "Reserved" 8 "Reserved" 9 "Reserved" 10 "Reserved" 11 "Reserved" 12 "Reserved" 13 "Reserved" 14 "Reserved" ;
VAL_ 304 SBW_SHFTR_FF_LvrWrngMsg 0 "Warning OFF" 1 "Gear Button Failure" 2 "P Release Button Failure" 3 "P Button Failure" 4 "D Button Failure" 5 "Reserved" 6 "Button Stuck Failure" 7 "Reserved" 8 "Reserved" 9 "Reserved" 10 "Reserved" 11 "Reserved" 12 "Reserved" 13 "Warning OFF(Lever type)" 14 "P Release Button Failure(Lever Type)" 15 "P Button Failure(Lever Type)" 16 "Button Stuck Failure(Lever Type)" 17 "P Button on & R/N/D signal on(Lever Type)" 18 "Lever Stuck" 19 "Lever Hall Sensor Failure" 20 "ECU HW Failure" 21 "Lever Hall Sensor Normal" 22 "Reserved" 23 "Reserved" 24 "Reserved" 25 "Reserved" 26 "Reserved" 27 "Reserved" 28 "Reserved" 29 "Reserved" 30 "Reserved" 31 "Reserved" ;
VAL_ 933 SCU_FF_WrnMsgClu 0 "No Warning message" 1 "Warning message 1" 2 "Warning message 2" 3 "Warning message 3" 4 "Warning message 4" 5 "Warning message 5" 6 "Warning message 6" 7 "Warning message 7" 8 "Warning message 8" 9 "Warning message 9" 10 "Warning message 10" 11 "Warning message 11" 12 "Warning message 12" 13 "Warning message 13" 14 "Reserved" 15 "Reserved" 16 "Reserved" 17 "Reserved" 19 "Reserved" ;
VAL_ 933 SCU_FF_NPosWshModSta 0 "Normal" 1 "Standby" 2 "N wash Mode" 3 "Reserved" ;
VAL_ 1253 DoorLock_PsvDrLkReq 0 "None" 1 "Lock" 2 "PassiveTrunkLock" 3 "Reserved" 4 "Reserved" 5 "Reseved" 6 "Not Used" 7 "Error Indicator" ;
VAL_ 1253 DoorLock_PsvDrUnLkReq 0 "None" 1 "UnLock" 2 "Unlock only DRV Door" 3 "PIC_Key_Reminder" 4 "Reserved" 5 "Reseved" 6 "Not Used" 7 "Error Indicator" ;
VAL_ 1092 SMK_AuthSta 0 "No Auth" 1 "Preauthentication" 2 "Authentication" 3 "Fast Restart" 4 "Reserved" 5 "Reseved" 6 "Not Used" 7 "Error Indicator" ;
VAL_ 1092 SMK_CLUAccIndOnReq 0 "Cluster ACC Indicator Off" 1 "Cluster ACC Indicator On" 2 "Not Used" 3 "Error Indicator" ;
VAL_ 928 TPMS_FLPosWrngLmpSta 0 "FL POSITION Warning lamp OFF" 1 "FL POSITION Warning lamp ON" 2 "Not used" 3 "Error Indicator" ;
VAL_ 928 TPMS_FRPosWrngLmpSta 0 "FR POSITION Warning lamp OFF" 1 "FR POSITION Warning lamp ON" 2 "Not used" 3 "Error Indicator" ;
VAL_ 928 TPMS_RLPosWrngLmpSta 0 "RL POSITION Warning lamp OFF" 1 "RL POSITION Warning lamp ON" 2 "Not used" 3 "Error Indicator" ;
VAL_ 928 TPMS_RRPosWrngLmpSta 0 "RR POSITION Warning lamp OFF" 1 "RR POSITION Warning lamp ON" 2 "Not used" 3 "Error Indicator" ;
VAL_ 928 TPMS_FLTirePrsrVal 255 "Error" ;
VAL_ 928 TPMS_FRTirePrsrVal 255 "Error" ;
VAL_ 928 TPMS_RLTirePrsrVal 255 "Error" ;
VAL_ 928 TPMS_RRTirePrsrVal 255 "Error" ;
VAL_ 928 TPMS_SnsrSta 0 "inactive" 1 "active" 2 "reserved" 3 "reserved" 4 "reserved" 5 "reserved" 6 "reserved" 7 "reserved" ;
VAL_ 928 TPMS_WrngLmpSta 0 "TPMS Malfunction Warning lamp OFF" 1 "TPMS Malfunction Warning lamp ON" 2 "TPMS Malfunction Warning lamp BLINKING(2Hz)" 3 "Error Indicator" ;
VAL_ 928 TPMS_TreadWrngLmpSta 0 "TREAD Warning lamp OFF" 1 "TREAD Warning lamp ON" 2 "TREAD Warning lamp BLINKING(2Hz)" 3 "Error Indicator" ;
VAL_ 928 TPMS_PrsrUnitSta 0 "psi" 1 "kpa" 2 "bar" 3 "Error Indicator" ;
VAL_ 160 WHL_SpdRRVal 16383 "Error" ;
VAL_ 160 WHL_SpdFLVal 16383 "Error" ;
VAL_ 160 WHL_SpdFRVal 16383 "Error" ;
VAL_ 160 WHL_SpdRLVal 16383 "Error" ;
VAL_ 1099 USM_CmdWPCSta 0 "Default" 1 "Off(Disable)" 2 "On(Enable)" 3 "Invalid" ;
VAL_ 1099 WPC_PhnLftWrngSta 0 "Off" 1 "Cellphone on the pad" 2 "Charging" 3 "Charging complete" 4 "Cellphone reminder" 5 "Error" 6 "Reserved" 7 "Invalid" ;
